VERSION "PropulsionCAN"

NS_ :

BS_ :

BU_ :  BECM CDD EGSM ETC IHU TMCU XCU ZCUD

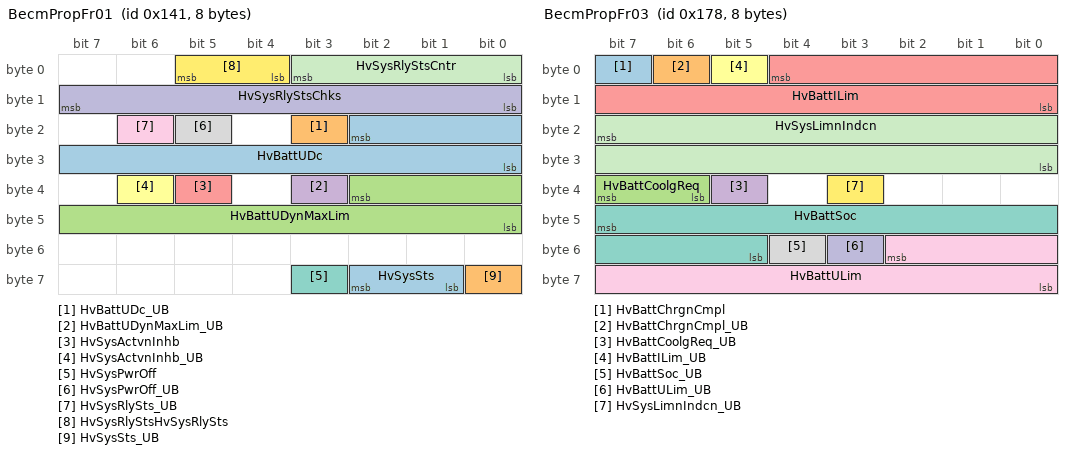
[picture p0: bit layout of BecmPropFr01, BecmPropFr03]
BO_ 321 BecmPropFr01 : 8 XCU
 SG_ HvBattUDc : 18|11@0+ (0.25,0.0) [0.0|511.0] "Volt" CDD,IHU
 SG_ HvBattUDc_UB : 19|1@0+ (1,0) [0|1] "" CDD,IHU
 SG_ HvBattUDynMaxLim : 34|11@0+ (0.25,0.0) [0.0|511.0] "Volt" IHU
 SG_ HvBattUDynMaxLim_UB : 35|1@0+ (1,0) [0|1] "" IHU
 SG_ HvSysActvnInhb : 37|1@0+ (1,0) [0|1] "" IHU
 SG_ HvSysActvnInhb_UB : 38|1@0+ (1,0) [0|1] "" IHU
 SG_ HvSysPwrOff : 59|1@0+ (1,0) [0|1] "" IHU
 SG_ HvSysPwrOff_UB : 21|1@0+ (1,0) [0|1] "" IHU
 SG_ HvSysRlySts_UB : 22|1@0+ (1,0) [0|1] "" BECM,CDD,IHU,ZCUD
 SG_ HvSysRlyStsChks : 15|8@0+ (1.0,0.0) [0.0|255.0] "Unitless" BECM,CDD,IHU,ZCUD
 SG_ HvSysRlyStsCntr : 3|4@0+ (1.0,0.0) [0.0|15.0] "Unitless" BECM,CDD,IHU,ZCUD
 SG_ HvSysRlyStsHvSysRlySts : 5|2@0+ (1,0) [0|3] "" BECM,CDD,IHU,ZCUD
 SG_ HvSysSts : 58|2@0+ (1,0) [0|3] "" IHU
 SG_ HvSysSts_UB : 56|1@0+ (1,0) [0|1] "" IHU

BO_ 373 BecmPropFr02 : 8 XCU
 SG_ HvBattUDynMinLim : 26|11@0+ (0.25,0.0) [0.0|511.0] "Volt" IHU
 SG_ HvBattUDynMinLim_UB : 27|1@0+ (1,0) [0|1] "" IHU
 SG_ MaintainBattTFb : 59|2@0+ (1,0) [0|3] "" IHU
 SG_ MaintainBattTFb_UB : 57|1@0+ (1,0) [0|1] "" IHU

BO_ 376 BecmPropFr03 : 8 XCU
 SG_ HvBattChrgnCmpl : 7|1@0+ (1,0) [0|1] "" CDD,IHU
 SG_ HvBattChrgnCmpl_UB : 6|1@0+ (1,0) [0|1] "" CDD,IHU
 SG_ HvBattCoolgReq : 39|2@0+ (1,0) [0|3] "" IHU
 SG_ HvBattCoolgReq_UB : 37|1@0+ (1,0) [0|1] "" IHU
 SG_ HvBattILim : 4|13@0+ (0.1,0.0) [0.0|819.1] "A" IHU
 SG_ HvBattILim_UB : 5|1@0+ (1,0) [0|1] "" IHU
 SG_ HvBattSoc : 47|11@0+ (0.05,0.0) [0.0|100.0] "%" IHU,ZCUD
 SG_ HvBattSoc_UB : 52|1@0+ (1,0) [0|1] "" IHU,ZCUD
 SG_ HvBattULim : 50|11@0+ (0.25,0.0) [0.0|511.0] "Volt" CDD,IHU
 SG_ HvBattULim_UB : 51|1@0+ (1,0) [0|1] "" CDD,IHU
 SG_ HvSysLimnIndcn : 23|16@0+ (1.0,0.0) [0.0|65535.0] "Unitless" IHU
 SG_ HvSysLimnIndcn_UB : 35|1@0+ (1,0) [0|1] "" IHU

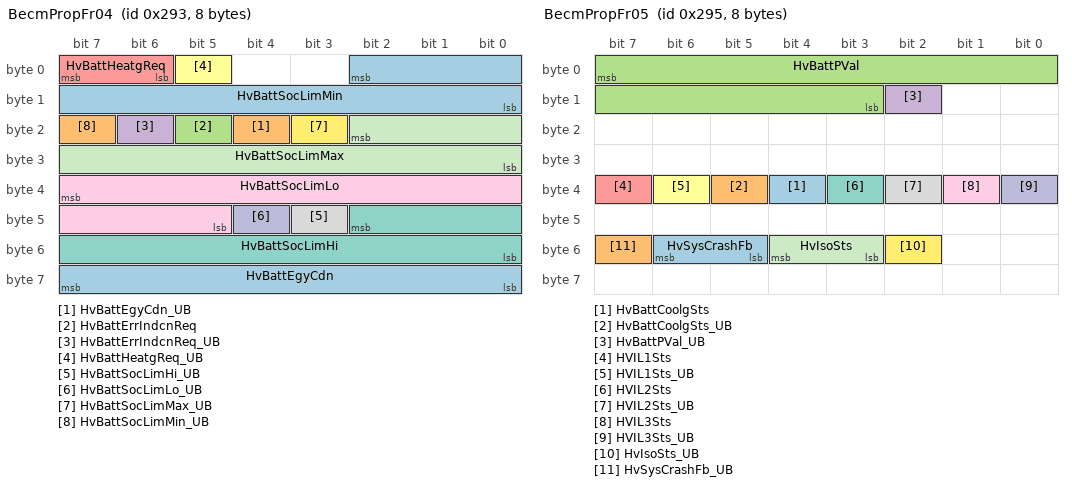
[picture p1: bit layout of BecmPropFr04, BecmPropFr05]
BO_ 659 BecmPropFr04 : 8 XCU
 SG_ HvBattEgyCdn : 63|8@0+ (0.5,0.0) [0.0|100.0] "%" IHU
 SG_ HvBattEgyCdn_UB : 20|1@0+ (1,0) [0|1] "" IHU
 SG_ HvBattErrIndcnReq : 21|1@0+ (1,0) [0|1] "" IHU
 SG_ HvBattErrIndcnReq_UB : 22|1@0+ (1,0) [0|1] "" IHU
 SG_ HvBattHeatgReq : 7|2@0+ (1,0) [0|3] "" IHU,ZCUD
 SG_ HvBattHeatgReq_UB : 5|1@0+ (1,0) [0|1] "" IHU,ZCUD
 SG_ HvBattSocLimHi : 42|11@0+ (0.05,0.0) [0.0|100.0] "%" IHU
 SG_ HvBattSocLimHi_UB : 43|1@0+ (1,0) [0|1] "" IHU
 SG_ HvBattSocLimLo : 39|11@0+ (0.05,0.0) [0.0|100.0] "%" IHU,ZCUD
 SG_ HvBattSocLimLo_UB : 44|1@0+ (1,0) [0|1] "" IHU,ZCUD
 SG_ HvBattSocLimMax : 18|11@0+ (0.05,0.0) [0.0|100.0] "%" IHU
 SG_ HvBattSocLimMax_UB : 19|1@0+ (1,0) [0|1] "" IHU
 SG_ HvBattSocLimMin : 2|11@0+ (0.05,0.0) [0.0|100.0] "%" IHU
 SG_ HvBattSocLimMin_UB : 23|1@0+ (1,0) [0|1] "" IHU

BO_ 661 BecmPropFr05 : 8 XCU
 SG_ HvBattCoolgSts : 36|1@0+ (1,0) [0|1] "" IHU
 SG_ HvBattCoolgSts_UB : 37|1@0+ (1,0) [0|1] "" IHU
 SG_ HvBattPVal : 7|13@0+ (0.05,0.0) [0.0|409.55] "KiloPa" Vector__XXX
 SG_ HvBattPVal_UB : 10|1@0+ (1,0) [0|1] "" Vector__XXX
 SG_ HVIL1Sts : 39|1@0+ (1,0) [0|1] "" Vector__XXX
 SG_ HVIL1Sts_UB : 38|1@0+ (1,0) [0|1] "" Vector__XXX
 SG_ HVIL2Sts : 35|1@0+ (1,0) [0|1] "" IHU
 SG_ HVIL2Sts_UB : 34|1@0+ (1,0) [0|1] "" IHU
 SG_ HVIL3Sts : 33|1@0+ (1,0) [0|1] "" IHU
 SG_ HVIL3Sts_UB : 32|1@0+ (1,0) [0|1] "" IHU
 SG_ HvIsoSts : 52|2@0+ (1,0) [0|3] "" IHU
 SG_ HvIsoSts_UB : 50|1@0+ (1,0) [0|1] "" IHU
 SG_ HvSysCrashFb : 54|2@0+ (1,0) [0|3] "" IHU,ZCUD
 SG_ HvSysCrashFb_UB : 55|1@0+ (1,0) [0|1] "" IHU,ZCUD

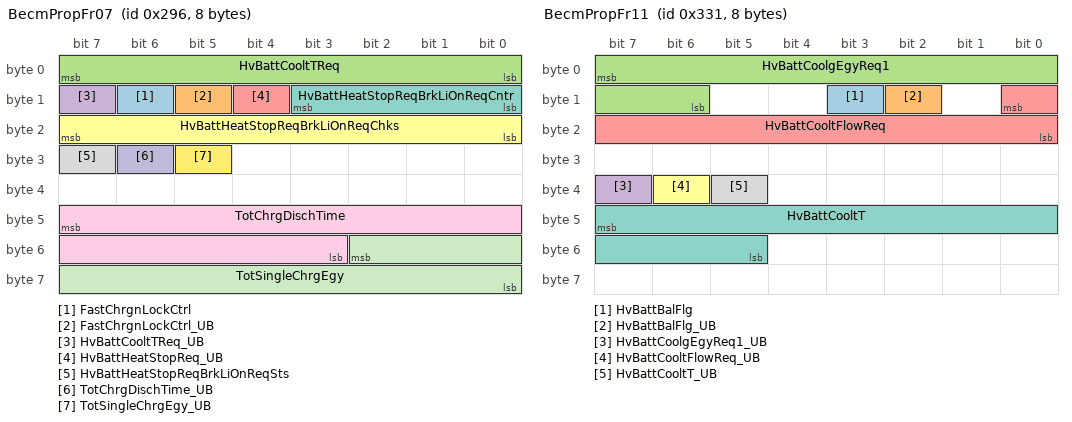
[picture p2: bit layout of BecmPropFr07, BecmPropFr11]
BO_ 662 BecmPropFr07 : 8 XCU
 SG_ FastChrgnLockCtrl : 14|1@0+ (1,0) [0|1] "" CDD,IHU
 SG_ FastChrgnLockCtrl_UB : 13|1@0+ (1,0) [0|1] "" CDD,IHU
 SG_ HvBattCooltTReq : 7|8@0+ (1.0,-50.0) [-50.0|200.0] "degC" IHU
 SG_ HvBattCooltTReq_UB : 15|1@0+ (1,0) [0|1] "" IHU
 SG_ HvBattHeatStopReq_UB : 12|1@0+ (1,0) [0|1] "" IHU
 SG_ HvBattHeatStopReqBrkLiOnReqChks : 23|8@0+ (1.0,0.0) [0.0|255.0] "Unitless" IHU
 SG_ HvBattHeatStopReqBrkLiOnReqCntr : 11|4@0+ (1.0,0.0) [0.0|15.0] "Unitless" IHU
 SG_ HvBattHeatStopReqBrkLiOnReqSts : 31|1@0+ (1,0) [0|1] "" IHU
 SG_ TotChrgDischTime : 47|13@0+ (1.0,0.0) [0.0|8191.0] "Unitless" IHU
 SG_ TotChrgDischTime_UB : 30|1@0+ (1,0) [0|1] "" IHU
 SG_ TotSingleChrgEgy : 50|11@0+ (0.1,0.0) [0.0|204.70000000000002] "KwH_1" IHU
 SG_ TotSingleChrgEgy_UB : 29|1@0+ (1,0) [0|1] "" IHU

BO_ 834 BecmPropFr08 : 8 XCU
 SG_ HvBattCodLen : 23|8@0+ (1.0,0.0) [0.0|250.0] "Unitless" IHU
 SG_ HvBattCodLen_UB : 39|1@0+ (1,0) [0|1] "" IHU
 SG_ HvBattMismatchFlt : 7|1@0+ (1,0) [0|1] "" IHU
 SG_ HvBattMismatchFlt_UB : 38|1@0+ (1,0) [0|1] "" IHU
 SG_ HvBattNr : 31|8@0+ (1.0,0.0) [0.0|250.0] "Unitless" IHU
 SG_ HvBattNr_UB : 37|1@0+ (1,0) [0|1] "" IHU
 SG_ HvCellTDifFlt : 6|2@0+ (1,0) [0|3] "" IHU
 SG_ HvCellTDifFlt_UB : 4|1@0+ (1,0) [0|1] "" IHU
 SG_ HvCellTOverFlt : 55|2@0+ (1,0) [0|3] "" IHU
 SG_ HvCellTOverFlt_UB : 35|1@0+ (1,0) [0|1] "" IHU
 SG_ HvCellUDifFlt : 3|2@0+ (1,0) [0|3] "" IHU
 SG_ HvCellUDifFlt_UB : 1|1@0+ (1,0) [0|1] "" IHU
 SG_ HvCellUOverFlt : 53|2@0+ (1,0) [0|3] "" IHU
 SG_ HvCellUOverFlt_UB : 34|1@0+ (1,0) [0|1] "" IHU
 SG_ HvCellUUnderFlt : 15|2@0+ (1,0) [0|3] "" IHU
 SG_ HvCellUUnderFlt_UB : 33|1@0+ (1,0) [0|1] "" IHU
 SG_ HvilFlt : 0|1@0+ (1,0) [0|1] "" IHU
 SG_ HvilFlt_UB : 42|1@0+ (1,0) [0|1] "" IHU
 SG_ HvIsoFlt : 13|2@0+ (1,0) [0|3] "" IHU
 SG_ HvIsoFlt_UB : 41|1@0+ (1,0) [0|1] "" IHU
 SG_ HvPackOverChrgFlt : 11|2@0+ (1,0) [0|3] "" IHU
 SG_ HvPackOverChrgFlt_UB : 40|1@0+ (1,0) [0|1] "" IHU
 SG_ HvPackUOverFlt : 9|2@0+ (1,0) [0|3] "" IHU
 SG_ HvPackUOverFlt_UB : 36|1@0+ (1,0) [0|1] "" IHU
 SG_ HvPackUUnderFlt : 47|2@0+ (1,0) [0|3] "" IHU
 SG_ HvPackUUnderFlt_UB : 32|1@0+ (1,0) [0|1] "" IHU
 SG_ HvSocHiFlt : 63|2@0+ (1,0) [0|3] "" IHU
 SG_ HvSocHiFlt_UB : 48|1@0+ (1,0) [0|1] "" IHU
 SG_ HvSocHopFlt : 45|2@0+ (1,0) [0|3] "" IHU
 SG_ HvSocHopFlt_UB : 43|1@0+ (1,0) [0|1] "" IHU
 SG_ HvSocLoFlt : 51|2@0+ (1,0) [0|3] "" IHU
 SG_ HvSocLoFlt_UB : 49|1@0+ (1,0) [0|1] "" IHU

BO_ 789 BecmPropFr09 : 8 XCU
 SG_ HvBattChrgnSts : 56|1@0+ (1,0) [0|1] "" IHU
 SG_ HvBattChrgnSts_UB : 57|1@0+ (1,0) [0|1] "" IHU
 SG_ HvBattT_UB : 7|1@0+ (1,0) [0|1] "" IHU
 SG_ HvBattTAvg : 6|13@0- (0.1,0.0) [-256.0|255.9] "degC" IHU
 SG_ HvBattTMax : 9|13@0- (0.1,0.0) [-256.0|255.9] "degC" IHU
 SG_ HvBattTMin : 28|13@0- (0.1,0.0) [-256.0|255.9] "degC" IHU

BO_ 817 BecmPropFr11 : 8 XCU
 SG_ HvBattBalFlg : 11|1@0+ (1,0) [0|1] "" Vector__XXX
 SG_ HvBattBalFlg_UB : 10|1@0+ (1,0) [0|1] "" Vector__XXX
 SG_ HvBattCoolgEgyReq1 : 7|10@0+ (20.0,0.0) [0.0|20460.0] "Wh" IHU
 SG_ HvBattCoolgEgyReq1_UB : 39|1@0+ (1,0) [0|1] "" IHU
 SG_ HvBattCooltFlowReq : 8|9@0+ (0.1,0.0) [0.0|51.1] "L / min" IHU
 SG_ HvBattCooltFlowReq_UB : 38|1@0+ (1,0) [0|1] "" IHU
 SG_ HvBattCooltT : 47|11@0+ (0.1,-60.0) [-60.0|125.0] "degC" IHU
 SG_ HvBattCooltT_UB : 37|1@0+ (1,0) [0|1] "" IHU

BO_ 769 BecmPropFr12 : 8 XCU
 SG_ DCChaPwrAct : 50|11@0+ (0.25,0.0) [0.0|511.75] "kW" IHU
 SG_ DCChaPwrAct_UB : 51|1@0+ (1,0) [0|1] "" IHU
 SG_ HvBattPwrCdn : 7|8@0+ (0.5,0.0) [0.0|100.0] "%" IHU
 SG_ HvBattPwrCdn_UB : 15|1@0+ (1,0) [0|1] "" IHU

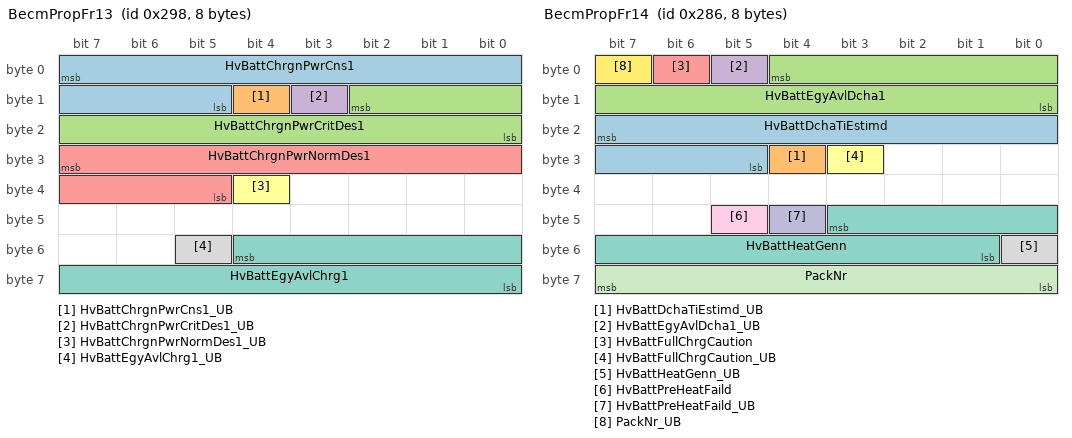
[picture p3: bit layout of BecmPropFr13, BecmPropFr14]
BO_ 664 BecmPropFr13 : 8 XCU
 SG_ HvBattChrgnPwrCns1 : 7|11@0+ (100.0,0.0) [0.0|204700.0] "W" IHU
 SG_ HvBattChrgnPwrCns1_UB : 12|1@0+ (1,0) [0|1] "" IHU
 SG_ HvBattChrgnPwrCritDes1 : 10|11@0+ (100.0,0.0) [0.0|204700.0] "W" IHU
 SG_ HvBattChrgnPwrCritDes1_UB : 11|1@0+ (1,0) [0|1] "" IHU
 SG_ HvBattChrgnPwrNormDes1 : 31|11@0+ (100.0,0.0) [0.0|204700.0] "W" IHU
 SG_ HvBattChrgnPwrNormDes1_UB : 36|1@0+ (1,0) [0|1] "" IHU
 SG_ HvBattEgyAvlChrg1 : 52|13@0+ (20.0,0.0) [0.0|163820.0] "Wh" IHU
 SG_ HvBattEgyAvlChrg1_UB : 53|1@0+ (1,0) [0|1] "" IHU

BO_ 646 BecmPropFr14 : 8 XCU
 SG_ HvBattDchaTiEstimd : 23|11@0+ (1.0,0.0) [0.0|2047.0] "Mins" IHU
 SG_ HvBattDchaTiEstimd_UB : 28|1@0+ (1,0) [0|1] "" IHU
 SG_ HvBattEgyAvlDcha1 : 4|13@0+ (20.0,0.0) [0.0|163820.0] "Wh" IHU
 SG_ HvBattEgyAvlDcha1_UB : 5|1@0+ (1,0) [0|1] "" IHU
 SG_ HvBattFullChrgCaution : 6|1@0+ (1,0) [0|1] "" IHU
 SG_ HvBattFullChrgCaution_UB : 27|1@0+ (1,0) [0|1] "" IHU
 SG_ HvBattHeatGenn : 43|11@0+ (100.0,0.0) [0.0|204700.0] "W" IHU
 SG_ HvBattHeatGenn_UB : 48|1@0+ (1,0) [0|1] "" IHU
 SG_ HvBattPreHeatFaild : 45|1@0+ (1,0) [0|1] "" IHU
 SG_ HvBattPreHeatFaild_UB : 44|1@0+ (1,0) [0|1] "" IHU
 SG_ PackNr : 63|8@0+ (1.0,0.0) [0.0|250.0] "Unitless" IHU
 SG_ PackNr_UB : 7|1@0+ (1,0) [0|1] "" IHU

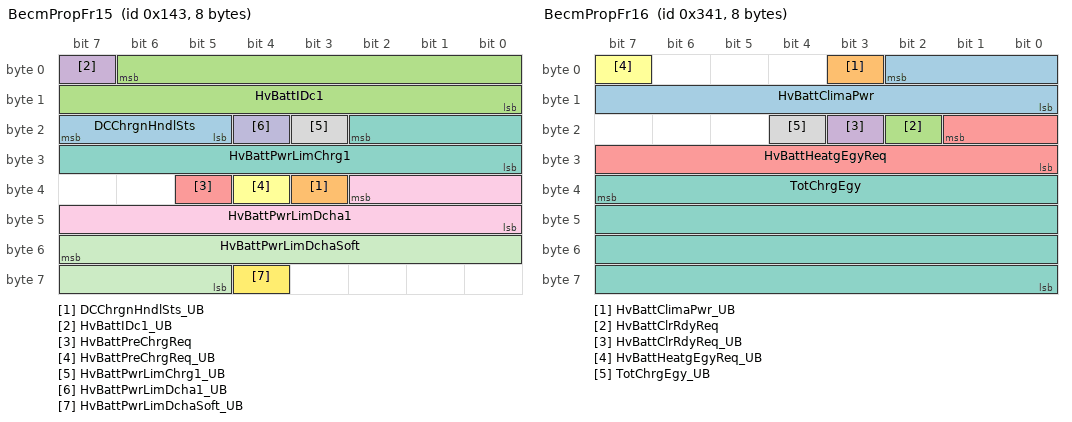
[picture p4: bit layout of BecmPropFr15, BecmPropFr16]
BO_ 323 BecmPropFr15 : 8 XCU
 SG_ DCChrgnHndlSts : 23|3@0+ (1,0) [0|7] "" IHU,ZCUD
 SG_ DCChrgnHndlSts_UB : 35|1@0+ (1,0) [0|1] "" IHU,ZCUD
 SG_ HvBattIDc1 : 6|15@0+ (0.1,-1638.0) [-1638.0|1638.7000000000003] "A" IHU
 SG_ HvBattIDc1_UB : 7|1@0+ (1,0) [0|1] "" IHU
 SG_ HvBattPreChrgReq : 37|1@0+ (1,0) [0|1] "" CDD
 SG_ HvBattPreChrgReq_UB : 36|1@0+ (1,0) [0|1] "" CDD
 SG_ HvBattPwrLimChrg1 : 18|11@0+ (0.25,0.0) [0.0|511.75] "kW" IHU
 SG_ HvBattPwrLimChrg1_UB : 19|1@0+ (1,0) [0|1] "" IHU
 SG_ HvBattPwrLimDcha1 : 34|11@0+ (0.25,0.0) [0.0|511.75] "kW" IHU
 SG_ HvBattPwrLimDcha1_UB : 20|1@0+ (1,0) [0|1] "" IHU
 SG_ HvBattPwrLimDchaSoft : 55|11@0+ (0.25,0.0) [0.0|511.75] "kW" IHU
 SG_ HvBattPwrLimDchaSoft_UB : 60|1@0+ (1,0) [0|1] "" IHU

BO_ 833 BecmPropFr16 : 8 XCU
 SG_ HvBattClimaPwr : 2|11@0+ (100.0,0.0) [0.0|204700.0] "W" IHU
 SG_ HvBattClimaPwr_UB : 3|1@0+ (1,0) [0|1] "" IHU
 SG_ HvBattClrRdyReq : 18|1@0+ (1,0) [0|1] "" IHU
 SG_ HvBattClrRdyReq_UB : 19|1@0+ (1,0) [0|1] "" IHU
 SG_ HvBattHeatgEgyReq : 17|10@0+ (20.0,0.0) [0.0|20460.0] "Wh" IHU
 SG_ HvBattHeatgEgyReq_UB : 7|1@0+ (1,0) [0|1] "" IHU
 SG_ TotChrgEgy : 39|32@0+ (1.0,0.0) [0.0|4294967295.0] "Unitless" Vector__XXX
 SG_ TotChrgEgy_UB : 20|1@0+ (1,0) [0|1] "" Vector__XXX

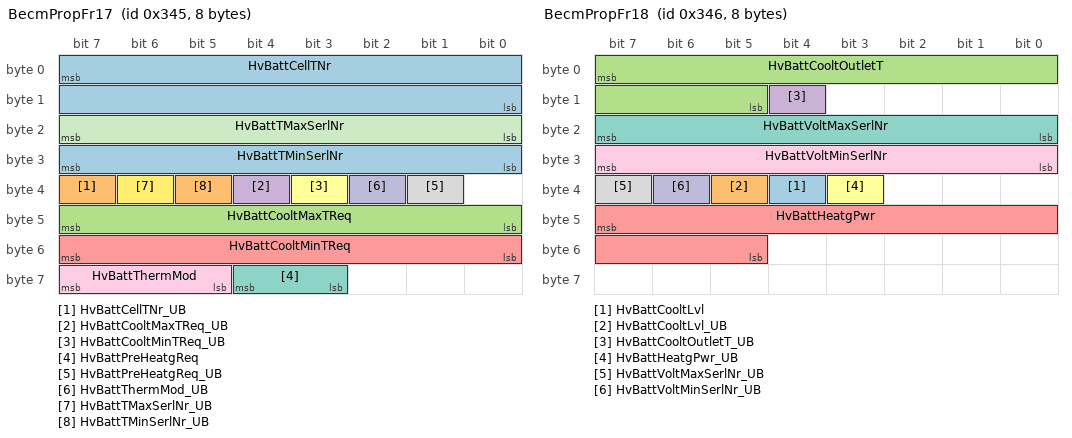
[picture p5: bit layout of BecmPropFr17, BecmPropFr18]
BO_ 837 BecmPropFr17 : 8 XCU
 SG_ HvBattCellTNr : 7|16@0+ (1.0,0.0) [0.0|65531.0] "Unitless" IHU
 SG_ HvBattCellTNr_UB : 39|1@0+ (1,0) [0|1] "" IHU
 SG_ HvBattCooltMaxTReq : 47|8@0+ (1.0,-50.0) [-50.0|200.0] "degC" IHU
 SG_ HvBattCooltMaxTReq_UB : 36|1@0+ (1,0) [0|1] "" IHU
 SG_ HvBattCooltMinTReq : 55|8@0+ (1.0,-50.0) [-50.0|200.0] "degC" IHU
 SG_ HvBattCooltMinTReq_UB : 35|1@0+ (1,0) [0|1] "" IHU
 SG_ HvBattPreHeatgReq : 60|2@0+ (1,0) [0|3] "" CDD,IHU
 SG_ HvBattPreHeatgReq_UB : 33|1@0+ (1,0) [0|1] "" CDD,IHU
 SG_ HvBattThermMod : 63|3@0+ (1,0) [0|7] "" IHU
 SG_ HvBattThermMod_UB : 34|1@0+ (1,0) [0|1] "" IHU
 SG_ HvBattTMaxSerlNr : 23|8@0+ (1.0,0.0) [0.0|250.0] "Unitless" IHU
 SG_ HvBattTMaxSerlNr_UB : 38|1@0+ (1,0) [0|1] "" IHU
 SG_ HvBattTMinSerlNr : 31|8@0+ (1.0,0.0) [0.0|250.0] "Unitless" Vector__XXX
 SG_ HvBattTMinSerlNr_UB : 37|1@0+ (1,0) [0|1] "" Vector__XXX

BO_ 838 BecmPropFr18 : 8 XCU
 SG_ HvBattCooltLvl : 36|1@0+ (1,0) [0|1] "" IHU
 SG_ HvBattCooltLvl_UB : 37|1@0+ (1,0) [0|1] "" IHU
 SG_ HvBattCooltOutletT : 7|11@0+ (0.1,-60.0) [-60.0|125.0] "degC" IHU
 SG_ HvBattCooltOutletT_UB : 12|1@0+ (1,0) [0|1] "" IHU
 SG_ HvBattHeatgPwr : 47|11@0+ (100.0,0.0) [0.0|204700.0] "W" IHU
 SG_ HvBattHeatgPwr_UB : 35|1@0+ (1,0) [0|1] "" IHU
 SG_ HvBattVoltMaxSerlNr : 23|8@0+ (1.0,0.0) [0.0|250.0] "Unitless" IHU
 SG_ HvBattVoltMaxSerlNr_UB : 39|1@0+ (1,0) [0|1] "" IHU
 SG_ HvBattVoltMinSerlNr : 31|8@0+ (1.0,0.0) [0.0|250.0] "Unitless" Vector__XXX
 SG_ HvBattVoltMinSerlNr_UB : 38|1@0+ (1,0) [0|1] "" Vector__XXX

BO_ 839 BecmPropFr19 : 8 XCU
 SG_ HvBattCod_UB : 63|1@0+ (1,0) [0|1] "" IHU
 SG_ HvBattCodPackCodeX1 : 7|8@0+ (1.0,0.0) [0.0|255.0] "Unitless" IHU
 SG_ HvBattCodPackCodeX2 : 15|8@0+ (1.0,0.0) [0.0|255.0] "Unitless" IHU
 SG_ HvBattCodPackCodeX3 : 23|8@0+ (1.0,0.0) [0.0|255.0] "Unitless" IHU
 SG_ HvBattCodPackCodeX4 : 31|8@0+ (1.0,0.0) [0.0|255.0] "Unitless" IHU
 SG_ HvBattCodPackCodeX5 : 39|8@0+ (1.0,0.0) [0.0|255.0] "Unitless" IHU
 SG_ HvBattCodPackCodeX6 : 47|8@0+ (1.0,0.0) [0.0|255.0] "Unitless" IHU
 SG_ HvBattCodPackIndex : 55|8@0+ (1.0,0.0) [0.0|255.0] "Unitless" IHU

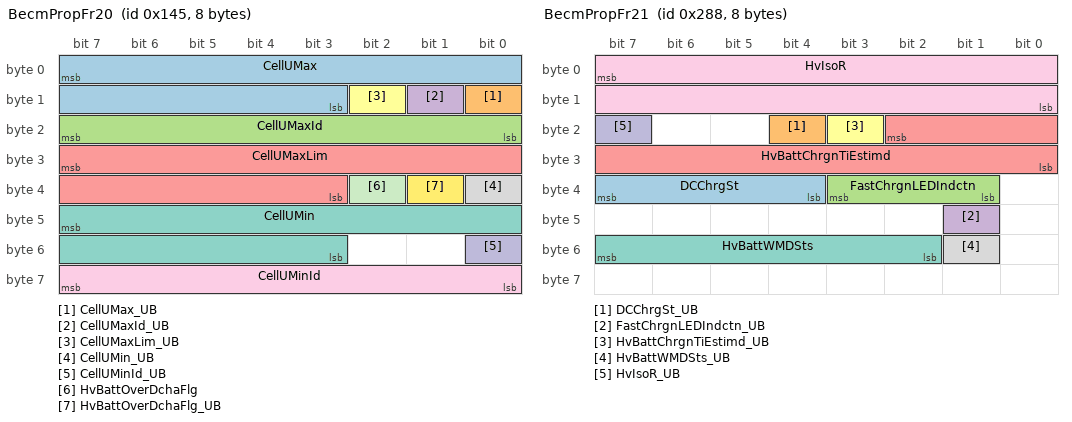
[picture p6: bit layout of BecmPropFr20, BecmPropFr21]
BO_ 325 BecmPropFr20 : 8 XCU
 SG_ CellUMax : 7|13@0+ (0.001,0.0) [0.0|5.0] "Volt" IHU
 SG_ CellUMax_UB : 8|1@0+ (1,0) [0|1] "" IHU
 SG_ CellUMaxId : 23|8@0+ (1.0,0.0) [0.0|250.0] "Unitless" IHU
 SG_ CellUMaxId_UB : 9|1@0+ (1,0) [0|1] "" IHU
 SG_ CellUMaxLim : 31|13@0+ (0.001,0.0) [0.0|5.0] "Volt" IHU
 SG_ CellUMaxLim_UB : 10|1@0+ (1,0) [0|1] "" IHU
 SG_ CellUMin : 47|13@0+ (0.001,0.0) [0.0|5.0] "Volt" IHU
 SG_ CellUMin_UB : 32|1@0+ (1,0) [0|1] "" IHU
 SG_ CellUMinId : 63|8@0+ (1.0,0.0) [0.0|250.0] "Unitless" IHU
 SG_ CellUMinId_UB : 48|1@0+ (1,0) [0|1] "" IHU
 SG_ HvBattOverDchaFlg : 34|1@0+ (1,0) [0|1] "" IHU
 SG_ HvBattOverDchaFlg_UB : 33|1@0+ (1,0) [0|1] "" IHU

BO_ 648 BecmPropFr21 : 8 XCU
 SG_ DCChrgSt : 39|4@0+ (1,0) [0|15] "" IHU,ZCUD
 SG_ DCChrgSt_UB : 20|1@0+ (1,0) [0|1] "" IHU,ZCUD
 SG_ FastChrgnLEDIndctn : 35|3@0+ (1,0) [0|7] "" CDD,IHU
 SG_ FastChrgnLEDIndctn_UB : 41|1@0+ (1,0) [0|1] "" CDD,IHU
 SG_ HvBattChrgnTiEstimd : 18|11@0+ (1.0,0.0) [0.0|2047.0] "Mins" IHU
 SG_ HvBattChrgnTiEstimd_UB : 19|1@0+ (1,0) [0|1] "" IHU
 SG_ HvBattWMDSts : 55|6@0+ (1.0,0.0) [0.0|63.0] "Unitless" IHU,ZCUD
 SG_ HvBattWMDSts_UB : 49|1@0+ (1,0) [0|1] "" IHU,ZCUD
 SG_ HvIsoR : 7|16@0+ (1.0,0.0) [0.0|60000.0] "kOhm" IHU
 SG_ HvIsoR_UB : 23|1@0+ (1,0) [0|1] "" IHU

BO_ 83 BecmPropFr22 : 8 XCU
 SG_ CPSRU : 39|8@0+ (0.1,0.0) [0.0|25.0] "Volt" IHU
 SG_ CPSRU_UB : 24|1@0+ (1,0) [0|1] "" IHU

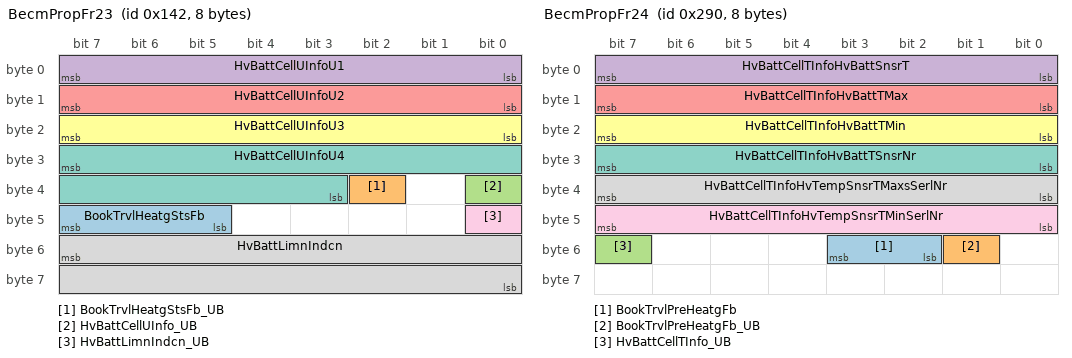
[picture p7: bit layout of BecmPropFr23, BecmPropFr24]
BO_ 322 BecmPropFr23 : 8 XCU
 SG_ BookTrvlHeatgStsFb : 47|3@0+ (1,0) [0|7] "" IHU
 SG_ BookTrvlHeatgStsFb_UB : 34|1@0+ (1,0) [0|1] "" IHU
 SG_ HvBattCellUInfo_UB : 32|1@0+ (1,0) [0|1] "" IHU
 SG_ HvBattCellUInfoU1 : 7|8@0+ (1.0,0.0) [0.0|255.0] "Unitless" IHU
 SG_ HvBattCellUInfoU2 : 15|8@0+ (1.0,0.0) [0.0|255.0] "Unitless" IHU
 SG_ HvBattCellUInfoU3 : 23|8@0+ (1.0,0.0) [0.0|255.0] "Unitless" IHU
 SG_ HvBattCellUInfoU4 : 31|13@0+ (1.0,0.0) [0.0|8191.0] "Unitless" IHU
 SG_ HvBattLimnIndcn : 55|16@0+ (1.0,0.0) [0.0|65535.0] "Unitless" IHU,ZCUD
 SG_ HvBattLimnIndcn_UB : 40|1@0+ (1,0) [0|1] "" IHU,ZCUD

BO_ 656 BecmPropFr24 : 8 XCU
 SG_ BookTrvlPreHeatgFb : 51|2@0+ (1,0) [0|3] "" IHU
 SG_ BookTrvlPreHeatgFb_UB : 49|1@0+ (1,0) [0|1] "" IHU
 SG_ HvBattCellTInfo_UB : 55|1@0+ (1,0) [0|1] "" IHU
 SG_ HvBattCellTInfoHvBattSnsrT : 7|8@0+ (1.0,-40.0) [-40.0|215.0] "degC" IHU
 SG_ HvBattCellTInfoHvBattTMax : 15|8@0+ (1.0,-40.0) [-40.0|215.0] "degC" IHU
 SG_ HvBattCellTInfoHvBattTMin : 23|8@0+ (1.0,-40.0) [-40.0|215.0] "degC" IHU
 SG_ HvBattCellTInfoHvBattTSnsrNr : 31|8@0+ (1.0,0.0) [0.0|255.0] "Unitless" IHU
 SG_ HvBattCellTInfoHvTempSnsrTMaxsSerlNr : 39|8@0+ (1.0,0.0) [0.0|255.0] "Unitless" IHU
 SG_ HvBattCellTInfoHvTempSnsrTMinSerlNr : 47|8@0+ (1.0,0.0) [0.0|255.0] "Unitless" IHU

BO_ 1177 BecmPropFr27 : 8 XCU
 SG_ HvBattCap : 7|16@0+ (0.1,0.0) [0.0|6553.5] "Ah" IHU
 SG_ HvBattCap_UB : 23|1@0+ (1,0) [0|1] "" IHU
 SG_ TotChrgCap : 39|32@0+ (0.01,0.0) [0.0|42949672.95] "Ah" Vector__XXX
 SG_ TotChrgCap_UB : 22|1@0+ (1,0) [0|1] "" Vector__XXX

BO_ 1180 BecmPropFr28 : 8 XCU
 SG_ TotDchaCap : 7|32@0+ (0.01,0.0) [0.0|42949672.95] "Ah" Vector__XXX
 SG_ TotDchaCap_UB : 39|1@0+ (1,0) [0|1] "" Vector__XXX

BO_ 1144 BecmPropFr30 : 8 XCU
 SG_ TotDchaEgy : 7|32@0+ (1.0,0.0) [0.0|4294967295.0] "Unitless" Vector__XXX
 SG_ TotDchaEgy_UB : 39|1@0+ (1,0) [0|1] "" Vector__XXX

BO_ 1155 BecmPropFr41 : 8 XCU
 SG_ Therunawy4GHS : 7|32@0+ (1.0,0.0) [0.0|4294967295.0] "Unitless" IHU
 SG_ Therunawy4GHS_UB : 39|1@0+ (1,0) [0|1] "" IHU

BO_ 407 BecmPropFr47 : 8 XCU
 SG_ BECMAFEComError : 7|1@0+ (1,0) [0|1] "" IHU
 SG_ BECMAFEComError_UB : 6|1@0+ (1,0) [0|1] "" IHU
 SG_ BECMBookTrvlHeatgReq : 5|2@0+ (1,0) [0|3] "" IHU
 SG_ BECMBookTrvlHeatgReq_UB : 3|1@0+ (1,0) [0|1] "" IHU
 SG_ BECMCurSampSts : 2|2@0+ (1.0,0.0) [0.0|3.0] "Unitless" IHU
 SG_ BECMCurSampSts_UB : 0|1@0+ (1,0) [0|1] "" IHU
 SG_ BECMCVSComFlt : 15|1@0+ (1,0) [0|1] "" IHU
 SG_ BECMCVSComFlt_UB : 14|1@0+ (1,0) [0|1] "" IHU
 SG_ BECMDCPreHeatgReq : 13|2@0+ (1,0) [0|3] "" IHU
 SG_ BECMDCPreHeatgReq_UB : 11|1@0+ (1,0) [0|1] "" IHU
 SG_ BECMHiVolSampSts : 10|3@0+ (1.0,0.0) [0.0|7.0] "Unitless" IHU
 SG_ BECMHiVolSampSts_UB : 23|1@0+ (1,0) [0|1] "" IHU
 SG_ BECMIsoCheckCmd : 22|1@0+ (1,0) [0|1] "" IHU
 SG_ BECMIsoCheckCmd_UB : 21|1@0+ (1,0) [0|1] "" IHU
 SG_ BECMMainNegCntSts : 20|2@0+ (1.0,0.0) [0.0|3.0] "Unitless" IHU
 SG_ BECMMainNegCntSts_UB : 18|1@0+ (1,0) [0|1] "" IHU
 SG_ BECMMainPosCntSts : 17|2@0+ (1.0,0.0) [0.0|3.0] "Unitless" IHU
 SG_ BECMMainPosCntSts_UB : 31|1@0+ (1,0) [0|1] "" IHU
 SG_ BECMPreChrgCntSts : 30|2@0+ (1.0,0.0) [0.0|3.0] "Unitless" IHU
 SG_ BECMPreChrgCntSts_UB : 28|1@0+ (1,0) [0|1] "" IHU
 SG_ BECMPwrLimtLvl : 39|16@0+ (1.0,0.0) [0.0|65535.0] "Unitless" IHU
 SG_ BECMPwrLimtLvl_UB : 27|1@0+ (1,0) [0|1] "" IHU
 SG_ BECMSupplyVoltKL30 : 55|8@0+ (1.0,0.0) [0.0|255.0] "Unitless" IHU
 SG_ BECMSupplyVoltKL30_UB : 26|1@0+ (1,0) [0|1] "" IHU
 SG_ BECMSysMod : 63|6@0+ (1.0,0.0) [0.0|63.0] "Unitless" IHU
 SG_ BECMSysMod_UB : 25|1@0+ (1,0) [0|1] "" IHU

BO_ 390 BecmPropFr48 : 8 XCU
 SG_ FIDChargerFault : 39|1@0+ (1,0) [0|1] "" IHU
 SG_ FIDChargerFault_UB : 16|1@0+ (1,0) [0|1] "" IHU
 SG_ FIDCRASHEVENT : 38|1@0+ (1,0) [0|1] "" IHU
 SG_ FIDCRASHEVENT_UB : 37|1@0+ (1,0) [0|1] "" IHU
 SG_ FIDCVTNUNSTABLE : 36|1@0+ (1,0) [0|1] "" IHU
 SG_ FIDCVTNUNSTABLE_UB : 35|1@0+ (1,0) [0|1] "" IHU
 SG_ FIDDONOTCONNECT : 34|1@0+ (1,0) [0|1] "" IHU
 SG_ FIDDONOTCONNECT_UB : 33|1@0+ (1,0) [0|1] "" IHU
 SG_ FIDECMSINGALMISS : 32|1@0+ (1,0) [0|1] "" IHU
 SG_ FIDECMSINGALMISS_UB : 47|1@0+ (1,0) [0|1] "" IHU
 SG_ FIDHvBattFaultIndcr : 46|1@0+ (1,0) [0|1] "" IHU
 SG_ FIDHvBattFaultIndcr_UB : 45|1@0+ (1,0) [0|1] "" IHU
 SG_ FIDHvPwrOff : 44|1@0+ (1,0) [0|1] "" IHU
 SG_ FIDHvPwrOff_UB : 43|1@0+ (1,0) [0|1] "" IHU
 SG_ FIDHVSOONUNAVAIL : 42|1@0+ (1,0) [0|1] "" IHU
 SG_ FIDHVSOONUNAVAIL_UB : 41|1@0+ (1,0) [0|1] "" IHU
 SG_ FIDInhibitNonbasicThrmReq : 40|1@0+ (1,0) [0|1] "" IHU
 SG_ FIDInhibitNonbasicThrmReq_UB : 55|1@0+ (1,0) [0|1] "" IHU
 SG_ FIDINHIBITSELFTEST : 54|1@0+ (1,0) [0|1] "" IHU
 SG_ FIDINHIBITSELFTEST_UB : 53|1@0+ (1,0) [0|1] "" IHU
 SG_ FIDInhibitThermalRequest : 52|1@0+ (1,0) [0|1] "" IHU
 SG_ FIDInhibitThermalRequest_UB : 51|1@0+ (1,0) [0|1] "" IHU
 SG_ FIDINSTANTDISCONNECTION : 50|1@0+ (1,0) [0|1] "" IHU
 SG_ FIDINSTANTDISCONNECTION_UB : 49|1@0+ (1,0) [0|1] "" IHU
 SG_ FIDLVFault : 48|1@0+ (1,0) [0|1] "" IHU
 SG_ FIDLVFault_UB : 63|1@0+ (1,0) [0|1] "" IHU
 SG_ FIDMPMCURDATA : 62|1@0+ (1,0) [0|1] "" IHU
 SG_ FIDMPMCURDATA_UB : 61|1@0+ (1,0) [0|1] "" IHU
 SG_ FIDMPMCVTNDATA : 60|1@0+ (1,0) [0|1] "" IHU
 SG_ FIDMPMCVTNDATA_UB : 59|1@0+ (1,0) [0|1] "" IHU
 SG_ FIDNOBalance : 58|1@0+ (1,0) [0|1] "" IHU
 SG_ FIDNOBalance_UB : 57|1@0+ (1,0) [0|1] "" IHU
 SG_ FIDNOCHARGING : 24|1@0+ (1,0) [0|1] "" IHU
 SG_ FIDNOCHARGING_UB : 56|1@0+ (1,0) [0|1] "" IHU
 SG_ FIDNOCONNECTION : 25|1@0+ (1,0) [0|1] "" IHU
 SG_ FIDNOCONNECTION_UB : 26|1@0+ (1,0) [0|1] "" IHU
 SG_ FIDNoDCCharging : 27|1@0+ (1,0) [0|1] "" IHU
 SG_ FIDNoDCCharging_UB : 28|1@0+ (1,0) [0|1] "" IHU
 SG_ FIDNoDischarging : 29|1@0+ (1,0) [0|1] "" IHU
 SG_ FIDNoDischarging_UB : 30|1@0+ (1,0) [0|1] "" IHU
 SG_ FIDNORESTARTMESSAGE : 31|1@0+ (1,0) [0|1] "" IHU
 SG_ FIDNORESTARTMESSAGE_UB : 17|1@0+ (1,0) [0|1] "" IHU
 SG_ FIDSevereDCChargerFault : 18|1@0+ (1,0) [0|1] "" IHU
 SG_ FIDSevereDCChargerFault_UB : 19|1@0+ (1,0) [0|1] "" IHU
 SG_ FIDSTOPSAFELY : 20|1@0+ (1,0) [0|1] "" IHU
 SG_ FIDSTOPSAFELY_UB : 21|1@0+ (1,0) [0|1] "" IHU
 SG_ FIDSYSTEMISOLATIONTEST : 22|1@0+ (1,0) [0|1] "" IHU
 SG_ FIDSYSTEMISOLATIONTEST_UB : 23|1@0+ (1,0) [0|1] "" IHU
 SG_ FIDUDCMODE : 8|1@0+ (1,0) [0|1] "" IHU
 SG_ FIDUDCMODE_UB : 9|1@0+ (1,0) [0|1] "" IHU

BO_ 404 BecmPropFr49 : 8 XCU
 SG_ BECMSwVersion : 7|21@0+ (1.0,0.0) [0.0|2097151.0] "Unitless" IHU
 SG_ BECMSwVersion_UB : 18|1@0+ (1,0) [0|1] "" IHU
 SG_ BECMUCPSRKL15 : 63|8@0+ (1.0,0.0) [0.0|255.0] "Unitless" IHU
 SG_ BECMUCPSRKL15_UB : 17|1@0+ (1,0) [0|1] "" IHU

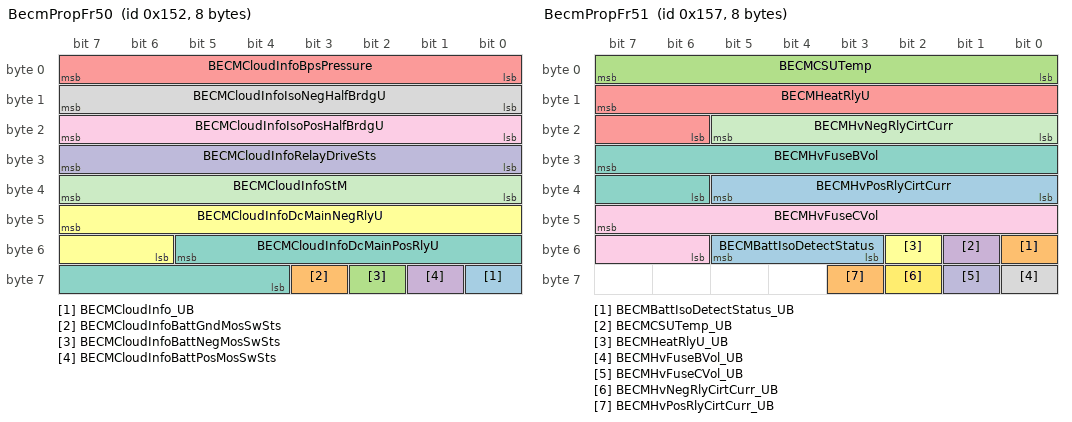
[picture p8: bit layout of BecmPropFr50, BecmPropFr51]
BO_ 338 BecmPropFr50 : 8 XCU
 SG_ BECMCloudInfo_UB : 56|1@0+ (1,0) [0|1] "" IHU
 SG_ BECMCloudInfoBattGndMosSwSts : 59|1@0+ (1,0) [0|1] "" IHU
 SG_ BECMCloudInfoBattNegMosSwSts : 58|1@0+ (1,0) [0|1] "" IHU
 SG_ BECMCloudInfoBattPosMosSwSts : 57|1@0+ (1,0) [0|1] "" IHU
 SG_ BECMCloudInfoBpsPressure : 7|8@0+ (1.0,0.0) [0.0|255.0] "Unitless" IHU
 SG_ BECMCloudInfoDcMainNegRlyU : 47|10@0+ (1.0,0.0) [0.0|1023.0] "Unitless" IHU
 SG_ BECMCloudInfoDcMainPosRlyU : 53|10@0+ (1.0,0.0) [0.0|1023.0] "Unitless" IHU
 SG_ BECMCloudInfoIsoNegHalfBrdgU : 15|8@0+ (1.0,0.0) [0.0|255.0] "Unitless" IHU
 SG_ BECMCloudInfoIsoPosHalfBrdgU : 23|8@0+ (1.0,0.0) [0.0|255.0] "Unitless" IHU
 SG_ BECMCloudInfoRelayDriveSts : 31|8@0+ (1.0,0.0) [0.0|255.0] "Unitless" IHU
 SG_ BECMCloudInfoStM : 39|8@0+ (1.0,0.0) [0.0|255.0] "Unitless" IHU

BO_ 343 BecmPropFr51 : 8 XCU
 SG_ BECMBattIsoDetectStatus : 53|3@0+ (1.0,0.0) [0.0|7.0] "Unitless" IHU
 SG_ BECMBattIsoDetectStatus_UB : 48|1@0+ (1,0) [0|1] "" IHU
 SG_ BECMCSUTemp : 7|8@0+ (1.0,0.0) [0.0|255.0] "Unitless" IHU
 SG_ BECMCSUTemp_UB : 49|1@0+ (1,0) [0|1] "" IHU
 SG_ BECMHeatRlyU : 15|10@0+ (1.0,0.0) [0.0|1023.0] "Unitless" IHU
 SG_ BECMHeatRlyU_UB : 50|1@0+ (1,0) [0|1] "" IHU
 SG_ BECMHvFuseBVol : 31|10@0+ (1.0,0.0) [0.0|1023.0] "Unitless" IHU
 SG_ BECMHvFuseBVol_UB : 56|1@0+ (1,0) [0|1] "" IHU
 SG_ BECMHvFuseCVol : 47|10@0+ (1.0,0.0) [0.0|1023.0] "Unitless" IHU
 SG_ BECMHvFuseCVol_UB : 57|1@0+ (1,0) [0|1] "" IHU
 SG_ BECMHvNegRlyCirtCurr : 21|6@0+ (1.0,0.0) [0.0|63.0] "Unitless" IHU
 SG_ BECMHvNegRlyCirtCurr_UB : 58|1@0+ (1,0) [0|1] "" IHU
 SG_ BECMHvPosRlyCirtCurr : 37|6@0+ (1.0,0.0) [0.0|63.0] "Unitless" IHU
 SG_ BECMHvPosRlyCirtCurr_UB : 59|1@0+ (1,0) [0|1] "" IHU

BO_ 348 BecmPropFr52 : 8 XCU
 SG_ BECMHvRelaySupplyU : 7|4@0+ (1.0,0.0) [0.0|15.0] "Unitless" IHU
 SG_ BECMHvRelaySupplyU_UB : 9|1@0+ (1,0) [0|1] "" IHU
 SG_ BECMLvHVIL1InputU : 15|6@0+ (1.0,0.0) [0.0|63.0] "Unitless" IHU
 SG_ BECMLvHVIL1InputU_UB : 8|1@0+ (1,0) [0|1] "" IHU
 SG_ BECMLvHVIL1OutputU : 31|6@0+ (1.0,0.0) [0.0|63.0] "Unitless" IHU
 SG_ BECMLvHVIL1OutputU_UB : 49|1@0+ (1,0) [0|1] "" IHU
 SG_ BECMLvHVIL2InputU : 25|6@0+ (1.0,0.0) [0.0|63.0] "Unitless" IHU
 SG_ BECMLvHVIL2InputU_UB : 48|1@0+ (1,0) [0|1] "" IHU
 SG_ BECMLvHVIL2OutputU : 35|6@0+ (1.0,0.0) [0.0|63.0] "Unitless" IHU
 SG_ BECMLvHVIL2OutputU_UB : 56|1@0+ (1,0) [0|1] "" IHU
 SG_ BECMLvHVIL3InputU : 45|6@0+ (1.0,0.0) [0.0|63.0] "Unitless" IHU
 SG_ BECMLvHVIL3InputU_UB : 57|1@0+ (1,0) [0|1] "" IHU
 SG_ BECMLvHVIL3OutputU : 55|6@0+ (1.0,0.0) [0.0|63.0] "Unitless" IHU
 SG_ BECMLvHVIL3OutputU_UB : 58|1@0+ (1,0) [0|1] "" IHU
 SG_ BECMMoflgErrHVConn : 3|1@0+ (1,0) [0|1] "" IHU
 SG_ BECMMoflgErrHVConn_UB : 59|1@0+ (1,0) [0|1] "" IHU
 SG_ BECMMoflgFrzHVConn : 2|1@0+ (1,0) [0|1] "" IHU
 SG_ BECMMoflgFrzHVConn_UB : 60|1@0+ (1,0) [0|1] "" IHU
 SG_ BECMMoflgFShOffOT : 1|1@0+ (1,0) [0|1] "" IHU
 SG_ BECMMoflgFShOffOT_UB : 61|1@0+ (1,0) [0|1] "" IHU
 SG_ BECMMoflgSShOffOT : 0|1@0+ (1,0) [0|1] "" IHU
 SG_ BECMMoflgSShOffOT_UB : 62|1@0+ (1,0) [0|1] "" IHU
 SG_ HvBattSOCE : 23|8@0+ (0.5,0.0) [0.0|100.0] "%" IHU
 SG_ HvBattSOCE_UB : 63|1@0+ (1,0) [0|1] "" IHU

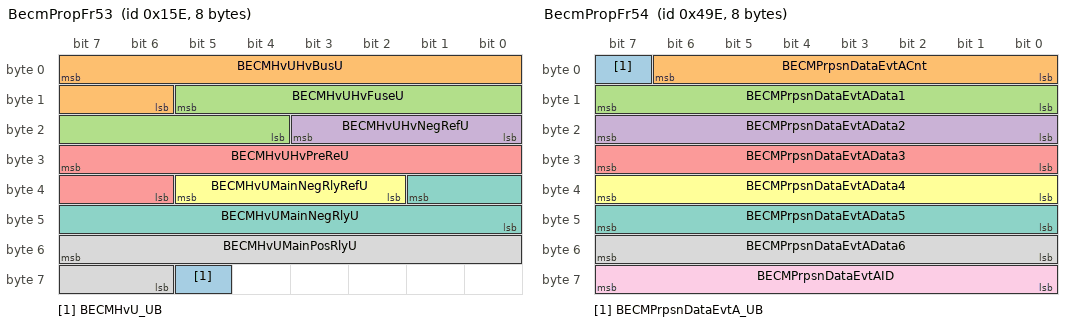
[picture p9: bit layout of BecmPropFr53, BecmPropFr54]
BO_ 350 BecmPropFr53 : 8 XCU
 SG_ BECMHvU_UB : 61|1@0+ (1,0) [0|1] "" IHU
 SG_ BECMHvUHvBusU : 7|10@0+ (1.0,0.0) [0.0|1023.0] "Unitless" IHU
 SG_ BECMHvUHvFuseU : 13|10@0+ (1.0,0.0) [0.0|1023.0] "Unitless" IHU
 SG_ BECMHvUHvNegRefU : 19|4@0+ (1.0,0.0) [0.0|15.0] "Unitless" IHU
 SG_ BECMHvUHvPreReU : 31|10@0+ (1.0,0.0) [0.0|1023.0] "Unitless" IHU
 SG_ BECMHvUMainNegRlyRefU : 37|4@0+ (1.0,0.0) [0.0|15.0] "Unitless" IHU
 SG_ BECMHvUMainNegRlyU : 33|10@0+ (1.0,0.0) [0.0|1023.0] "Unitless" IHU
 SG_ BECMHvUMainPosRlyU : 55|10@0+ (1.0,0.0) [0.0|1023.0] "Unitless" IHU

BO_ 1182 BecmPropFr54 : 8 XCU
 SG_ BECMPrpsnDataEvtA_UB : 7|1@0+ (1,0) [0|1] "" IHU
 SG_ BECMPrpsnDataEvtACnt : 6|7@0+ (1.0,0.0) [0.0|127.0] "Unitless" IHU
 SG_ BECMPrpsnDataEvtAData1 : 15|8@0+ (1.0,0.0) [0.0|255.0] "Unitless" IHU
 SG_ BECMPrpsnDataEvtAData2 : 23|8@0+ (1.0,0.0) [0.0|255.0] "Unitless" IHU
 SG_ BECMPrpsnDataEvtAData3 : 31|8@0+ (1.0,0.0) [0.0|255.0] "Unitless" IHU
 SG_ BECMPrpsnDataEvtAData4 : 39|8@0+ (1.0,0.0) [0.0|255.0] "Unitless" IHU
 SG_ BECMPrpsnDataEvtAData5 : 47|8@0+ (1.0,0.0) [0.0|255.0] "Unitless" IHU
 SG_ BECMPrpsnDataEvtAData6 : 55|8@0+ (1.0,0.0) [0.0|255.0] "Unitless" IHU
 SG_ BECMPrpsnDataEvtAID : 63|8@0+ (1.0,0.0) [0.0|255.0] "Unitless" IHU

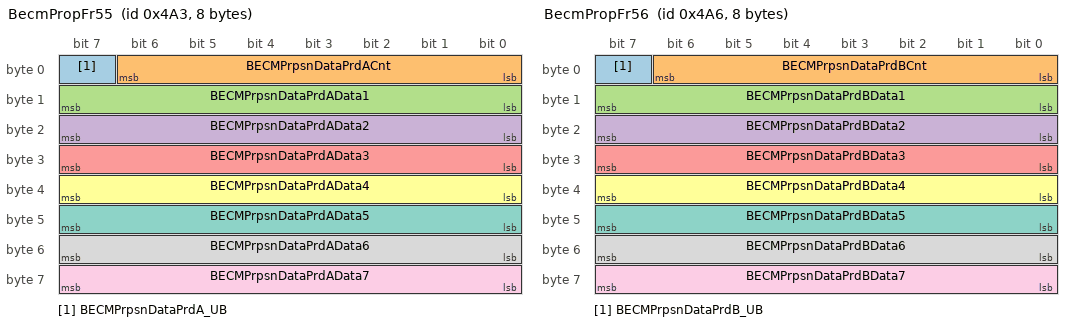
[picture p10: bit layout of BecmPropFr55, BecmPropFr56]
BO_ 1187 BecmPropFr55 : 8 XCU
 SG_ BECMPrpsnDataPrdA_UB : 7|1@0+ (1,0) [0|1] "" IHU
 SG_ BECMPrpsnDataPrdACnt : 6|7@0+ (1.0,0.0) [0.0|127.0] "Unitless" IHU
 SG_ BECMPrpsnDataPrdAData1 : 15|8@0+ (1.0,0.0) [0.0|255.0] "Unitless" IHU
 SG_ BECMPrpsnDataPrdAData2 : 23|8@0+ (1.0,0.0) [0.0|255.0] "Unitless" IHU
 SG_ BECMPrpsnDataPrdAData3 : 31|8@0+ (1.0,0.0) [0.0|255.0] "Unitless" IHU
 SG_ BECMPrpsnDataPrdAData4 : 39|8@0+ (1.0,0.0) [0.0|255.0] "Unitless" IHU
 SG_ BECMPrpsnDataPrdAData5 : 47|8@0+ (1.0,0.0) [0.0|255.0] "Unitless" IHU
 SG_ BECMPrpsnDataPrdAData6 : 55|8@0+ (1.0,0.0) [0.0|255.0] "Unitless" IHU
 SG_ BECMPrpsnDataPrdAData7 : 63|8@0+ (1.0,0.0) [0.0|255.0] "Unitless" IHU

BO_ 1190 BecmPropFr56 : 8 XCU
 SG_ BECMPrpsnDataPrdB_UB : 7|1@0+ (1,0) [0|1] "" IHU
 SG_ BECMPrpsnDataPrdBCnt : 6|7@0+ (1.0,0.0) [0.0|127.0] "Unitless" IHU
 SG_ BECMPrpsnDataPrdBData1 : 15|8@0+ (1.0,0.0) [0.0|255.0] "Unitless" IHU
 SG_ BECMPrpsnDataPrdBData2 : 23|8@0+ (1.0,0.0) [0.0|255.0] "Unitless" IHU
 SG_ BECMPrpsnDataPrdBData3 : 31|8@0+ (1.0,0.0) [0.0|255.0] "Unitless" IHU
 SG_ BECMPrpsnDataPrdBData4 : 39|8@0+ (1.0,0.0) [0.0|255.0] "Unitless" IHU
 SG_ BECMPrpsnDataPrdBData5 : 47|8@0+ (1.0,0.0) [0.0|255.0] "Unitless" IHU
 SG_ BECMPrpsnDataPrdBData6 : 55|8@0+ (1.0,0.0) [0.0|255.0] "Unitless" IHU
 SG_ BECMPrpsnDataPrdBData7 : 63|8@0+ (1.0,0.0) [0.0|255.0] "Unitless" IHU

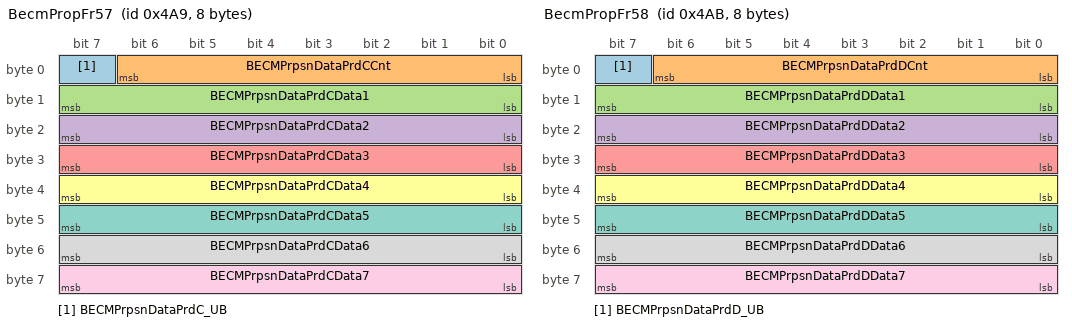
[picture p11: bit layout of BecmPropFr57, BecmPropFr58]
BO_ 1193 BecmPropFr57 : 8 XCU
 SG_ BECMPrpsnDataPrdC_UB : 7|1@0+ (1,0) [0|1] "" IHU
 SG_ BECMPrpsnDataPrdCCnt : 6|7@0+ (1.0,0.0) [0.0|127.0] "Unitless" IHU
 SG_ BECMPrpsnDataPrdCData1 : 15|8@0+ (1.0,0.0) [0.0|255.0] "Unitless" IHU
 SG_ BECMPrpsnDataPrdCData2 : 23|8@0+ (1.0,0.0) [0.0|255.0] "Unitless" IHU
 SG_ BECMPrpsnDataPrdCData3 : 31|8@0+ (1.0,0.0) [0.0|255.0] "Unitless" IHU
 SG_ BECMPrpsnDataPrdCData4 : 39|8@0+ (1.0,0.0) [0.0|255.0] "Unitless" IHU
 SG_ BECMPrpsnDataPrdCData5 : 47|8@0+ (1.0,0.0) [0.0|255.0] "Unitless" IHU
 SG_ BECMPrpsnDataPrdCData6 : 55|8@0+ (1.0,0.0) [0.0|255.0] "Unitless" IHU
 SG_ BECMPrpsnDataPrdCData7 : 63|8@0+ (1.0,0.0) [0.0|255.0] "Unitless" IHU

BO_ 1195 BecmPropFr58 : 8 XCU
 SG_ BECMPrpsnDataPrdD_UB : 7|1@0+ (1,0) [0|1] "" IHU
 SG_ BECMPrpsnDataPrdDCnt : 6|7@0+ (1.0,0.0) [0.0|127.0] "Unitless" IHU
 SG_ BECMPrpsnDataPrdDData1 : 15|8@0+ (1.0,0.0) [0.0|255.0] "Unitless" IHU
 SG_ BECMPrpsnDataPrdDData2 : 23|8@0+ (1.0,0.0) [0.0|255.0] "Unitless" IHU
 SG_ BECMPrpsnDataPrdDData3 : 31|8@0+ (1.0,0.0) [0.0|255.0] "Unitless" IHU
 SG_ BECMPrpsnDataPrdDData4 : 39|8@0+ (1.0,0.0) [0.0|255.0] "Unitless" IHU
 SG_ BECMPrpsnDataPrdDData5 : 47|8@0+ (1.0,0.0) [0.0|255.0] "Unitless" IHU
 SG_ BECMPrpsnDataPrdDData6 : 55|8@0+ (1.0,0.0) [0.0|255.0] "Unitless" IHU
 SG_ BECMPrpsnDataPrdDData7 : 63|8@0+ (1.0,0.0) [0.0|255.0] "Unitless" IHU

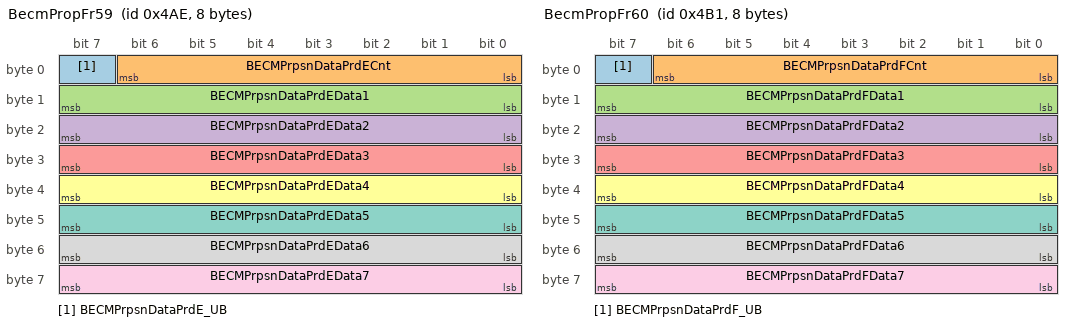
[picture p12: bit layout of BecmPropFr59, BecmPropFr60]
BO_ 1198 BecmPropFr59 : 8 XCU
 SG_ BECMPrpsnDataPrdE_UB : 7|1@0+ (1,0) [0|1] "" IHU
 SG_ BECMPrpsnDataPrdECnt : 6|7@0+ (1.0,0.0) [0.0|127.0] "Unitless" IHU
 SG_ BECMPrpsnDataPrdEData1 : 15|8@0+ (1.0,0.0) [0.0|255.0] "Unitless" IHU
 SG_ BECMPrpsnDataPrdEData2 : 23|8@0+ (1.0,0.0) [0.0|255.0] "Unitless" IHU
 SG_ BECMPrpsnDataPrdEData3 : 31|8@0+ (1.0,0.0) [0.0|255.0] "Unitless" IHU
 SG_ BECMPrpsnDataPrdEData4 : 39|8@0+ (1.0,0.0) [0.0|255.0] "Unitless" IHU
 SG_ BECMPrpsnDataPrdEData5 : 47|8@0+ (1.0,0.0) [0.0|255.0] "Unitless" IHU
 SG_ BECMPrpsnDataPrdEData6 : 55|8@0+ (1.0,0.0) [0.0|255.0] "Unitless" IHU
 SG_ BECMPrpsnDataPrdEData7 : 63|8@0+ (1.0,0.0) [0.0|255.0] "Unitless" IHU

BO_ 1201 BecmPropFr60 : 8 XCU
 SG_ BECMPrpsnDataPrdF_UB : 7|1@0+ (1,0) [0|1] "" IHU
 SG_ BECMPrpsnDataPrdFCnt : 6|7@0+ (1.0,0.0) [0.0|127.0] "Unitless" IHU
 SG_ BECMPrpsnDataPrdFData1 : 15|8@0+ (1.0,0.0) [0.0|255.0] "Unitless" IHU
 SG_ BECMPrpsnDataPrdFData2 : 23|8@0+ (1.0,0.0) [0.0|255.0] "Unitless" IHU
 SG_ BECMPrpsnDataPrdFData3 : 31|8@0+ (1.0,0.0) [0.0|255.0] "Unitless" IHU
 SG_ BECMPrpsnDataPrdFData4 : 39|8@0+ (1.0,0.0) [0.0|255.0] "Unitless" IHU
 SG_ BECMPrpsnDataPrdFData5 : 47|8@0+ (1.0,0.0) [0.0|255.0] "Unitless" IHU
 SG_ BECMPrpsnDataPrdFData6 : 55|8@0+ (1.0,0.0) [0.0|255.0] "Unitless" IHU
 SG_ BECMPrpsnDataPrdFData7 : 63|8@0+ (1.0,0.0) [0.0|255.0] "Unitless" IHU

BO_ 1203 BecmPropFr61 : 8 XCU
 SG_ BECMPrpsnDataPrdG_UB : 7|1@0+ (1,0) [0|1] "" IHU
 SG_ BECMPrpsnDataPrdGCnt : 6|7@0+ (1.0,0.0) [0.0|127.0] "Unitless" IHU
 SG_ BECMPrpsnDataPrdGData1 : 15|8@0+ (1.0,0.0) [0.0|255.0] "Unitless" IHU
 SG_ BECMPrpsnDataPrdGData2 : 23|8@0+ (1.0,0.0) [0.0|255.0] "Unitless" IHU
 SG_ BECMPrpsnDataPrdGData3 : 31|8@0+ (1.0,0.0) [0.0|255.0] "Unitless" IHU
 SG_ BECMPrpsnDataPrdGData4 : 39|8@0+ (1.0,0.0) [0.0|255.0] "Unitless" IHU
 SG_ BECMPrpsnDataPrdGData5 : 47|8@0+ (1.0,0.0) [0.0|255.0] "Unitless" IHU
 SG_ BECMPrpsnDataPrdGData6 : 55|8@0+ (1.0,0.0) [0.0|255.0] "Unitless" IHU
 SG_ BECMPrpsnDataPrdGData7 : 63|8@0+ (1.0,0.0) [0.0|255.0] "Unitless" IHU

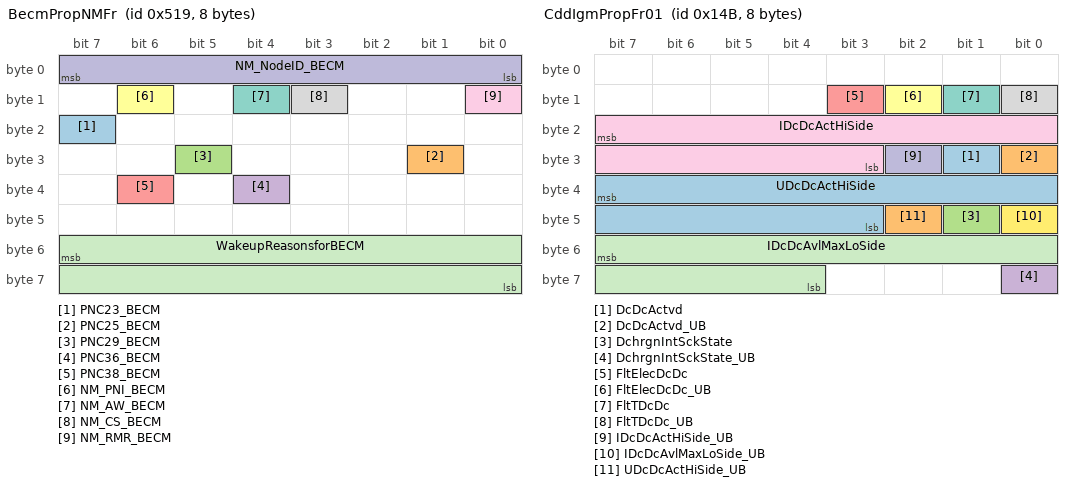
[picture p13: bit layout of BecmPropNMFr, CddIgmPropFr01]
BO_ 1305 BecmPropNMFr : 8 BECM
 SG_ PNC23_BECM : 23|1@0+ (1,0) [0|0] "" Vector__XXX
 SG_ PNC25_BECM : 25|1@0+ (1,0) [0|0] "" Vector__XXX
 SG_ PNC29_BECM : 29|1@0+ (1,0) [0|0] "" Vector__XXX
 SG_ PNC36_BECM : 36|1@0+ (1,0) [0|0] "" Vector__XXX
 SG_ PNC38_BECM : 38|1@0+ (1,0) [0|0] "" Vector__XXX
 SG_ NM_PNI_BECM : 14|1@0+ (1,0) [0|0] "" Vector__XXX
 SG_ NM_AW_BECM : 12|1@0+ (1,0) [0|0] "" Vector__XXX
 SG_ NM_CS_BECM : 11|1@0+ (1,0) [0|0] "" Vector__XXX
 SG_ NM_RMR_BECM : 8|1@0+ (1,0) [0|0] "" Vector__XXX
 SG_ NM_NodeID_BECM : 7|8@0+ (1,0) [0|0] "" Vector__XXX

 SG_ WakeupReasonsforBECM : 55|16@0+ (1,0) [0|65535] "" Vector__XXX

BO_ 1369 BecmPropVFCVectorFr : 8 BECM
 SG_ VFCVectorBECMBlockID : 1|2@0+ (1.0,0.0) [0.0|3.0] "Unitless" IHU
 SG_ VFCVectorBECMVFCid0 : 2|1@0+ (1,0) [0|1] "" IHU
 SG_ VFCVectorBECMVFCid1 : 3|1@0+ (1,0) [0|1] "" IHU
 SG_ VFCVectorBECMVFCid10 : 12|1@0+ (1,0) [0|1] "" IHU
 SG_ VFCVectorBECMVFCid11 : 13|1@0+ (1,0) [0|1] "" IHU
 SG_ VFCVectorBECMVFCid12 : 14|1@0+ (1,0) [0|1] "" IHU
 SG_ VFCVectorBECMVFCid13 : 15|1@0+ (1,0) [0|1] "" IHU
 SG_ VFCVectorBECMVFCid14 : 16|1@0+ (1,0) [0|1] "" IHU
 SG_ VFCVectorBECMVFCid15 : 17|1@0+ (1,0) [0|1] "" IHU
 SG_ VFCVectorBECMVFCid16 : 18|1@0+ (1,0) [0|1] "" IHU
 SG_ VFCVectorBECMVFCid17 : 19|1@0+ (1,0) [0|1] "" IHU
 SG_ VFCVectorBECMVFCid18 : 20|1@0+ (1,0) [0|1] "" IHU
 SG_ VFCVectorBECMVFCid19 : 21|1@0+ (1,0) [0|1] "" IHU
 SG_ VFCVectorBECMVFCid2 : 4|1@0+ (1,0) [0|1] "" IHU
 SG_ VFCVectorBECMVFCid20 : 22|1@0+ (1,0) [0|1] "" IHU
 SG_ VFCVectorBECMVFCid21 : 23|1@0+ (1,0) [0|1] "" IHU
 SG_ VFCVectorBECMVFCid22 : 24|1@0+ (1,0) [0|1] "" IHU
 SG_ VFCVectorBECMVFCid23 : 25|1@0+ (1,0) [0|1] "" IHU
 SG_ VFCVectorBECMVFCid24 : 26|1@0+ (1,0) [0|1] "" IHU
 SG_ VFCVectorBECMVFCid25 : 27|1@0+ (1,0) [0|1] "" IHU
 SG_ VFCVectorBECMVFCid26 : 28|1@0+ (1,0) [0|1] "" IHU
 SG_ VFCVectorBECMVFCid27 : 29|1@0+ (1,0) [0|1] "" IHU
 SG_ VFCVectorBECMVFCid28 : 30|1@0+ (1,0) [0|1] "" IHU
 SG_ VFCVectorBECMVFCid29 : 31|1@0+ (1,0) [0|1] "" IHU
 SG_ VFCVectorBECMVFCid3 : 5|1@0+ (1,0) [0|1] "" IHU
 SG_ VFCVectorBECMVFCid30 : 32|1@0+ (1,0) [0|1] "" IHU
 SG_ VFCVectorBECMVFCid31 : 33|1@0+ (1,0) [0|1] "" IHU
 SG_ VFCVectorBECMVFCid32 : 34|1@0+ (1,0) [0|1] "" IHU
 SG_ VFCVectorBECMVFCid33 : 35|1@0+ (1,0) [0|1] "" IHU
 SG_ VFCVectorBECMVFCid34 : 36|1@0+ (1,0) [0|1] "" IHU
 SG_ VFCVectorBECMVFCid35 : 37|1@0+ (1,0) [0|1] "" IHU
 SG_ VFCVectorBECMVFCid36 : 38|1@0+ (1,0) [0|1] "" IHU
 SG_ VFCVectorBECMVFCid37 : 39|1@0+ (1,0) [0|1] "" IHU
 SG_ VFCVectorBECMVFCid38 : 40|1@0+ (1,0) [0|1] "" IHU
 SG_ VFCVectorBECMVFCid39 : 41|1@0+ (1,0) [0|1] "" IHU
 SG_ VFCVectorBECMVFCid4 : 6|1@0+ (1,0) [0|1] "" IHU
 SG_ VFCVectorBECMVFCid40 : 42|1@0+ (1,0) [0|1] "" IHU
 SG_ VFCVectorBECMVFCid41 : 43|1@0+ (1,0) [0|1] "" IHU
 SG_ VFCVectorBECMVFCid42 : 44|1@0+ (1,0) [0|1] "" IHU
 SG_ VFCVectorBECMVFCid43 : 45|1@0+ (1,0) [0|1] "" IHU
 SG_ VFCVectorBECMVFCid44 : 46|1@0+ (1,0) [0|1] "" IHU
 SG_ VFCVectorBECMVFCid45 : 47|1@0+ (1,0) [0|1] "" IHU
 SG_ VFCVectorBECMVFCid46 : 48|1@0+ (1,0) [0|1] "" IHU
 SG_ VFCVectorBECMVFCid47 : 49|1@0+ (1,0) [0|1] "" IHU
 SG_ VFCVectorBECMVFCid48 : 50|1@0+ (1,0) [0|1] "" IHU
 SG_ VFCVectorBECMVFCid49 : 51|1@0+ (1,0) [0|1] "" IHU
 SG_ VFCVectorBECMVFCid5 : 7|1@0+ (1,0) [0|1] "" IHU
 SG_ VFCVectorBECMVFCid50 : 52|1@0+ (1,0) [0|1] "" IHU
 SG_ VFCVectorBECMVFCid51 : 53|1@0+ (1,0) [0|1] "" IHU
 SG_ VFCVectorBECMVFCid52 : 54|1@0+ (1,0) [0|1] "" IHU
 SG_ VFCVectorBECMVFCid53 : 55|1@0+ (1,0) [0|1] "" IHU
 SG_ VFCVectorBECMVFCid54 : 56|1@0+ (1,0) [0|1] "" IHU
 SG_ VFCVectorBECMVFCid55 : 57|1@0+ (1,0) [0|1] "" IHU
 SG_ VFCVectorBECMVFCid56 : 58|1@0+ (1,0) [0|1] "" IHU
 SG_ VFCVectorBECMVFCid57 : 59|1@0+ (1,0) [0|1] "" IHU
 SG_ VFCVectorBECMVFCid58 : 60|1@0+ (1,0) [0|1] "" IHU
 SG_ VFCVectorBECMVFCid59 : 61|1@0+ (1,0) [0|1] "" IHU
 SG_ VFCVectorBECMVFCid6 : 8|1@0+ (1,0) [0|1] "" IHU
 SG_ VFCVectorBECMVFCid60 : 62|1@0+ (1,0) [0|1] "" IHU
 SG_ VFCVectorBECMVFCid61 : 63|1@0+ (1,0) [0|1] "" IHU
 SG_ VFCVectorBECMVFCid7 : 9|1@0+ (1,0) [0|1] "" IHU
 SG_ VFCVectorBECMVFCid8 : 10|1@0+ (1,0) [0|1] "" IHU
 SG_ VFCVectorBECMVFCid9 : 11|1@0+ (1,0) [0|1] "" IHU

BO_ 2026 BecmToDhuJ1979OBDPropDiagResFrame11 : 8 BECM

BO_ 1589 BecmToVddmPropDiagResFrame : 8 BECM

BO_ 331 CddIgmPropFr01 : 8 CDD
 SG_ DcDcActvd : 25|1@0+ (1,0) [0|1] "" IHU,XCU,ZCUD
 SG_ DcDcActvd_UB : 24|1@0+ (1,0) [0|1] "" IHU,XCU,ZCUD
 SG_ DchrgnIntSckState : 41|1@0+ (1,0) [0|1] "" IHU
 SG_ DchrgnIntSckState_UB : 56|1@0+ (1,0) [0|1] "" IHU
 SG_ FltElecDcDc : 11|1@0+ (1,0) [0|1] "" IHU,ZCUD
 SG_ FltElecDcDc_UB : 10|1@0+ (1,0) [0|1] "" IHU,ZCUD
 SG_ FltTDcDc : 9|1@0+ (1,0) [0|1] "" IHU,ZCUD
 SG_ FltTDcDc_UB : 8|1@0+ (1,0) [0|1] "" IHU,ZCUD
 SG_ IDcDcActHiSide : 23|13@0+ (0.1,-410.0) [-410.0|409.1] "A" IHU,XCU
 SG_ IDcDcActHiSide_UB : 26|1@0+ (1,0) [0|1] "" IHU,XCU
 SG_ IDcDcAvlMaxLoSide : 55|12@0+ (0.1,0.0) [0.0|409.5] "A" IHU,ZCUD
 SG_ IDcDcAvlMaxLoSide_UB : 40|1@0+ (1,0) [0|1] "" IHU,ZCUD
 SG_ UDcDcActHiSide : 39|13@0+ (0.125,0.0) [0.0|1023.0] "Volt" IHU,XCU
 SG_ UDcDcActHiSide_UB : 42|1@0+ (1,0) [0|1] "" IHU,XCU

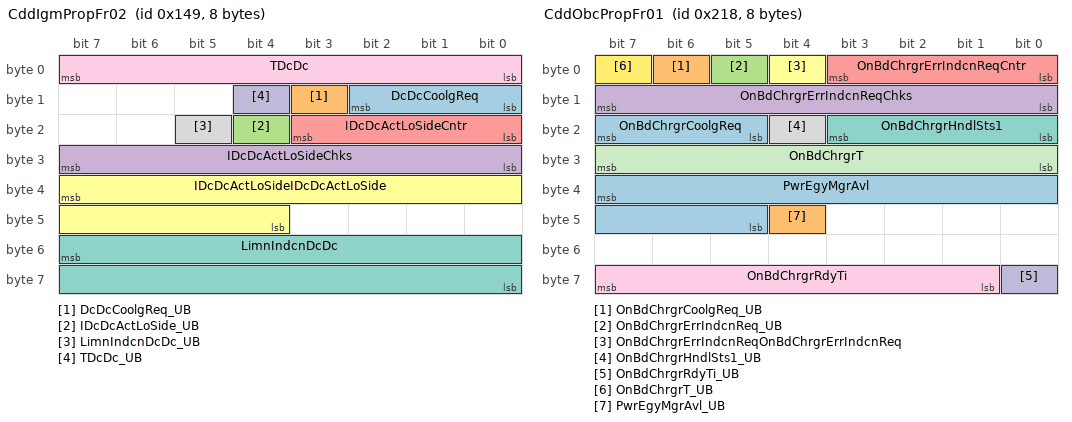
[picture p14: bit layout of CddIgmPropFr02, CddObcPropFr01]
BO_ 329 CddIgmPropFr02 : 8 CDD
 SG_ DcDcCoolgReq : 10|3@0+ (1,0) [0|7] "" IHU,XCU
 SG_ DcDcCoolgReq_UB : 11|1@0+ (1,0) [0|1] "" IHU,XCU
 SG_ IDcDcActLoSide_UB : 20|1@0+ (1,0) [0|1] "" IHU,ZCUD
 SG_ IDcDcActLoSideChks : 31|8@0+ (1.0,0.0) [0.0|255.0] "Unitless" IHU,ZCUD
 SG_ IDcDcActLoSideCntr : 19|4@0+ (1.0,0.0) [0.0|15.0] "Unitless" IHU,ZCUD
 SG_ IDcDcActLoSideIDcDcActLoSide : 39|12@0+ (0.1,0.0) [0.0|409.5] "A" IHU,ZCUD
 SG_ LimnIndcnDcDc : 55|16@0+ (1.0,0.0) [0.0|65535.0] "Unitless" IHU,XCU
 SG_ LimnIndcnDcDc_UB : 21|1@0+ (1,0) [0|1] "" IHU,XCU
 SG_ TDcDc : 7|8@0+ (1.0,-40.0) [-40.0|215.0] "degC" IHU,XCU
 SG_ TDcDc_UB : 12|1@0+ (1,0) [0|1] "" IHU,XCU

BO_ 1109 CddIgmPropFr05 : 8 CDD
 SG_ DcDcMinCooltFlow : 7|7@0+ (0.1,0.0) [0.0|12.700000000000001] "L / min" XCU
 SG_ DcDcMinCooltFlow_UB : 0|1@0+ (1,0) [0|1] "" XCU
 SG_ TDcDcCoolt : 31|8@0+ (1.0,-40.0) [-40.0|215.0] "degC" IHU,XCU,ZCUD
 SG_ TDcDcCoolt_UB : 16|1@0+ (1,0) [0|1] "" IHU,XCU,ZCUD

BO_ 536 CddObcPropFr01 : 8 CDD
 SG_ OnBdChrgrCoolgReq : 23|3@0+ (1,0) [0|7] "" XCU
 SG_ OnBdChrgrCoolgReq_UB : 6|1@0+ (1,0) [0|1] "" XCU
 SG_ OnBdChrgrErrIndcnReq_UB : 5|1@0+ (1,0) [0|1] "" IHU,XCU
 SG_ OnBdChrgrErrIndcnReqChks : 15|8@0+ (1.0,0.0) [0.0|255.0] "Unitless" IHU,XCU
 SG_ OnBdChrgrErrIndcnReqCntr : 3|4@0+ (1.0,0.0) [0.0|15.0] "Unitless" IHU,XCU
 SG_ OnBdChrgrErrIndcnReqOnBdChrgrErrIndcnReq : 4|1@0+ (1,0) [0|1] "" IHU,XCU
 SG_ OnBdChrgrHndlSts1 : 19|4@0+ (1,0) [0|15] "" IHU,XCU,ZCUD
 SG_ OnBdChrgrHndlSts1_UB : 20|1@0+ (1,0) [0|1] "" IHU,XCU,ZCUD
 SG_ OnBdChrgrRdyTi : 63|7@0+ (100.0,0.0) [0.0|12700.0] "Milliseconds" IHU
 SG_ OnBdChrgrRdyTi_UB : 56|1@0+ (1,0) [0|1] "" IHU
 SG_ OnBdChrgrT : 31|8@0+ (1.0,-40.0) [-40.0|215.0] "degC" IHU,XCU
 SG_ OnBdChrgrT_UB : 7|1@0+ (1,0) [0|1] "" IHU,XCU
 SG_ PwrEgyMgrAvl : 39|11@0+ (20.0,0.0) [0.0|40940.0] "W" IHU,XCU
 SG_ PwrEgyMgrAvl_UB : 44|1@0+ (1,0) [0|1] "" IHU,XCU

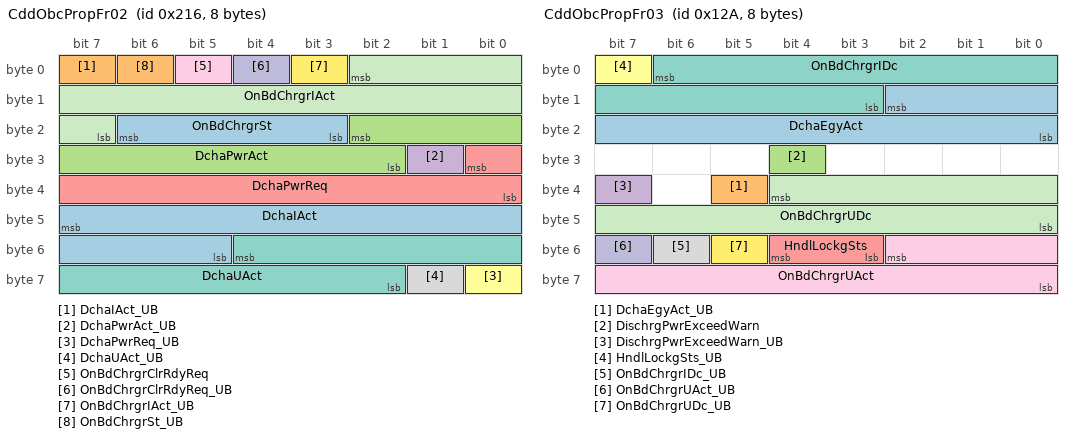
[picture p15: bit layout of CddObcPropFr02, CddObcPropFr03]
BO_ 534 CddObcPropFr02 : 8 CDD
 SG_ DchaIAct : 47|11@0+ (0.1,0.0) [0.0|204.70000000000002] "A" IHU
 SG_ DchaIAct_UB : 7|1@0+ (1,0) [0|1] "" IHU
 SG_ DchaPwrAct : 18|9@0+ (100.0,0.0) [0.0|51100.0] "W" IHU,XCU
 SG_ DchaPwrAct_UB : 25|1@0+ (1,0) [0|1] "" IHU,XCU
 SG_ DchaPwrReq : 24|9@0+ (100.0,0.0) [0.0|51100.0] "W" XCU
 SG_ DchaPwrReq_UB : 56|1@0+ (1,0) [0|1] "" XCU
 SG_ DchaUAct : 52|11@0+ (0.25,0.0) [0.0|511.0] "Volt" IHU
 SG_ DchaUAct_UB : 57|1@0+ (1,0) [0|1] "" IHU
 SG_ OnBdChrgrClrRdyReq : 5|1@0+ (1,0) [0|1] "" XCU
 SG_ OnBdChrgrClrRdyReq_UB : 4|1@0+ (1,0) [0|1] "" XCU
 SG_ OnBdChrgrIAct : 2|12@0+ (0.1,-200.0) [-200.0|200.0] "A" IHU
 SG_ OnBdChrgrIAct_UB : 3|1@0+ (1,0) [0|1] "" IHU
 SG_ OnBdChrgrSt : 22|4@0+ (1,0) [0|15] "" IHU,XCU,ZCUD
 SG_ OnBdChrgrSt_UB : 6|1@0+ (1,0) [0|1] "" IHU,XCU,ZCUD

BO_ 298 CddObcPropFr03 : 8 CDD
 SG_ DchaEgyAct : 10|11@0+ (0.1,0.0) [0.0|204.70000000000002] "KwH_1" IHU
 SG_ DchaEgyAct_UB : 37|1@0+ (1,0) [0|1] "" IHU
 SG_ DischrgPwrExceedWarn : 28|1@0+ (1,0) [0|1] "" IHU
 SG_ DischrgPwrExceedWarn_UB : 39|1@0+ (1,0) [0|1] "" IHU
 SG_ HndlLockgSts : 52|2@0+ (1,0) [0|3] "" IHU,XCU
 SG_ HndlLockgSts_UB : 7|1@0+ (1,0) [0|1] "" IHU,XCU
 SG_ OnBdChrgrIDc : 6|12@0+ (0.1,-200.0) [-200.0|200.0] "A" IHU,XCU
 SG_ OnBdChrgrIDc_UB : 54|1@0+ (1,0) [0|1] "" IHU,XCU
 SG_ OnBdChrgrUAct : 50|11@0+ (0.25,0.0) [0.0|511.0] "Volt" IHU
 SG_ OnBdChrgrUAct_UB : 55|1@0+ (1,0) [0|1] "" IHU
 SG_ OnBdChrgrUDc : 36|13@0+ (0.2,0.0) [0.0|1200.0] "Volt" IHU,XCU
 SG_ OnBdChrgrUDc_UB : 53|1@0+ (1,0) [0|1] "" IHU,XCU

BO_ 1041 CddObcPropFr04 : 8 CDD
 SG_ ACChaPwrAct : 24|9@0+ (100.0,0.0) [0.0|51100.0] "W" IHU
 SG_ ACChaPwrAct_UB : 25|1@0+ (1,0) [0|1] "" IHU
 SG_ OnBdChrgrCooltT : 7|8@0+ (1.0,-40.0) [-40.0|215.0] "degC" IHU,XCU,ZCUD
 SG_ OnBdChrgrCooltT_UB : 27|1@0+ (1,0) [0|1] "" IHU,XCU,ZCUD
 SG_ OnBdChrgrMinCooltFlow : 15|7@0+ (0.1,0.0) [0.0|12.700000000000001] "L / min" XCU
 SG_ OnBdChrgrMinCooltFlow_UB : 8|1@0+ (1,0) [0|1] "" XCU

BO_ 785 CddObcPropFr05 : 8 CDD
 SG_ DchaEgyStrg_UB : 44|1@0+ (1,0) [0|1] "" IHU
 SG_ DchaEgyStrgDchaCarTiGlb : 7|32@0+ (0.1,0.0) [0.0|429496729.5] "s" IHU
 SG_ DchaEgyStrgDchaEgy : 39|11@0+ (0.1,0.0) [0.0|204.70000000000002] "KwH_1" IHU
 SG_ MaxACInpISetFdb : 54|7@0+ (1.0,0.0) [0.0|127.0] "Unitless" IHU
 SG_ MaxACInpISetFdb_UB : 55|1@0+ (1,0) [0|1] "" IHU
 SG_ V2XDchaSwtFdb : 43|3@0+ (1.0,0.0) [0.0|7.0] "Unitless" IHU,XCU
 SG_ V2XDchaSwtFdb_UB : 40|1@0+ (1,0) [0|1] "" IHU,XCU

BO_ 410 CddObcPropFr06 : 8 CDD
 SG_ OnBdChrgrFcnResvSigGrp : 7|31@0+ (1.0,0.0) [0.0|9223372036854776000.0] "Unitless" XCU
 SG_ OnBdChrgrFcnResvSigGrp_UB : 56|1@0+ (1,0) [0|1] "" XCU
 SG_ OnBdChrgrFcnResvSigGrp1 : 39|31@0+ (1.0,0.0) [0.0|9223372036854776000.0] "Unitless" XCU
 SG_ OnBdChrgrFcnResvSigGrp1_UB : 24|1@0+ (1,0) [0|1] "" XCU

BO_ 1184 CddObcPropFr07 : 8 CDD
 SG_ LimnIndcnOBC : 7|16@0+ (1.0,0.0) [0.0|65535.0] "Unitless" IHU,XCU
 SG_ LimnIndcnOBC_UB : 23|1@0+ (1,0) [0|1] "" IHU,XCU

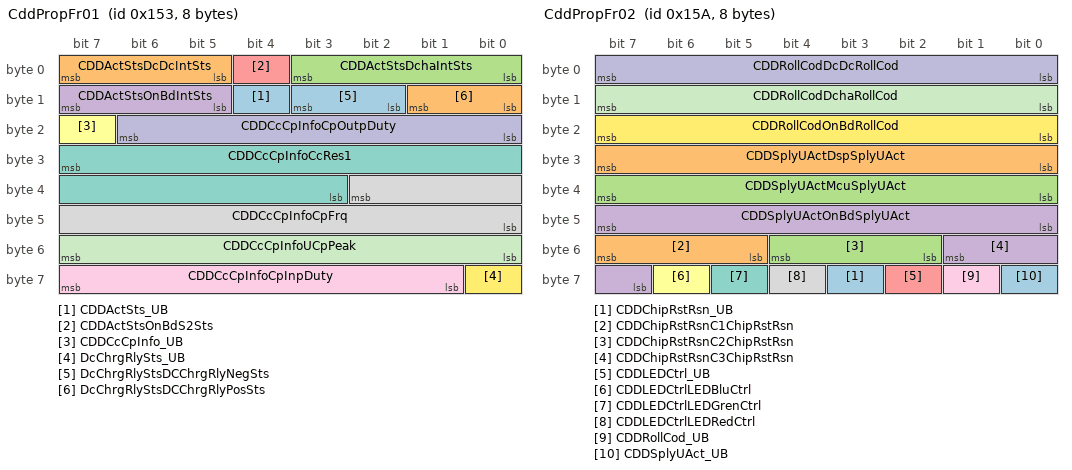
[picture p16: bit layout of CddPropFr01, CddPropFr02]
BO_ 339 CddPropFr01 : 8 CDD
 SG_ CDDActSts_UB : 12|1@0+ (1,0) [0|1] "" IHU
 SG_ CDDActStsDcDcIntSts : 7|3@0+ (1,0) [0|7] "" IHU
 SG_ CDDActStsDchaIntSts : 3|4@0+ (1,0) [0|15] "" IHU
 SG_ CDDActStsOnBdIntSts : 15|3@0+ (1,0) [0|7] "" IHU
 SG_ CDDActStsOnBdS2Sts : 4|1@0+ (1,0) [0|1] "" IHU
 SG_ CDDCcCpInfo_UB : 23|1@0+ (1,0) [0|1] "" IHU
 SG_ CDDCcCpInfoCcRes1 : 31|13@0+ (1.0,0.0) [0.0|8191.0] "Ohm" IHU
 SG_ CDDCcCpInfoCpFrq : 34|11@0+ (1.0,0.0) [0.0|2047.0] "Hz" IHU
 SG_ CDDCcCpInfoCpInpDuty : 63|7@0+ (1.0,0.0) [0.0|100.0] "%" IHU
 SG_ CDDCcCpInfoCpOutpDuty : 22|7@0+ (1.0,0.0) [0.0|100.0] "%" IHU
 SG_ CDDCcCpInfoUCpPeak : 55|8@0+ (0.1,0.0) [0.0|25.5] "Volt" IHU
 SG_ DcChrgRlySts_UB : 56|1@0+ (1,0) [0|1] "" IHU
 SG_ DcChrgRlyStsDCChrgRlyNegSts : 11|2@0+ (1,0) [0|3] "" IHU
 SG_ DcChrgRlyStsDCChrgRlyPosSts : 9|2@0+ (1,0) [0|3] "" IHU

BO_ 346 CddPropFr02 : 8 CDD
 SG_ CDDChipRstRsn_UB : 59|1@0+ (1,0) [0|1] "" IHU
 SG_ CDDChipRstRsnC1ChipRstRsn : 55|3@0+ (1,0) [0|7] "" IHU
 SG_ CDDChipRstRsnC2ChipRstRsn : 52|3@0+ (1,0) [0|7] "" IHU
 SG_ CDDChipRstRsnC3ChipRstRsn : 49|3@0+ (1,0) [0|7] "" IHU
 SG_ CDDLEDCtrl_UB : 58|1@0+ (1,0) [0|1] "" IHU
 SG_ CDDLEDCtrlLEDBluCtrl : 62|1@0+ (1,0) [0|1] "" IHU
 SG_ CDDLEDCtrlLEDGrenCtrl : 61|1@0+ (1,0) [0|1] "" IHU
 SG_ CDDLEDCtrlLEDRedCtrl : 60|1@0+ (1,0) [0|1] "" IHU
 SG_ CDDRollCod_UB : 57|1@0+ (1,0) [0|1] "" IHU
 SG_ CDDRollCodDcDcRollCod : 7|8@0+ (1.0,0.0) [0.0|255.0] "Unitless" IHU
 SG_ CDDRollCodDchaRollCod : 15|8@0+ (1.0,0.0) [0.0|255.0] "Unitless" IHU
 SG_ CDDRollCodOnBdRollCod : 23|8@0+ (1.0,0.0) [0.0|255.0] "Unitless" IHU
 SG_ CDDSplyUAct_UB : 56|1@0+ (1,0) [0|1] "" IHU
 SG_ CDDSplyUActDspSplyUAct : 31|8@0+ (0.1,0.0) [0.0|25.5] "Volt" IHU
 SG_ CDDSplyUActMcuSplyUAct : 39|8@0+ (0.1,0.0) [0.0|25.5] "Volt" IHU
 SG_ CDDSplyUActOnBdSplyUAct : 47|8@0+ (0.1,0.0) [0.0|25.5] "Volt" IHU

BO_ 360 CddPropFr03 : 8 CDD
 SG_ CDDLockdUnlckdTyp_UB : 1|1@0+ (1,0) [0|1] "" IHU
 SG_ CDDLockdUnlckdTypElockLockdTyp : 7|3@0+ (1,0) [0|7] "" IHU
 SG_ CDDLockdUnlckdTypElockUnlckdTyp : 4|3@0+ (1,0) [0|7] "" IHU
 SG_ CDDSnsrSts_UB : 8|1@0+ (1,0) [0|1] "" IHU
 SG_ CDDSnsrStsAcISnsrSts : 15|1@0+ (1,0) [0|1] "" IHU
 SG_ CDDSnsrStsAcUSnsrSts : 14|1@0+ (1,0) [0|1] "" IHU
 SG_ CDDSnsrStsHvISnsrSts : 13|1@0+ (1,0) [0|1] "" IHU
 SG_ CDDSnsrStsHvUSnsrSts : 12|1@0+ (1,0) [0|1] "" IHU
 SG_ CDDSnsrStsLvISnsrSts : 11|1@0+ (1,0) [0|1] "" IHU
 SG_ CDDSnsrStsPfcISnsrSts : 10|1@0+ (1,0) [0|1] "" IHU
 SG_ CDDSnsrStsPfcUSnsrSts : 9|1@0+ (1,0) [0|1] "" IHU
 SG_ ElecVehCAN : 39|3@0+ (1,0) [0|7] "" IHU
 SG_ ElecVehCAN_UB : 36|1@0+ (1,0) [0|1] "" IHU
 SG_ ElockAdFb : 23|16@0+ (1.0,0.0) [0.0|65535.0] "Unitless" IHU
 SG_ ElockAdFb_UB : 0|1@0+ (1,0) [0|1] "" IHU
 SG_ UDcDcActLoSide : 47|8@0+ (0.1,0.0) [0.0|25.0] "Volt" IHU
 SG_ UDcDcActLoSide_UB : 35|1@0+ (1,0) [0|1] "" IHU

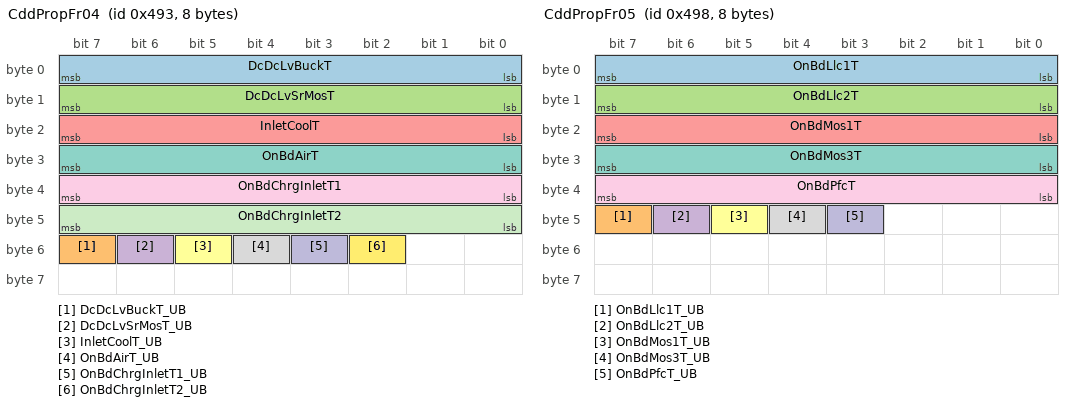
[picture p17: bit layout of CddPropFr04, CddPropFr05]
BO_ 1171 CddPropFr04 : 8 CDD
 SG_ DcDcLvBuckT : 7|8@0+ (1.0,-40.0) [-40.0|215.0] "degC" IHU
 SG_ DcDcLvBuckT_UB : 55|1@0+ (1,0) [0|1] "" IHU
 SG_ DcDcLvSrMosT : 15|8@0+ (1.0,-40.0) [-40.0|215.0] "degC" IHU
 SG_ DcDcLvSrMosT_UB : 54|1@0+ (1,0) [0|1] "" IHU
 SG_ InletCoolT : 23|8@0+ (1.0,-40.0) [-40.0|215.0] "degC" IHU
 SG_ InletCoolT_UB : 53|1@0+ (1,0) [0|1] "" IHU
 SG_ OnBdAirT : 31|8@0+ (1.0,-40.0) [-40.0|215.0] "degC" IHU
 SG_ OnBdAirT_UB : 52|1@0+ (1,0) [0|1] "" IHU
 SG_ OnBdChrgInletT1 : 39|8@0+ (1.0,-40.0) [-40.0|215.0] "degC" IHU
 SG_ OnBdChrgInletT1_UB : 51|1@0+ (1,0) [0|1] "" IHU
 SG_ OnBdChrgInletT2 : 47|8@0+ (1.0,-40.0) [-40.0|215.0] "degC" IHU
 SG_ OnBdChrgInletT2_UB : 50|1@0+ (1,0) [0|1] "" IHU

BO_ 1176 CddPropFr05 : 8 CDD
 SG_ OnBdLlc1T : 7|8@0+ (1.0,-40.0) [-40.0|215.0] "degC" IHU
 SG_ OnBdLlc1T_UB : 47|1@0+ (1,0) [0|1] "" IHU
 SG_ OnBdLlc2T : 15|8@0+ (1.0,-40.0) [-40.0|215.0] "degC" IHU
 SG_ OnBdLlc2T_UB : 46|1@0+ (1,0) [0|1] "" IHU
 SG_ OnBdMos1T : 23|8@0+ (1.0,-40.0) [-40.0|215.0] "degC" IHU
 SG_ OnBdMos1T_UB : 45|1@0+ (1,0) [0|1] "" IHU
 SG_ OnBdMos3T : 31|8@0+ (1.0,-40.0) [-40.0|215.0] "degC" IHU
 SG_ OnBdMos3T_UB : 44|1@0+ (1,0) [0|1] "" IHU
 SG_ OnBdPfcT : 39|8@0+ (1.0,-40.0) [-40.0|215.0] "degC" IHU
 SG_ OnBdPfcT_UB : 43|1@0+ (1,0) [0|1] "" IHU

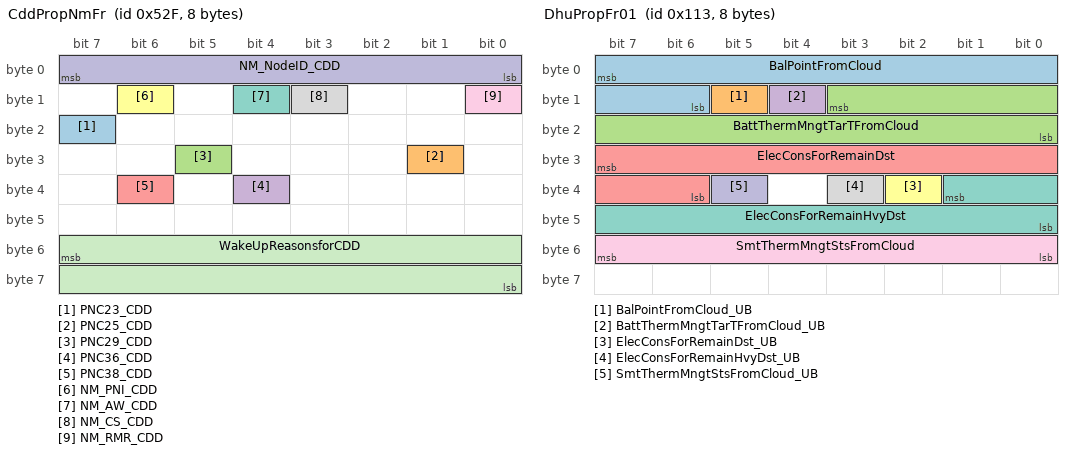
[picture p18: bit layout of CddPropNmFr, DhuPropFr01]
BO_ 1327 CddPropNmFr : 8 CDD
 SG_ PNC23_CDD : 23|1@0+ (1,0) [0|0] "" Vector__XXX
 SG_ PNC25_CDD : 25|1@0+ (1,0) [0|0] "" Vector__XXX
 SG_ PNC29_CDD : 29|1@0+ (1,0) [0|0] "" Vector__XXX
 SG_ PNC36_CDD : 36|1@0+ (1,0) [0|0] "" Vector__XXX
 SG_ PNC38_CDD : 38|1@0+ (1,0) [0|0] "" Vector__XXX
 SG_ NM_PNI_CDD : 14|1@0+ (1,0) [0|0] "" Vector__XXX
 SG_ NM_AW_CDD : 12|1@0+ (1,0) [0|0] "" Vector__XXX
 SG_ NM_CS_CDD : 11|1@0+ (1,0) [0|0] "" Vector__XXX
 SG_ NM_RMR_CDD : 8|1@0+ (1,0) [0|0] "" Vector__XXX
 SG_ NM_NodeID_CDD : 7|8@0+ (1,0) [0|0] "" Vector__XXX

 SG_ WakeUpReasonsforCDD : 55|16@0+ (1,0) [0|65535] "" Vector__XXX

BO_ 1391 CddPropVFCVectorFr : 8 CDD
 SG_ VFCVectorCDDBlockID : 1|2@0+ (1.0,0.0) [0.0|3.0] "Unitless" IHU
 SG_ VFCVectorCDDVFCid0 : 2|1@0+ (1,0) [0|1] "" IHU
 SG_ VFCVectorCDDVFCid1 : 3|1@0+ (1,0) [0|1] "" IHU
 SG_ VFCVectorCDDVFCid10 : 12|1@0+ (1,0) [0|1] "" IHU
 SG_ VFCVectorCDDVFCid11 : 13|1@0+ (1,0) [0|1] "" IHU
 SG_ VFCVectorCDDVFCid12 : 14|1@0+ (1,0) [0|1] "" IHU
 SG_ VFCVectorCDDVFCid13 : 15|1@0+ (1,0) [0|1] "" IHU
 SG_ VFCVectorCDDVFCid14 : 16|1@0+ (1,0) [0|1] "" IHU
 SG_ VFCVectorCDDVFCid15 : 17|1@0+ (1,0) [0|1] "" IHU
 SG_ VFCVectorCDDVFCid16 : 18|1@0+ (1,0) [0|1] "" IHU
 SG_ VFCVectorCDDVFCid17 : 19|1@0+ (1,0) [0|1] "" IHU
 SG_ VFCVectorCDDVFCid18 : 20|1@0+ (1,0) [0|1] "" IHU
 SG_ VFCVectorCDDVFCid19 : 21|1@0+ (1,0) [0|1] "" IHU
 SG_ VFCVectorCDDVFCid2 : 4|1@0+ (1,0) [0|1] "" IHU
 SG_ VFCVectorCDDVFCid20 : 22|1@0+ (1,0) [0|1] "" IHU
 SG_ VFCVectorCDDVFCid21 : 23|1@0+ (1,0) [0|1] "" IHU
 SG_ VFCVectorCDDVFCid22 : 24|1@0+ (1,0) [0|1] "" IHU
 SG_ VFCVectorCDDVFCid23 : 25|1@0+ (1,0) [0|1] "" IHU
 SG_ VFCVectorCDDVFCid24 : 26|1@0+ (1,0) [0|1] "" IHU
 SG_ VFCVectorCDDVFCid25 : 27|1@0+ (1,0) [0|1] "" IHU
 SG_ VFCVectorCDDVFCid26 : 28|1@0+ (1,0) [0|1] "" IHU
 SG_ VFCVectorCDDVFCid27 : 29|1@0+ (1,0) [0|1] "" IHU
 SG_ VFCVectorCDDVFCid28 : 30|1@0+ (1,0) [0|1] "" IHU
 SG_ VFCVectorCDDVFCid29 : 31|1@0+ (1,0) [0|1] "" IHU
 SG_ VFCVectorCDDVFCid3 : 5|1@0+ (1,0) [0|1] "" IHU
 SG_ VFCVectorCDDVFCid30 : 32|1@0+ (1,0) [0|1] "" IHU
 SG_ VFCVectorCDDVFCid31 : 33|1@0+ (1,0) [0|1] "" IHU
 SG_ VFCVectorCDDVFCid32 : 34|1@0+ (1,0) [0|1] "" IHU
 SG_ VFCVectorCDDVFCid33 : 35|1@0+ (1,0) [0|1] "" IHU
 SG_ VFCVectorCDDVFCid34 : 36|1@0+ (1,0) [0|1] "" IHU
 SG_ VFCVectorCDDVFCid35 : 37|1@0+ (1,0) [0|1] "" IHU
 SG_ VFCVectorCDDVFCid36 : 38|1@0+ (1,0) [0|1] "" IHU
 SG_ VFCVectorCDDVFCid37 : 39|1@0+ (1,0) [0|1] "" IHU
 SG_ VFCVectorCDDVFCid38 : 40|1@0+ (1,0) [0|1] "" IHU
 SG_ VFCVectorCDDVFCid39 : 41|1@0+ (1,0) [0|1] "" IHU
 SG_ VFCVectorCDDVFCid4 : 6|1@0+ (1,0) [0|1] "" IHU
 SG_ VFCVectorCDDVFCid40 : 42|1@0+ (1,0) [0|1] "" IHU
 SG_ VFCVectorCDDVFCid41 : 43|1@0+ (1,0) [0|1] "" IHU
 SG_ VFCVectorCDDVFCid42 : 44|1@0+ (1,0) [0|1] "" IHU
 SG_ VFCVectorCDDVFCid43 : 45|1@0+ (1,0) [0|1] "" IHU
 SG_ VFCVectorCDDVFCid44 : 46|1@0+ (1,0) [0|1] "" IHU
 SG_ VFCVectorCDDVFCid45 : 47|1@0+ (1,0) [0|1] "" IHU
 SG_ VFCVectorCDDVFCid46 : 48|1@0+ (1,0) [0|1] "" IHU
 SG_ VFCVectorCDDVFCid47 : 49|1@0+ (1,0) [0|1] "" IHU
 SG_ VFCVectorCDDVFCid48 : 50|1@0+ (1,0) [0|1] "" IHU
 SG_ VFCVectorCDDVFCid49 : 51|1@0+ (1,0) [0|1] "" IHU
 SG_ VFCVectorCDDVFCid5 : 7|1@0+ (1,0) [0|1] "" IHU
 SG_ VFCVectorCDDVFCid50 : 52|1@0+ (1,0) [0|1] "" IHU
 SG_ VFCVectorCDDVFCid51 : 53|1@0+ (1,0) [0|1] "" IHU
 SG_ VFCVectorCDDVFCid52 : 54|1@0+ (1,0) [0|1] "" IHU
 SG_ VFCVectorCDDVFCid53 : 55|1@0+ (1,0) [0|1] "" IHU
 SG_ VFCVectorCDDVFCid54 : 56|1@0+ (1,0) [0|1] "" IHU
 SG_ VFCVectorCDDVFCid55 : 57|1@0+ (1,0) [0|1] "" IHU
 SG_ VFCVectorCDDVFCid56 : 58|1@0+ (1,0) [0|1] "" IHU
 SG_ VFCVectorCDDVFCid57 : 59|1@0+ (1,0) [0|1] "" IHU
 SG_ VFCVectorCDDVFCid58 : 60|1@0+ (1,0) [0|1] "" IHU
 SG_ VFCVectorCDDVFCid59 : 61|1@0+ (1,0) [0|1] "" IHU
 SG_ VFCVectorCDDVFCid6 : 8|1@0+ (1,0) [0|1] "" IHU
 SG_ VFCVectorCDDVFCid60 : 62|1@0+ (1,0) [0|1] "" IHU
 SG_ VFCVectorCDDVFCid61 : 63|1@0+ (1,0) [0|1] "" IHU
 SG_ VFCVectorCDDVFCid7 : 9|1@0+ (1,0) [0|1] "" IHU
 SG_ VFCVectorCDDVFCid8 : 10|1@0+ (1,0) [0|1] "" IHU
 SG_ VFCVectorCDDVFCid9 : 11|1@0+ (1,0) [0|1] "" IHU

BO_ 2029 CddToDhuJ1979OBDPropCanResFrame11 : 8 CDD

BO_ 1475 CddtoEtcXCPFr01 : 8 CDD

BO_ 1476 CddtoEtcXCPFr02 : 8 CDD

BO_ 1477 CddtoEtcXCPFr03 : 8 CDD

BO_ 1616 CddToVddmPropDiagResFrame1 : 8 CDD

BO_ 275 DhuPropFr01 : 8 IHU
 SG_ BalPointFromCloud : 7|10@0+ (0.1,0.0) [0.0|100.0] "%" Vector__XXX
 SG_ BalPointFromCloud_UB : 13|1@0+ (1,0) [0|1] "" Vector__XXX
 SG_ BattThermMngtTarTFromCloud : 11|12@0+ (0.1,-205.0) [-205.0|204.5] "degC" XCU
 SG_ BattThermMngtTarTFromCloud_UB : 12|1@0+ (1,0) [0|1] "" XCU
 SG_ ElecConsForRemainDst : 31|10@0+ (0.1,0.0) [0.0|100.0] "%" XCU
 SG_ ElecConsForRemainDst_UB : 34|1@0+ (1,0) [0|1] "" XCU
 SG_ ElecConsForRemainHvyDst : 33|10@0+ (0.1,0.0) [0.0|100.0] "%" XCU
 SG_ ElecConsForRemainHvyDst_UB : 35|1@0+ (1,0) [0|1] "" XCU
 SG_ SmtThermMngtStsFromCloud : 55|8@0+ (1,0) [0|255] "" XCU
 SG_ SmtThermMngtStsFromCloud_UB : 37|1@0+ (1,0) [0|1] "" XCU

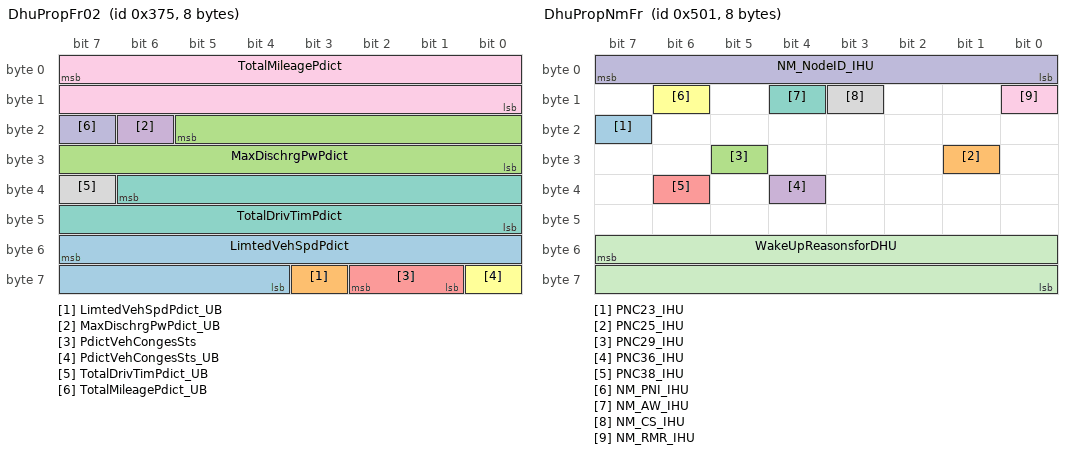
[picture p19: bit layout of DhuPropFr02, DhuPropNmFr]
BO_ 885 DhuPropFr02 : 8 IHU
 SG_ LimtedVehSpdPdict : 55|12@0+ (0.1,0.0) [0.0|409.5] "Km/h" XCU
 SG_ LimtedVehSpdPdict_UB : 59|1@0+ (1,0) [0|1] "" XCU
 SG_ MaxDischrgPwPdict : 21|14@0+ (0.1,0.0) [0.0|1638.3000000000002] "kW" XCU
 SG_ MaxDischrgPwPdict_UB : 22|1@0+ (1,0) [0|1] "" XCU
 SG_ PdictVehCongesSts : 58|2@0+ (1.0,0.0) [0.0|3.0] "Unitless" XCU
 SG_ PdictVehCongesSts_UB : 56|1@0+ (1,0) [0|1] "" XCU
 SG_ TotalDrivTimPdict : 38|15@0+ (0.1,0.0) [0.0|3076.7000000000003] "Mins" XCU
 SG_ TotalDrivTimPdict_UB : 39|1@0+ (1,0) [0|1] "" XCU
 SG_ TotalMileagePdict : 7|16@0+ (0.1,0.0) [0.0|6553.5] "Km/h" XCU
 SG_ TotalMileagePdict_UB : 23|1@0+ (1,0) [0|1] "" XCU

BO_ 896 DhuPropFr03 : 8 IHU
 SG_ DriveStyleFactor : 7|4@0+ (1.0,0.0) [0.0|15.0] "Unitless" XCU
 SG_ DriveStyleFactor_UB : 3|1@0+ (1,0) [0|1] "" XCU
 SG_ PredictinformSts : 2|2@0+ (1.0,0.0) [0.0|3.0] "Unitless" XCU
 SG_ PredictinformSts_UB : 0|1@0+ (1,0) [0|1] "" XCU

BO_ 1281 DhuPropNmFr : 8 IHU
 SG_ PNC23_IHU : 23|1@0+ (1,0) [0|0] "" Vector__XXX
 SG_ PNC25_IHU : 25|1@0+ (1,0) [0|0] "" Vector__XXX
 SG_ PNC29_IHU : 29|1@0+ (1,0) [0|0] "" Vector__XXX
 SG_ PNC36_IHU : 36|1@0+ (1,0) [0|0] "" Vector__XXX
 SG_ PNC38_IHU : 38|1@0+ (1,0) [0|0] "" Vector__XXX
 SG_ NM_PNI_IHU : 14|1@0+ (1,0) [0|0] "" Vector__XXX
 SG_ NM_AW_IHU : 12|1@0+ (1,0) [0|0] "" Vector__XXX
 SG_ NM_CS_IHU : 11|1@0+ (1,0) [0|0] "" Vector__XXX
 SG_ NM_RMR_IHU : 8|1@0+ (1,0) [0|0] "" Vector__XXX
 SG_ NM_NodeID_IHU : 7|8@0+ (1,0) [0|0] "" Vector__XXX

 SG_ WakeUpReasonsforDHU : 55|16@0+ (1,0) [0|65535] "" Vector__XXX

BO_ 2047 DhuToAllFuncPropDiagReqFrame : 8 IHU

BO_ 2015 DhuToAllJ1979OBDPropCanReqFrame11 : 8 IHU

BO_ 2018 DhuToBecmJ1979OBDPropCanReqFrame11 : 8 IHU

BO_ 1845 DhuToBecmPropDiagReqFrame : 8 IHU

BO_ 2021 DhuToCddJ1979OBDPropCanReqFrame11 : 8 IHU

BO_ 1872 DhuToCddPropDiagReqFrame1 : 8 IHU

BO_ 2016 DhuToEcmJ1979OBDPropCanReqFrame11 : 8 IHU

BO_ 1843 DhuToEgsmPropDiagReqFrame : 8 IHU

BO_ 1878 DhuToEvccPropDiagReqFrame : 8 IHU

BO_ 2019 DhuToIemJ1979OBDPropCanReqFrame11 : 8 IHU

BO_ 1847 DhuToIemPropDiagReqFrame : 8 IHU

BO_ 1846 DhuToIgmPropDiagReqFrame : 8 IHU

BO_ 2017 DhuToTcmJ1979OBDPropCanReqFrame11 : 8 IHU

BO_ 1842 DhuToTcmPropDiagReqFrame : 8 IHU

BO_ 1851 DhuToTmcuPropDiagReqFr : 8 IHU

BO_ 2022 DhuToXcuJ1979OBDPropCanReqFrame11 : 8 IHU

BO_ 341 EcmPropComFr10 : 8 XCU
 SG_ TrsmParkLockd_UB : 22|1@0+ (1,0) [0|1] "" EGSM,IHU,ZCUD
 SG_ TrsmParkLockdChks : 31|8@0+ (1.0,0.0) [0.0|255.0] "Unitless" EGSM,IHU,ZCUD
 SG_ TrsmParkLockdCntr : 19|4@0+ (1.0,0.0) [0.0|15.0] "Unitless" EGSM,IHU,ZCUD
 SG_ TrsmParkLockdTrsmParkLockd : 21|2@0+ (1,0) [0|3] "" EGSM,IHU,ZCUD

BO_ 259 EcmPropComFr12 : 8 XCU
 SG_ BookChrgTarValLnr : 31|11@0+ (0.05,0.0) [0.0|100.0] "%" IHU
 SG_ BookChrgTarValLnr_UB : 5|1@0+ (1,0) [0|1] "" IHU

BO_ 74 EcmPropFr00 : 8 XCU
 SG_ AccrPedlRat_UB : 7|1@0+ (1,0) [0|1] "" IHU,ZCUD
 SG_ AccrPedlRatAccrPedlRat : 6|15@0+ (0.00390625,0.0) [0.0|100.0] "%" IHU,ZCUD
 SG_ AccrPedlRatChks : 23|8@0+ (1.0,0.0) [0.0|255.0] "Unitless" IHU,ZCUD
 SG_ AccrPedlRatCntr : 31|4@0+ (1.0,0.0) [0.0|15.0] "Unitless" IHU,ZCUD

BO_ 305 EcmPropFr04 : 8 XCU
 SG_ DcDcActvdReq : 44|1@0+ (1,0) [0|1] "" CDD,IHU,ZCUD
 SG_ DcDcActvdReq_UB : 42|1@0+ (1,0) [0|1] "" CDD,IHU,ZCUD
 SG_ DispHvBattLvlOfChrg : 39|10@0+ (0.1,0.0) [0.0|102.30000000000001] "%" CDD,IHU,ZCUD
 SG_ DispHvBattLvlOfChrg_UB : 43|1@0+ (1,0) [0|1] "" CDD,IHU,ZCUD

BO_ 132 EcmPropFr05 : 8 XCU
 SG_ DchrgnIntState : 36|3@0+ (1,0) [0|7] "" CDD,IHU
 SG_ DchrgnIntState_UB : 53|1@0+ (1,0) [0|1] "" CDD,IHU
 SG_ OnBdChrgrPwrEnaAllwd : 51|1@0+ (1,0) [0|1] "" CDD,IHU
 SG_ OnBdChrgrPwrEnaAllwd_UB : 54|1@0+ (1,0) [0|1] "" CDD,IHU

BO_ 369 EcmPropFr08 : 8 XCU
 SG_ HvBattCoolgCmd : 63|2@0+ (1,0) [0|3] "" IHU
 SG_ HvBattCoolgCmd_UB : 61|1@0+ (1,0) [0|1] "" IHU
 SG_ HvOnMaiReq : 60|2@0+ (1,0) [0|3] "" IHU,ZCUD
 SG_ HvOnMaiReq_UB : 58|1@0+ (1,0) [0|1] "" IHU,ZCUD
 SG_ PrpsnFbLimnIndcn : 22|4@0+ (1.0,0.0) [0.0|15.0] "Unitless" CDD,IHU
 SG_ PrpsnFbLimnIndcn_UB : 23|1@0+ (1,0) [0|1] "" CDD,IHU

BO_ 406 EcmPropFr09 : 8 XCU
 SG_ HvBattChrgnCmd : 52|2@0+ (1,0) [0|3] "" IHU
 SG_ HvBattChrgnCmd_UB : 53|1@0+ (1,0) [0|1] "" IHU

BO_ 647 EcmPropFr11 : 8 XCU
 SG_ BookChargeSetResponse : 62|2@0+ (1,0) [0|3] "" CDD,IHU
 SG_ BookChargeSetResponse_UB : 56|1@0+ (1,0) [0|1] "" CDD,IHU
 SG_ ChrgnSts : 44|3@0+ (1,0) [0|7] "" IHU
 SG_ ChrgnSts_UB : 63|1@0+ (1,0) [0|1] "" IHU
 SG_ CmptmtCoolgSts : 3|4@0+ (1,0) [0|15] "" IHU,ZCUD
 SG_ CmptmtCoolgSts_UB : 4|1@0+ (1,0) [0|1] "" IHU,ZCUD
 SG_ CooltFlowForDtElec : 41|9@0+ (0.1,0.0) [0.0|51.1] "L / min" IHU
 SG_ CooltFlowForDtElec_UB : 6|1@0+ (1,0) [0|1] "" IHU
 SG_ CooltTSigForDtElec : 39|11@0+ (0.1,-40.0) [-40.0|140.0] "degC" IHU
 SG_ CooltTSigForDtElec_UB : 5|1@0+ (1,0) [0|1] "" IHU
 SG_ DchaStopReasonIndcn : 60|3@0+ (1,0) [0|7] "" IHU
 SG_ DchaStopReasonIndcn_UB : 57|1@0+ (1,0) [0|1] "" IHU
 SG_ HvConvPwrAllwd : 15|10@0+ (20.0,0.0) [0.0|20460.0] "W" CDD,IHU
 SG_ HvConvPwrAllwd_UB : 7|1@0+ (1,0) [0|1] "" CDD,IHU
 SG_ MonrCycCmpl : 18|1@0+ (1,0) [0|1] "" IHU
 SG_ MonrCycCmpl_UB : 19|1@0+ (1,0) [0|1] "" IHU
 SG_ PrpsnSysActv : 20|1@0+ (1,0) [0|1] "" Vector__XXX
 SG_ PrpsnSysActv_UB : 21|1@0+ (1,0) [0|1] "" Vector__XXX

BO_ 392 EcmPropFr22 : 8 XCU
 SG_ DchaPwrAllwd : 9|10@0+ (20.0,0.0) [0.0|20460.0] "W" CDD,IHU
 SG_ DchaPwrAllwd_UB : 35|1@0+ (1,0) [0|1] "" CDD,IHU
 SG_ HvBattFlwEstmd : 40|9@0+ (0.1,0.0) [0.0|51.1] "L / min" IHU
 SG_ HvBattFlwEstmd_UB : 43|1@0+ (1,0) [0|1] "" IHU
 SG_ HvBattThermReqFb : 47|4@0+ (1,0) [0|15] "" IHU
 SG_ HvBattThermReqFb_UB : 37|1@0+ (1,0) [0|1] "" IHU

CM_ BU_ EGSM "Electronic Gear Selector Module";
CM_ BU_ ETC "External Tester Connector";

CM_ SG_ 321 HvBattUDc "Actual Hv Battery pack voltage (measuered before contactors, i.e. always giving pack voltage).";
CM_ SG_ 321 HvBattUDynMaxLim "The pack voltage high limit of the Hv Battery, dynamically based on cell voltage distribution. At pack voltages above this limit, there is risk for contactor openeing due to too high cell voltage. ";
CM_ SG_ 321 HvSysActvnInhb "Closing of the contactors is inhibited due to Hv System fault or safety issue.Ok: No fault/issue present,contactors are allowed to be closed.NotOk: Fault/issue present, contactors are inhibited to close.";
CM_ SG_ 321 HvSysPwrOff "Informs vehicle that Hv contactors will open in 2s due to Hv System fault or safety issue (BPO).
Ok: No fault present, contactor will not open.
NotOk: Fault present, contactors will open.";
CM_ SG_ 321 HvSysRlyStsChks "Checksum for E2E";
CM_ SG_ 321 HvSysRlyStsCntr "Counter for E2E";
CM_ SG_ 321 HvSysRlyStsHvSysRlySts "Actual state of the main contactors.";
CM_ SG_ 321 HvSysSts "Hv System Status during integrity test. Informs vehicle that longer Hv System start up time is necessary to perform Extended Integrity Test due to Hv System fault or safety issue.";
CM_ SG_ 373 HvBattUDynMinLim "The pack voltage low limit of the Hv Battery, dynamically based on cell voltage distribution. At pack voltages below this limit, there is risk for contactor openeing due to too low cell voltage";
CM_ SG_ 373 MaintainBattTFb "Battery temperature maintain function control feedback.";
CM_ SG_ 376 HvBattChrgnCmpl "Plug-in charging of the Hv Battery is completed/not completed.";
CM_ SG_ 376 HvBattCoolgReq "Hv Battery request level for cooling .";
CM_ SG_ 376 HvBattILim "Maximum current limit for Hv Battery plug-in charging. Is also used for controlling the charging sequence.";
CM_ SG_ 376 HvBattSoc "Actual state of charge of the Hv Battery.";
CM_ SG_ 376 HvBattULim "Maximum voltage limit for Hv Battery plug-in charging. Is also used for controlling the charging sequence.";
CM_ SG_ 376 HvSysLimnIndcn "Propulsion related LOS (Limited Operation Strategy) information from Hv System.";
CM_ SG_ 659 HvBattEgyCdn "Hv Battery State-of-Health Energy, i.e. ratio of current maximum energy capacity versus that at beginning of life.SOH";
CM_ SG_ 659 HvBattErrIndcnReq "MIL ilumination req from BECU ";
CM_ SG_ 659 HvBattHeatgReq "Hv Battery request level for heating.";
CM_ SG_ 659 HvBattSocLimHi "Upper Hv Battery SOC soft limit: Up to this point nominal power available, linear charge power limit decrease between this limit and HvBattSocLimMax.";
CM_ SG_ 659 HvBattSocLimLo "Lower Hv Battery SOC soft limit: Down to this point nominal power available, linear discharge power limit decrease between this limit and HvBattSocLimMin.";
CM_ SG_ 659 HvBattSocLimMax "Maximum allowable state of charge of the Hv Battery. Used for protection of Hv Battery System.";
CM_ SG_ 659 HvBattSocLimMin "Minimum allowable state of charge of the high voltage battery.   Used for protection of Traction Battery System.";
CM_ SG_ 661 HvBattCoolgSts "Hv Battery cooling request as part of the HVEPM energy prioritization.";
CM_ SG_ 661 HvBattPVal "Pressure in battery pack";
CM_ SG_ 661 HVIL1Sts "HVIL status of Hv Battery connectors";
CM_ SG_ 661 HVIL2Sts "HVIL status of other HV component connectors except Hv Battery ";
CM_ SG_ 661 HVIL3Sts "HVIL status of other HV component connectors except Hv Battery ";
CM_ SG_ 661 HvIsoSts "Isolation status of Hv Battery or Hv System.";
CM_ SG_ 661 HvSysCrashFb "Isolation resistance status after crash: Idle, Ok, Evaluating, Nok.";
CM_ SG_ 662 FastChrgnLockCtrl "Fast charging port locking control request. Off is unlock,on is lock.";
CM_ SG_ 662 HvBattCooltTReq "HvBatt requested coolant temperature.";
CM_ SG_ 662 HvBattHeatStopReqBrkLiOnReqChks "Checksum for E2E";
CM_ SG_ 662 HvBattHeatStopReqBrkLiOnReqCntr "Counter for E2E";
CM_ SG_ 662 HvBattHeatStopReqBrkLiOnReqSts "Hv battery heating stop request ";
CM_ SG_ 662 TotChrgDischTime "Total charge/discharge time";
CM_ SG_ 662 TotSingleChrgEgy "Total Charging Energy";
CM_ SG_ 834 HvBattCodLen "The coding length of pack";
CM_ SG_ 834 HvBattMismatchFlt "the fault of BMSH Battery Mismatching";
CM_ SG_ 834 HvBattNr "the number of the battery subsystem";
CM_ SG_ 834 HvCellTDifFlt "the fault of BMSH CellTemp Uniformity";
CM_ SG_ 834 HvCellTOverFlt "the fault of BMSH Over Temperature";
CM_ SG_ 834 HvCellUDifFlt "the fault of BMSH CellVolt Uniformity";
CM_ SG_ 834 HvCellUOverFlt "the fault of BMSH Cell OverVoltage";
CM_ SG_ 834 HvCellUUnderFlt "the fault of BMSH Cell underVoltage";
CM_ SG_ 834 HvilFlt "the fault of VCU TBOX HVILState";
CM_ SG_ 834 HvIsoFlt "the fault of BMSH InsulationRes Fault";
CM_ SG_ 834 HvPackOverChrgFlt "the fault of BMSH Pack Overcharge";
CM_ SG_ 834 HvPackUOverFlt "the fault of BMSH Pack OverVoltage";
CM_ SG_ 834 HvPackUUnderFlt "the fault of BMSH Pack UnderVoltage";
CM_ SG_ 834 HvSocHiFlt "the fualt of BMSH Over SOC";
CM_ SG_ 834 HvSocHopFlt "the fault of BMSH SOC Hop";
CM_ SG_ 834 HvSocLoFlt "the fualt of BMSH Low SOC";
CM_ SG_ 789 HvBattChrgnSts "Hv Battery charging request as part of the HVEPM energy prioritization ";
CM_ SG_ 789 HvBattTAvg " High Voltage Battery Average Cell Temperature";
CM_ SG_ 789 HvBattTMax "High Voltage Battery Max Cell Temperature";
CM_ SG_ 789 HvBattTMin "High Voltage Battery Min Cell Temperature";
CM_ SG_ 817 HvBattBalFlg "Hv Battery balance flag";
CM_ SG_ 817 HvBattCoolgEgyReq1 "Estimated energy required to cool Hv Battery to target temperature. Part of the HVEPM interface.";
CM_ SG_ 817 HvBattCooltFlowReq "Estimated coolant flow in the Hv Battery Coolant circuit. The estimate is based on pump speed and coolant temperature input";
CM_ SG_ 817 HvBattCooltT "Hv Battery coolant temperature as measured at battery inlet.";
CM_ SG_ 769 DCChaPwrAct "DC Charging Power Actual";
CM_ SG_ 769 HvBattPwrCdn "Hv Battery State-of-Health Power, i.e. ratio of current maximum power capacity versus that at beginning of life. SOH power";
CM_ SG_ 664 HvBattChrgnPwrCns1 "Reports the Hv Battery actual power consumption as part of the HVEPM interface.";
CM_ SG_ 664 HvBattChrgnPwrCritDes1 "Hv Battery critically desired charging power as part of the HVEPM interface.Battery critically";
CM_ SG_ 664 HvBattChrgnPwrNormDes1 "Hv Battery desired charging power as part of the HVEPM interface.";
CM_ SG_ 664 HvBattEgyAvlChrg1 "Usable charge energy up to SOC max limit.";
CM_ SG_ 646 HvBattDchaTiEstimd "The estimated discharging time left and the signal maximum value indicates an invalid value.";
CM_ SG_ 646 HvBattEgyAvlDcha1 "Usable discharge energy down to SOC low limit ";
CM_ SG_ 646 HvBattFullChrgCaution "Remind customer to full charge";
CM_ SG_ 646 HvBattHeatGenn "An estimated heat generation in the component. This is used to predict the cooling need.";
CM_ SG_ 646 HvBattPreHeatFaild "Hv Battery charging preheating failed due to small charging power of OBC.";
CM_ SG_ 646 PackNr "the serial number of the pack subsystem";
CM_ SG_ 323 DCChrgnHndlSts "Fast charging gun connect state";
CM_ SG_ 323 HvBattIDc1 "Hv Battery current. Positive current is discharging the battery.";
CM_ SG_ 323 HvBattPreChrgReq "Hv battery precharge request";
CM_ SG_ 323 HvBattPwrLimChrg1 "Amount of power that the Hv Battery can receive (i.e. max charge power limit).";
CM_ SG_ 323 HvBattPwrLimDcha1 "Amount of power that the Hv Battery can provide (i.e. max discharge power limit).";
CM_ SG_ 323 HvBattPwrLimDchaSoft "Long time horizon discharge power limit for drivability ";
CM_ SG_ 833 HvBattClimaPwr "A continuos estimated battery climatization performance shall be estimated and published by HvBattClimaPwr.";
CM_ SG_ 833 HvBattClrRdyReq "HvBattClrRdyReq is used to clear all DTCs after a reprogramming event.";
CM_ SG_ 833 HvBattHeatgEgyReq "Estimated energy required to cool Hv Battery to target temperature. Part of the HVEPM interface.";
CM_ SG_ 833 TotChrgEgy "Total accumulated charge energy (Ah) ,only for plug-in charging.";
CM_ SG_ 837 HvBattCellTNr "the total number of all cell temperature sensors";
CM_ SG_ 837 HvBattCooltMaxTReq "The maximal coolant temperature be requested";
CM_ SG_ 837 HvBattCooltMinTReq "The minimal coolant temperature be requested.";
CM_ SG_ 837 HvBattPreHeatgReq "Battery preheating request before charging.";
CM_ SG_ 837 HvBattThermMod "Hv battery thermal management mode";
CM_ SG_ 837 HvBattTMaxSerlNr "the serial number of the max celltemperature subsystem";
CM_ SG_ 837 HvBattTMinSerlNr "the serial number of the min celltemperature subsystem";
CM_ SG_ 838 HvBattCooltLvl "HV battery coolant level";
CM_ SG_ 838 HvBattCooltOutletT "Hv Battery coolant temperature as measured at battery Outlet.";
CM_ SG_ 838 HvBattHeatgPwr "A continuos estimated battery heating performance shall be estimated and published by HvBattHeatgPwr, ";
CM_ SG_ 838 HvBattVoltMaxSerlNr "the serial number of the max cellvoltage subsystem";
CM_ SG_ 838 HvBattVoltMinSerlNr "the serial number of the min cellvoltage subsystem";
CM_ SG_ 839 HvBattCodPackCodeX1 "Pack code X1/X7/X13/X19";
CM_ SG_ 839 HvBattCodPackCodeX2 "Pack code X2/X8/X14/X20";
CM_ SG_ 839 HvBattCodPackCodeX3 "Pack code X3/X9/X15/X21";
CM_ SG_ 839 HvBattCodPackCodeX4 "Pack code X4/X10/X16/22";
CM_ SG_ 839 HvBattCodPackCodeX5 "Pack code X5/X11/X17/X23";
CM_ SG_ 839 HvBattCodPackCodeX6 "Pack code X6/X12/18/24";
CM_ SG_ 839 HvBattCodPackIndex "message pack index";
CM_ SG_ 325 CellUMax "Highest voltage currently measured in any cell of the HV battery";
CM_ SG_ 325 CellUMaxId "Number of the HV-battery cell which currently has the highest measured voltage. ";
CM_ SG_ 325 CellUMaxLim "The limiting of highest cell voltage for charging.";
CM_ SG_ 325 CellUMin "Lowest voltage currently measured in any cell of the HV battery";
CM_ SG_ 325 CellUMinId "Number of the HV-battery cell which currently has the lowest measured voltage.";
CM_ SG_ 325 HvBattOverDchaFlg "Hv battery over discharge flag.";
CM_ SG_ 648 DCChrgSt "DC charging state";
CM_ SG_ 648 FastChrgnLEDIndctn "The fast charging indicator state .";
CM_ SG_ 648 HvBattChrgnTiEstimd "The estimated charging time left.";
CM_ SG_ 648 HvBattWMDSts "The working state of BECM.";
CM_ SG_ 648 HvIsoR "BMSH Pack InsulationRes";
CM_ SG_ 83 CPSRU "CPSR voltage";
CM_ SG_ 322 BookTrvlHeatgStsFb "book travel heating states feedback";
CM_ SG_ 322 HvBattCellUInfoU1 "message pack index";
CM_ SG_ 322 HvBattCellUInfoU2 "total pack data number";
CM_ SG_ 322 HvBattCellUInfoU3 "U3 is Cell Total Num(for the first message) U3 is The number of cell that has the maximal voltage in pack(for the second message) U3 is The number of cell that has the minimal voltage in  pack(for the third message) U3 is The cell voltage number(for the fourth,fifth...message) ";
CM_ SG_ 322 HvBattCellUInfoU4 "U4 is The battery voltage (for the first message)U4 is The maximal cell voltage value in pack  (for the second message)U4 is The minimal cell voltage value in pack  (for the third message)U4 is The cell voltage(for the fourth,fifth...message) ";
CM_ SG_ 322 HvBattLimnIndcn "Propulsion related LOS (Limited Operation Strategy) information from Hv Battery. LOS";
CM_ SG_ 656 BookTrvlPreHeatgFb "Feedback for book travel preheating function";
CM_ SG_ 656 HvBattCellTInfoHvBattSnsrT "The cell temperature of Hv battery";
CM_ SG_ 656 HvBattCellTInfoHvBattTMax "High Voltage Battery Max Cell Temperature";
CM_ SG_ 656 HvBattCellTInfoHvBattTMin "High Voltage Battery Min Cell Temperature";
CM_ SG_ 656 HvBattCellTInfoHvBattTSnsrNr "Hv battery temperature sensor number";
CM_ SG_ 656 HvBattCellTInfoHvTempSnsrTMaxsSerlNr "The serial number of max temperature sensor in Hv battery";
CM_ SG_ 656 HvBattCellTInfoHvTempSnsrTMinSerlNr "The serial number of min temperature sensor in Hv battery";
CM_ SG_ 1177 HvBattCap "Rated capacity of the battery.";
CM_ SG_ 1177 TotChrgCap "Total accumulated charge capacity,only for plug-in charging.";
CM_ SG_ 1180 TotDchaCap "Total accumulated discharge capacity,except charging.";
CM_ SG_ 1144 TotDchaEgy "Total accumulated discharge energy (Ah),except charging.";
CM_ SG_ 1155 Therunawy4GHS "thermal runaway signal";
CM_ SG_ 407 BECMAFEComError "AFE com Error flag";
CM_ SG_ 407 BECMBookTrvlHeatgReq "Bool Travel heating request";
CM_ SG_ 407 BECMCurSampSts "current sample status";
CM_ SG_ 407 BECMCVSComFlt "CVS comm fault";
CM_ SG_ 407 BECMDCPreHeatgReq "DC preheating request";
CM_ SG_ 407 BECMHiVolSampSts "HV sample status";
CM_ SG_ 407 BECMIsoCheckCmd "Isolation check command";
CM_ SG_ 407 BECMMainNegCntSts "Main Neg Contactor Status";
CM_ SG_ 407 BECMMainPosCntSts "Main Pos Contactor Status";
CM_ SG_ 407 BECMPreChrgCntSts "Pre Charge Contactor Status";
CM_ SG_ 407 BECMPwrLimtLvl "Power limit level";
CM_ SG_ 407 BECMSupplyVoltKL30 "KL30 volt";
CM_ SG_ 407 BECMSysMod "System mode";
CM_ SG_ 390 FIDChargerFault "FID flag";
CM_ SG_ 390 FIDCRASHEVENT "FID flag";
CM_ SG_ 390 FIDCVTNUNSTABLE "FID flag";
CM_ SG_ 390 FIDDONOTCONNECT "FID flag";
CM_ SG_ 390 FIDECMSINGALMISS "FID flag";
CM_ SG_ 390 FIDHvBattFaultIndcr "FID flag";
CM_ SG_ 390 FIDHvPwrOff "FID flag";
CM_ SG_ 390 FIDHVSOONUNAVAIL "FID flag";
CM_ SG_ 390 FIDInhibitNonbasicThrmReq "FID flag";
CM_ SG_ 390 FIDINHIBITSELFTEST "FID flag";
CM_ SG_ 390 FIDInhibitThermalRequest "FID flag";
CM_ SG_ 390 FIDINSTANTDISCONNECTION "FID flag";
CM_ SG_ 390 FIDLVFault "FID flag";
CM_ SG_ 390 FIDMPMCURDATA "FID flag";
CM_ SG_ 390 FIDMPMCVTNDATA "FID flag";
CM_ SG_ 390 FIDNOBalance "FID flag";
CM_ SG_ 390 FIDNOCHARGING "FID flag";
CM_ SG_ 390 FIDNOCONNECTION "FID flag";
CM_ SG_ 390 FIDNoDCCharging "FID flag";
CM_ SG_ 390 FIDNoDischarging "FID flag";
CM_ SG_ 390 FIDNORESTARTMESSAGE "FID flag";
CM_ SG_ 390 FIDSevereDCChargerFault "FID flag";
CM_ SG_ 390 FIDSTOPSAFELY "FID flag";
CM_ SG_ 390 FIDSYSTEMISOLATIONTEST "FID flag";
CM_ SG_ 390 FIDUDCMODE "FID flag";
CM_ SG_ 404 BECMSwVersion "BMS SW version";
CM_ SG_ 404 BECMUCPSRKL15 "CPSR/KL15 volt";
CM_ SG_ 338 BECMCloudInfoBattGndMosSwSts "GND mos switch status";
CM_ SG_ 338 BECMCloudInfoBattNegMosSwSts "Neg mos switch status";
CM_ SG_ 338 BECMCloudInfoBattPosMosSwSts "Pos mos switch status";
CM_ SG_ 338 BECMCloudInfoBpsPressure "BPS pressure";
CM_ SG_ 338 BECMCloudInfoDcMainNegRlyU "DC mainneg U";
CM_ SG_ 338 BECMCloudInfoDcMainPosRlyU "DC mainpos U";
CM_ SG_ 338 BECMCloudInfoIsoNegHalfBrdgU "Isolation Neg half bridge voltage";
CM_ SG_ 338 BECMCloudInfoIsoPosHalfBrdgU "Isolation Pos half bridge voltage";
CM_ SG_ 338 BECMCloudInfoRelayDriveSts "relays drive status";
CM_ SG_ 338 BECMCloudInfoStM "Bms state machine";
CM_ SG_ 343 BECMBattIsoDetectStatus "Isolation detection status";
CM_ SG_ 343 BECMCSUTemp "CSU temperature";
CM_ SG_ 343 BECMHeatRlyU "heat relay outside voltage";
CM_ SG_ 343 BECMHvFuseBVol "Fuse outside volt";
CM_ SG_ 343 BECMHvFuseCVol "fuse outside voltage";
CM_ SG_ 343 BECMHvNegRlyCirtCurr "negtive catactor circuit current";
CM_ SG_ 343 BECMHvPosRlyCirtCurr "Positive contactor circuit current";
CM_ SG_ 348 BECMHvRelaySupplyU "Relay Supply voltage";
CM_ SG_ 348 BECMLvHVIL1InputU "HVIL1 input voltage";
CM_ SG_ 348 BECMLvHVIL1OutputU "HVIL1Output voltage";
CM_ SG_ 348 BECMLvHVIL2InputU "HVIL2 input voltage";
CM_ SG_ 348 BECMLvHVIL2OutputU "HVIL2 output voltage";
CM_ SG_ 348 BECMLvHVIL3InputU "HVIL3 input voltage";
CM_ SG_ 348 BECMLvHVIL3OutputU "HVIL3 output voltage";
CM_ SG_ 348 BECMMoflgErrHVConn "safety monitor flg";
CM_ SG_ 348 BECMMoflgFrzHVConn "safety monitor flg";
CM_ SG_ 348 BECMMoflgFShOffOT "safety monitor flg";
CM_ SG_ 348 BECMMoflgSShOffOT "safety monitor flg";
CM_ SG_ 348 HvBattSOCE "Pack State of Certified Energy";
CM_ SG_ 350 BECMHvUHvBusU "Pack voltage";
CM_ SG_ 350 BECMHvUHvFuseU "Fuse voltage";
CM_ SG_ 350 BECMHvUHvNegRefU "Pack- Ref point voltage";
CM_ SG_ 350 BECMHvUHvPreReU "Pre-charge Resistance Voltage";
CM_ SG_ 350 BECMHvUMainNegRlyRefU "MainNeg relay outside Ref point voltage";
CM_ SG_ 350 BECMHvUMainNegRlyU "Main Neg Sample voltage";
CM_ SG_ 350 BECMHvUMainPosRlyU "Main Pos sample voltage";
CM_ SG_ 1182 BECMPrpsnDataEvtACnt "BECM cloud big data";
CM_ SG_ 1182 BECMPrpsnDataEvtAData1 "BECM cloud big data";
CM_ SG_ 1182 BECMPrpsnDataEvtAData2 "BECM cloud big data";
CM_ SG_ 1182 BECMPrpsnDataEvtAData3 "BECM cloud big data";
CM_ SG_ 1182 BECMPrpsnDataEvtAData4 "BECM cloud big data";
CM_ SG_ 1182 BECMPrpsnDataEvtAData5 "BECM cloud big data";
CM_ SG_ 1182 BECMPrpsnDataEvtAData6 "BECM cloud big data";
CM_ SG_ 1182 BECMPrpsnDataEvtAID "BECM cloud big data";
CM_ SG_ 1187 BECMPrpsnDataPrdACnt "BECM cloud big data";
CM_ SG_ 1187 BECMPrpsnDataPrdAData1 "BECM cloud big data";
CM_ SG_ 1187 BECMPrpsnDataPrdAData2 "BECM cloud big data";
CM_ SG_ 1187 BECMPrpsnDataPrdAData3 "BECM cloud big data";
CM_ SG_ 1187 BECMPrpsnDataPrdAData4 "BECM cloud big data";
CM_ SG_ 1187 BECMPrpsnDataPrdAData5 "BECM cloud big data";
CM_ SG_ 1187 BECMPrpsnDataPrdAData6 "BECM cloud big data";
CM_ SG_ 1187 BECMPrpsnDataPrdAData7 "BECM cloud big data";
CM_ SG_ 1190 BECMPrpsnDataPrdBCnt "BECM cloud big data";
CM_ SG_ 1190 BECMPrpsnDataPrdBData1 "BECM cloud big data";
CM_ SG_ 1190 BECMPrpsnDataPrdBData2 "BECM cloud big data";
CM_ SG_ 1190 BECMPrpsnDataPrdBData3 "BECM cloud big data";
CM_ SG_ 1190 BECMPrpsnDataPrdBData4 "BECM cloud big data";
CM_ SG_ 1190 BECMPrpsnDataPrdBData5 "BECM cloud big data";
CM_ SG_ 1190 BECMPrpsnDataPrdBData6 "BECM cloud big data";
CM_ SG_ 1190 BECMPrpsnDataPrdBData7 "BECM cloud big data";
CM_ SG_ 1193 BECMPrpsnDataPrdCCnt "BECM cloud big data";
CM_ SG_ 1193 BECMPrpsnDataPrdCData1 "BECM cloud big data";
CM_ SG_ 1193 BECMPrpsnDataPrdCData2 "BECM cloud big data";
CM_ SG_ 1193 BECMPrpsnDataPrdCData3 "BECM cloud big data";
CM_ SG_ 1193 BECMPrpsnDataPrdCData4 "BECM cloud big data";
CM_ SG_ 1193 BECMPrpsnDataPrdCData5 "BECM cloud big data";
CM_ SG_ 1193 BECMPrpsnDataPrdCData6 "BECM cloud big data";
CM_ SG_ 1193 BECMPrpsnDataPrdCData7 "BECM cloud big data";
CM_ SG_ 1195 BECMPrpsnDataPrdDCnt "BECM cloud big data";
CM_ SG_ 1195 BECMPrpsnDataPrdDData1 "BECM cloud big data";
CM_ SG_ 1195 BECMPrpsnDataPrdDData2 "BECM cloud big data";
CM_ SG_ 1195 BECMPrpsnDataPrdDData3 "BECM cloud big data";
CM_ SG_ 1195 BECMPrpsnDataPrdDData4 "BECM cloud big data";
CM_ SG_ 1195 BECMPrpsnDataPrdDData5 "BECM cloud big data";
CM_ SG_ 1195 BECMPrpsnDataPrdDData6 "BECM cloud big data";
CM_ SG_ 1195 BECMPrpsnDataPrdDData7 "BECM cloud big data";
CM_ SG_ 1198 BECMPrpsnDataPrdECnt "BECM cloud big data";
CM_ SG_ 1198 BECMPrpsnDataPrdEData1 "BECM cloud big data";
CM_ SG_ 1198 BECMPrpsnDataPrdEData2 "BECM cloud big data";
CM_ SG_ 1198 BECMPrpsnDataPrdEData3 "BECM cloud big data";
CM_ SG_ 1198 BECMPrpsnDataPrdEData4 "BECM cloud big data";
CM_ SG_ 1198 BECMPrpsnDataPrdEData5 "BECM cloud big data";
CM_ SG_ 1198 BECMPrpsnDataPrdEData6 "BECM cloud big data";
CM_ SG_ 1198 BECMPrpsnDataPrdEData7 "BECM cloud big data";
CM_ SG_ 1201 BECMPrpsnDataPrdFCnt "BECM cloud big data";
CM_ SG_ 1201 BECMPrpsnDataPrdFData1 "BECM cloud big data";
CM_ SG_ 1201 BECMPrpsnDataPrdFData2 "BECM cloud big data";
CM_ SG_ 1201 BECMPrpsnDataPrdFData3 "BECM cloud big data";
CM_ SG_ 1201 BECMPrpsnDataPrdFData4 "BECM cloud big data";
CM_ SG_ 1201 BECMPrpsnDataPrdFData5 "BECM cloud big data";
CM_ SG_ 1201 BECMPrpsnDataPrdFData6 "BECM cloud big data";
CM_ SG_ 1201 BECMPrpsnDataPrdFData7 "BECM cloud big data";
CM_ SG_ 1203 BECMPrpsnDataPrdGCnt "BECM cloud big data";
CM_ SG_ 1203 BECMPrpsnDataPrdGData1 "BECM cloud big data";
CM_ SG_ 1203 BECMPrpsnDataPrdGData2 "BECM cloud big data";
CM_ SG_ 1203 BECMPrpsnDataPrdGData3 "BECM cloud big data";
CM_ SG_ 1203 BECMPrpsnDataPrdGData4 "BECM cloud big data";
CM_ SG_ 1203 BECMPrpsnDataPrdGData5 "BECM cloud big data";
CM_ SG_ 1203 BECMPrpsnDataPrdGData6 "BECM cloud big data";
CM_ SG_ 1203 BECMPrpsnDataPrdGData7 "BECM cloud big data";
CM_ SG_ 1305 WakeupReasonsforBECM "ECUWakeupReasons";
CM_ SG_ 1369 VFCVectorBECMBlockID "BlockID";
CM_ SG_ 1369 VFCVectorBECMVFCid0 "SettingsComfort";
CM_ SG_ 1369 VFCVectorBECMVFCid1 "ParkingDrivingClimatization";
CM_ SG_ 1369 VFCVectorBECMVFCid10 "ExteriorLighting";
CM_ SG_ 1369 VFCVectorBECMVFCid11 "VFC11";
CM_ SG_ 1369 VFCVectorBECMVFCid12 "Alarm";
CM_ SG_ 1369 VFCVectorBECMVFCid13 "VFC13";
CM_ SG_ 1369 VFCVectorBECMVFCid14 "InteriorLighting";
CM_ SG_ 1369 VFCVectorBECMVFCid15 "VFC15";
CM_ SG_ 1369 VFCVectorBECMVFCid16 "Locking";
CM_ SG_ 1369 VFCVectorBECMVFCid17 "RemoteKeyFunctionality";
CM_ SG_ 1369 VFCVectorBECMVFCid18 "PropulsionStart";
CM_ SG_ 1369 VFCVectorBECMVFCid19 "VFC19";
CM_ SG_ 1369 VFCVectorBECMVFCid2 "PostClimatisation";
CM_ SG_ 1369 VFCVectorBECMVFCid20 "VFC20";
CM_ SG_ 1369 VFCVectorBECMVFCid21 "PowerClosures";
CM_ SG_ 1369 VFCVectorBECMVFCid22 "VehicleDriving";
CM_ SG_ 1369 VFCVectorBECMVFCid23 "VFC23";
CM_ SG_ 1369 VFCVectorBECMVFCid24 "SettingsProfile";
CM_ SG_ 1369 VFCVectorBECMVFCid25 "SeatComfortFunctions";
CM_ SG_ 1369 VFCVectorBECMVFCid26 "Brake";
CM_ SG_ 1369 VFCVectorBECMVFCid27 "InfotainmentPoll";
CM_ SG_ 1369 VFCVectorBECMVFCid28 "HVEnergyStorage";
CM_ SG_ 1369 VFCVectorBECMVFCid29 "VFC29";
CM_ SG_ 1369 VFCVectorBECMVFCid3 "PowertrainParkingClimatization";
CM_ SG_ 1369 VFCVectorBECMVFCid30 "TelematicsConnectivity";
CM_ SG_ 1369 VFCVectorBECMVFCid31 "VFC31";
CM_ SG_ 1369 VFCVectorBECMVFCid32 "VFC32";
CM_ SG_ 1369 VFCVectorBECMVFCid33 "Diagnostics";
CM_ SG_ 1369 VFCVectorBECMVFCid34 "VehicleModeManagement";
CM_ SG_ 1369 VFCVectorBECMVFCid35 "TrailerCaravanFunctions";
CM_ SG_ 1369 VFCVectorBECMVFCid36 "Immobilizer";
CM_ SG_ 1369 VFCVectorBECMVFCid37 "Windows";
CM_ SG_ 1369 VFCVectorBECMVFCid38 "Visibility";
CM_ SG_ 1369 VFCVectorBECMVFCid39 "VFC39";
CM_ SG_ 1369 VFCVectorBECMVFCid4 "VFC4";
CM_ SG_ 1369 VFCVectorBECMVFCid40 "VFC40";
CM_ SG_ 1369 VFCVectorBECMVFCid41 "InfotainmentPush";
CM_ SG_ 1369 VFCVectorBECMVFCid42 "ChargingHV";
CM_ SG_ 1369 VFCVectorBECMVFCid43 "BodyPreClimatisation";
CM_ SG_ 1369 VFCVectorBECMVFCid44 "Crash";
CM_ SG_ 1369 VFCVectorBECMVFCid45 "GlobalShortDuration";
CM_ SG_ 1369 VFCVectorBECMVFCid46 "ExteriorLightsHazard";
CM_ SG_ 1369 VFCVectorBECMVFCid47 "VFC47";
CM_ SG_ 1369 VFCVectorBECMVFCid48 "DoorOpenWarning";
CM_ SG_ 1369 VFCVectorBECMVFCid49 "ChargingLVInit";
CM_ SG_ 1369 VFCVectorBECMVFCid5 "VFC5";
CM_ SG_ 1369 VFCVectorBECMVFCid50 "VFC50";
CM_ SG_ 1369 VFCVectorBECMVFCid51 "VFC51";
CM_ SG_ 1369 VFCVectorBECMVFCid52 "HVBatteryThermalEventWarning";
CM_ SG_ 1369 VFCVectorBECMVFCid53 "VisualAssist";
CM_ SG_ 1369 VFCVectorBECMVFCid54 "PassiveSafety";
CM_ SG_ 1369 VFCVectorBECMVFCid55 "LifeDetection";
CM_ SG_ 1369 VFCVectorBECMVFCid56 "BackboneFlexray";
CM_ SG_ 1369 VFCVectorBECMVFCid57 "Functionmarket";
CM_ SG_ 1369 VFCVectorBECMVFCid58 "VFC58";
CM_ SG_ 1369 VFCVectorBECMVFCid59 "VFC59";
CM_ SG_ 1369 VFCVectorBECMVFCid6 "SettingsVehicle";
CM_ SG_ 1369 VFCVectorBECMVFCid60 "VFC60";
CM_ SG_ 1369 VFCVectorBECMVFCid61 "VFC61";
CM_ SG_ 1369 VFCVectorBECMVFCid7 "VFC7";
CM_ SG_ 1369 VFCVectorBECMVFCid8 "VFC8";
CM_ SG_ 1369 VFCVectorBECMVFCid9 "IPWakeup";
CM_ SG_ 331 DcDcActvd "DCDC actived state";
CM_ SG_ 331 DchrgnIntSckState "DC charging Relay connect status";
CM_ SG_ 331 FltElecDcDc "The electrical fault indication of DCDC";
CM_ SG_ 331 FltTDcDc "The temperature fault indication of DCDC";
CM_ SG_ 331 IDcDcActHiSide "Actual measured current on the HV side";
CM_ SG_ 331 IDcDcAvlMaxLoSide "The maximum available current for low voltage loads";
CM_ SG_ 331 UDcDcActHiSide "Measured voltage on the HV side";
CM_ SG_ 329 DcDcCoolgReq "Request for increased cooling flow to DCDC";
CM_ SG_ 329 IDcDcActLoSideChks "Actul current output checksum";
CM_ SG_ 329 IDcDcActLoSideCntr "Actul current output counter";
CM_ SG_ 329 IDcDcActLoSideIDcDcActLoSide "Actul current output";
CM_ SG_ 329 LimnIndcnDcDc "Indication signal from the DcDc that tells that a DTC is set";
CM_ SG_ 329 TDcDc "Temperature of DCDC";
CM_ SG_ 1109 DcDcMinCooltFlow "Minimun coolant flow for DCDC";
CM_ SG_ 1109 TDcDcCoolt "Inlet Coolant Temperature of the DCDC";
CM_ SG_ 536 OnBdChrgrCoolgReq "Request for cooling of the onboard charger. ";
CM_ SG_ 536 OnBdChrgrErrIndcnReqChks "Checksum";
CM_ SG_ 536 OnBdChrgrErrIndcnReqCntr "Counter";
CM_ SG_ 536 OnBdChrgrErrIndcnReqOnBdChrgrErrIndcnReq "Error indication requirement";
CM_ SG_ 536 OnBdChrgrHndlSts1 "Status of the Onboard Charger connection to the grid. ";
CM_ SG_ 536 OnBdChrgrRdyTi "The charging ready time";
CM_ SG_ 536 OnBdChrgrT "Temperature of the onboard charger.";
CM_ SG_ 536 PwrEgyMgrAvl "Available power from OBC to HVEPM (HV Energy Power Manager)";
CM_ SG_ 534 DchaIAct "The discharging current of AC";
CM_ SG_ 534 DchaPwrAct "Acutual discharing power ";
CM_ SG_ 534 DchaPwrReq "Discharging power request to EEM";
CM_ SG_ 534 DchaUAct "The discharging voltage of AC";
CM_ SG_ 534 OnBdChrgrClrRdyReq "Clear diagnostic trouble code request";
CM_ SG_ 534 OnBdChrgrIAct "The actual AC input current";
CM_ SG_ 534 OnBdChrgrSt "The charging state of OBC";
CM_ SG_ 298 DchaEgyAct "The OBC actual AC output discharging energy and which represents a discharge cycle.";
CM_ SG_ 298 DischrgPwrExceedWarn "Warning of excessive discharge power";
CM_ SG_ 298 HndlLockgSts "Status of charge inlet electric lock";
CM_ SG_ 298 OnBdChrgrIDc "The actual DC output current of OBC";
CM_ SG_ 298 OnBdChrgrUAct "The actual AC input voltage";
CM_ SG_ 298 OnBdChrgrUDc "The actual DC output voltage of OBC";
CM_ SG_ 1041 ACChaPwrAct "Actual  AC Charging power";
CM_ SG_ 1041 OnBdChrgrCooltT "Inlet Coolant Temperature of the OBC";
CM_ SG_ 1041 OnBdChrgrMinCooltFlow "Minimun coolant flow for OBC";
CM_ SG_ 785 DchaEgyStrgDchaCarTiGlb "Feedback the time of the OBC storage.";
CM_ SG_ 785 DchaEgyStrgDchaEgy "Feedback the discharge energy of the OBC storage.";
CM_ SG_ 785 MaxACInpISetFdb "Feedback received Maximum AC Input Current Setting.";
CM_ SG_ 785 V2XDchaSwtFdb "Feedback discharging switch status.";
CM_ SG_ 410 OnBdChrgrFcnResvSigGrp "Reserverd signal 1 for New Energy domain";
CM_ SG_ 410 OnBdChrgrFcnResvSigGrp1 "Reserverd signal 2 for New Energy domain";
CM_ SG_ 1184 LimnIndcnOBC "Indication signal from the OBC that tells that a DTC is set.";
CM_ SG_ 339 CDDActStsDcDcIntSts "Internal working status of the DCDC";
CM_ SG_ 339 CDDActStsDchaIntSts "Internal working state in discharge mode";
CM_ SG_ 339 CDDActStsOnBdIntSts "Internal working status of the OBC";
CM_ SG_ 339 CDDActStsOnBdS2Sts "S2 switch status";
CM_ SG_ 339 CDDCcCpInfoCcRes1 "CC resistance value";
CM_ SG_ 339 CDDCcCpInfoCpFrq "CP frequency";
CM_ SG_ 339 CDDCcCpInfoCpInpDuty "Input CP duty cycle";
CM_ SG_ 339 CDDCcCpInfoCpOutpDuty "Output CP duty cycle";
CM_ SG_ 339 CDDCcCpInfoUCpPeak "CP peak voltage";
CM_ SG_ 339 DcChrgRlyStsDCChrgRlyNegSts "DC charging relay negative state";
CM_ SG_ 339 DcChrgRlyStsDCChrgRlyPosSts "DC charging relay positive state";
CM_ SG_ 346 CDDChipRstRsnC1ChipRstRsn "C1 Chip restart event and restart cause";
CM_ SG_ 346 CDDChipRstRsnC2ChipRstRsn "C2 Chip restart event and restart cause";
CM_ SG_ 346 CDDChipRstRsnC3ChipRstRsn "C3 Chip restart event and restart cause";
CM_ SG_ 346 CDDLEDCtrlLEDBluCtrl "Blue LED status";
CM_ SG_ 346 CDDLEDCtrlLEDGrenCtrl "Green LED status";
CM_ SG_ 346 CDDLEDCtrlLEDRedCtrl "Red LED status";
CM_ SG_ 346 CDDRollCodDcDcRollCod "DCDC fault roll code";
CM_ SG_ 346 CDDRollCodDchaRollCod "OBC Discharge fault roll code";
CM_ SG_ 346 CDDRollCodOnBdRollCod "OBC  fault roll code";
CM_ SG_ 346 CDDSplyUActDspSplyUAct "DSP chip 3.3V supply voltage";
CM_ SG_ 346 CDDSplyUActMcuSplyUAct "MCU chip power supply voltage";
CM_ SG_ 346 CDDSplyUActOnBdSplyUAct "ECU Low voltage supply voltage";
CM_ SG_ 360 CDDLockdUnlckdTypElockLockdTyp "Electronic lock lock type";
CM_ SG_ 360 CDDLockdUnlckdTypElockUnlckdTyp "Electronic lock unlock type";
CM_ SG_ 360 CDDSnsrStsAcISnsrSts "Status of the AC current sensor";
CM_ SG_ 360 CDDSnsrStsAcUSnsrSts "Status of the AC voltage sensor";
CM_ SG_ 360 CDDSnsrStsHvISnsrSts "HV current sensor status";
CM_ SG_ 360 CDDSnsrStsHvUSnsrSts "HV voltage sensor status";
CM_ SG_ 360 CDDSnsrStsLvISnsrSts "LV current sensor status";
CM_ SG_ 360 CDDSnsrStsPfcISnsrSts "PFC current sensor status";
CM_ SG_ 360 CDDSnsrStsPfcUSnsrSts "PFC voltage sensor status";
CM_ SG_ 360 ElecVehCAN "Standard type of vehicle Inlet";
CM_ SG_ 360 ElockAdFb "Electronic lock position feedback";
CM_ SG_ 360 UDcDcActLoSide "The actual low-voltage output voltage of DCDC";
CM_ SG_ 1171 DcDcLvBuckT "Actual temperature of the buck";
CM_ SG_ 1171 DcDcLvSrMosT "Actual temperature of the SRMOS";
CM_ SG_ 1171 InletCoolT "Actual temperature of the inlet";
CM_ SG_ 1171 OnBdAirT "Actual temperature of the environment";
CM_ SG_ 1171 OnBdChrgInletT1 "Actual temperature of the charging inlet 1";
CM_ SG_ 1171 OnBdChrgInletT2 "Actual temperature of the charging inlet 2";
CM_ SG_ 1176 OnBdLlc1T "Actual temperature of the LLC1";
CM_ SG_ 1176 OnBdLlc2T "Actual temperature of the LLC2";
CM_ SG_ 1176 OnBdMos1T "Actual temperature of the DcDc MOS1";
CM_ SG_ 1176 OnBdMos3T "Actual temperature of the DCDC MOS1";
CM_ SG_ 1176 OnBdPfcT "Actual temperature of the PFC";
CM_ SG_ 1327 WakeUpReasonsforCDD "WakeUpReasons";
CM_ SG_ 1391 VFCVectorCDDBlockID "BlockID";
CM_ SG_ 1391 VFCVectorCDDVFCid0 "SettingsComfort";
CM_ SG_ 1391 VFCVectorCDDVFCid1 "ParkingDrivingClimatization";
CM_ SG_ 1391 VFCVectorCDDVFCid10 "ExteriorLighting";
CM_ SG_ 1391 VFCVectorCDDVFCid11 "VFC11";
CM_ SG_ 1391 VFCVectorCDDVFCid12 "Alarm";
CM_ SG_ 1391 VFCVectorCDDVFCid13 "VFC13";
CM_ SG_ 1391 VFCVectorCDDVFCid14 "InteriorLighting";
CM_ SG_ 1391 VFCVectorCDDVFCid15 "VFC15";
CM_ SG_ 1391 VFCVectorCDDVFCid16 "Locking";
CM_ SG_ 1391 VFCVectorCDDVFCid17 "RemoteKeyFunctionality";
CM_ SG_ 1391 VFCVectorCDDVFCid18 "PropulsionStart";
CM_ SG_ 1391 VFCVectorCDDVFCid19 "VFC19";
CM_ SG_ 1391 VFCVectorCDDVFCid2 "PostClimatisation";
CM_ SG_ 1391 VFCVectorCDDVFCid20 "VFC20";
CM_ SG_ 1391 VFCVectorCDDVFCid21 "PowerClosures";
CM_ SG_ 1391 VFCVectorCDDVFCid22 "VehicleDriving";
CM_ SG_ 1391 VFCVectorCDDVFCid23 "VFC23";
CM_ SG_ 1391 VFCVectorCDDVFCid24 "SettingsProfile";
CM_ SG_ 1391 VFCVectorCDDVFCid25 "SeatComfortFunctions";
CM_ SG_ 1391 VFCVectorCDDVFCid26 "Brake";
CM_ SG_ 1391 VFCVectorCDDVFCid27 "InfotainmentPoll";
CM_ SG_ 1391 VFCVectorCDDVFCid28 "HVEnergyStorage";
CM_ SG_ 1391 VFCVectorCDDVFCid29 "VFC29";
CM_ SG_ 1391 VFCVectorCDDVFCid3 "PowertrainParkingClimatization";
CM_ SG_ 1391 VFCVectorCDDVFCid30 "TelematicsConnectivity";
CM_ SG_ 1391 VFCVectorCDDVFCid31 "VFC31";
CM_ SG_ 1391 VFCVectorCDDVFCid32 "VFC32";
CM_ SG_ 1391 VFCVectorCDDVFCid33 "Diagnostics";
CM_ SG_ 1391 VFCVectorCDDVFCid34 "VehicleModeManagement";
CM_ SG_ 1391 VFCVectorCDDVFCid35 "TrailerCaravanFunctions";
CM_ SG_ 1391 VFCVectorCDDVFCid36 "Immobilizer";
CM_ SG_ 1391 VFCVectorCDDVFCid37 "Windows";
CM_ SG_ 1391 VFCVectorCDDVFCid38 "Visibility";
CM_ SG_ 1391 VFCVectorCDDVFCid39 "VFC39";
CM_ SG_ 1391 VFCVectorCDDVFCid4 "VFC4";
CM_ SG_ 1391 VFCVectorCDDVFCid40 "VFC40";
CM_ SG_ 1391 VFCVectorCDDVFCid41 "InfotainmentPush";
CM_ SG_ 1391 VFCVectorCDDVFCid42 "ChargingHV";
CM_ SG_ 1391 VFCVectorCDDVFCid43 "BodyPreClimatisation";
CM_ SG_ 1391 VFCVectorCDDVFCid44 "Crash";
CM_ SG_ 1391 VFCVectorCDDVFCid45 "GlobalShortDuration";
CM_ SG_ 1391 VFCVectorCDDVFCid46 "ExteriorLightsHazard";
CM_ SG_ 1391 VFCVectorCDDVFCid47 "VFC47";
CM_ SG_ 1391 VFCVectorCDDVFCid48 "DoorOpenWarning";
CM_ SG_ 1391 VFCVectorCDDVFCid49 "ChargingLVInit";
CM_ SG_ 1391 VFCVectorCDDVFCid5 "VFC5";
CM_ SG_ 1391 VFCVectorCDDVFCid50 "VFC50";
CM_ SG_ 1391 VFCVectorCDDVFCid51 "VFC51";
CM_ SG_ 1391 VFCVectorCDDVFCid52 "HVBatteryThermalEventWarning";
CM_ SG_ 1391 VFCVectorCDDVFCid53 "VisualAssist";
CM_ SG_ 1391 VFCVectorCDDVFCid54 "PassiveSafety";
CM_ SG_ 1391 VFCVectorCDDVFCid55 "LifeDetection";
CM_ SG_ 1391 VFCVectorCDDVFCid56 "BackboneFlexray";
CM_ SG_ 1391 VFCVectorCDDVFCid57 "Functionmarket";
CM_ SG_ 1391 VFCVectorCDDVFCid58 "VFC58";
CM_ SG_ 1391 VFCVectorCDDVFCid59 "VFC59";
CM_ SG_ 1391 VFCVectorCDDVFCid6 "SettingsVehicle";
CM_ SG_ 1391 VFCVectorCDDVFCid60 "VFC60";
CM_ SG_ 1391 VFCVectorCDDVFCid61 "VFC61";
CM_ SG_ 1391 VFCVectorCDDVFCid7 "VFC7";
CM_ SG_ 1391 VFCVectorCDDVFCid8 "VFC8";
CM_ SG_ 1391 VFCVectorCDDVFCid9 "IPWakeup";
CM_ SG_ 275 BalPointFromCloud "Cloud recommended balance point";
CM_ SG_ 275 BattThermMngtTarTFromCloud "Recommended battery thermal management target temperature in the cloud";
CM_ SG_ 275 ElecConsForRemainDst "Pure electric SOC consumption for the remaining distance";
CM_ SG_ 275 ElecConsForRemainHvyDst "Pure electric SOC consumption of the remaining congested road section";
CM_ SG_ 275 SmtThermMngtStsFromCloud "The current state of intelligent thermal management determined by the cloud";
CM_ SG_ 885 LimtedVehSpdPdict "Estimated maximum driving speed in the cloud (usual route)";
CM_ SG_ 885 MaxDischrgPwPdict "Estimated driving demand power in the cloud (usual route)";
CM_ SG_ 885 PdictVehCongesSts "Estimated congestion in the cloud (usual route)";
CM_ SG_ 885 TotalDrivTimPdict "Estimated remaining time in the cloud (usual route)";
CM_ SG_ 885 TotalMileagePdict "Estimated remaining mileage in the cloud (usual route)";
CM_ SG_ 896 DriveStyleFactor "Estimated driving style in the cloud";
CM_ SG_ 896 PredictinformSts "Predict the status of information in the cloud";
CM_ SG_ 1281 WakeUpReasonsforDHU "WakeUpReasons";
CM_ SG_ 341 TrsmParkLockdChks "Checksum for TrsmParkLockd";
CM_ SG_ 341 TrsmParkLockdCntr "Counter for TrsmParkLockd";
CM_ SG_ 341 TrsmParkLockdTrsmParkLockd "Transmission park lock status";
CM_ SG_ 259 BookChrgTarValLnr "Convert Book charge target SOC to BECM";
CM_ SG_ 74 AccrPedlRatAccrPedlRat "Accelerator Pedal Position with adapted 0 point. Value as percentage of fully pressed pedal";
CM_ SG_ 74 AccrPedlRatChks "Accelerator Pedal Position with adapted 0 point. Value as percentage of fully pressed pedal. Checksum";
CM_ SG_ 74 AccrPedlRatCntr "Accelerator Pedal Position with adapted 0 point. Value as percentage of fully pressed pedal. Counter";
CM_ SG_ 305 DcDcActvdReq "Signal requesting the DCDC to be activated after conditions are fullfilled. ";
CM_ SG_ 305 DispHvBattLvlOfChrg "HV battery State-Of-Charge (SOC) value for display to driver. Note: this value may differ from the actual battery SOC. ";
CM_ SG_ 132 DchrgnIntState "Discharge state";
CM_ SG_ 132 OnBdChrgrPwrEnaAllwd "Signaling that the OBC is allowed to deliver power to the car and battery. Flag to sync battery contactor state with OBC power. Battery Contactor shall be closed when OBC supplies HV power; 0 = Do not supply HV power; 1 = Do supply HV power";
CM_ SG_ 369 HvBattCoolgCmd "Information for HvBatt if batterycooling is allowed";
CM_ SG_ 369 HvOnMaiReq "Command to high voltage battery controller to open, close, or retain the high voltage contactor position";
CM_ SG_ 369 PrpsnFbLimnIndcn "Feedback signal that the present limitation has lead to a recofiguraton that has affected the driver.";
CM_ SG_ 406 HvBattChrgnCmd "Information for HvBatt if charging is allowed.";
CM_ SG_ 647 BookChargeSetResponse "Indicate bookcharging set response.";
CM_ SG_ 647 ChrgnSts "Information of vehicle charging status, which is requested from GB/T 32960.";
CM_ SG_ 647 CmptmtCoolgSts "Status of compartment cooling";
CM_ SG_ 647 CooltFlowForDtElec "Predicted coolant low for Electric Drivetrain (ED) coolant circuit.";
CM_ SG_ 647 CooltTSigForDtElec "Coolant temperature measured by sensors installed in emotor cooling citcuit.";
CM_ SG_ 647 DchaStopReasonIndcn "Driver indication signal of discharging function stopped due to remaining energy reached.";
CM_ SG_ 647 HvConvPwrAllwd "Power limitation for DC/DC converter (i.e. sets a limit for power consumption for 12V system). ";
CM_ SG_ 647 MonrCycCmpl "OBD Warm Up Cycle Complete. 0= Not Complete; 1= Complete.";
CM_ SG_ 647 PrpsnSysActv "Indicate whether propulsion system activation has complete or not.";
CM_ SG_ 392 DchaPwrAllwd "Power available for Discharging in real time. From wall socket if plugged in, from propulsion or high voltage battery.";
CM_ SG_ 392 HvBattFlwEstmd "Battery estimated coolant flow.";
CM_ SG_ 392 HvBattThermReqFb "Battery thermal request feedback.";

BA_DEF_  "Baudrate" INT 1000 1000000;
BA_DEF_  "BusType" STRING;
BA_DEF_  "DBName" STRING;
BA_DEF_  "ProtocolType" STRING;
BA_DEF_ BU_ "NmAsrNode" ENUM "No","Yes";
BA_DEF_ BU_ "NmAsrNodeIdentifier" INT 0 255;
BA_DEF_ BO_ "GenMsgCycleTime" INT 0 65536;
BA_DEF_ BO_ "GenMsgDelayTime" INT 0 65536;
BA_DEF_ BO_ "GenMsgSendType" ENUM "cyclic", "spontaneous", "not-used", "not-used", "not-used", "cyclicAndSpontaneous", "not-used", "cyclicIfActive", "NoMsgSendType";
BA_DEF_ BO_ "GenMsgStartDelayTime" INT 0 65536;
BA_DEF_ SG_ "GenSigSendType" ENUM "Cyclic","OnWrite","OnWriteWithRepetition","OnChange","OnChangeWithRepetition","IfActive","IfActiveWithRepetition","NoSigSendType";
BA_DEF_ SG_ "GenSigStartValue" HEX 0 80000000;
BA_DEF_ BO_ "GenMsgILSupport" ENUM "No","Yes";
BA_DEF_ BO_ "NmAsrMessage" ENUM "No","Yes";
BA_DEF_  "NmAsrBaseAddress" HEX 0 536870911;
BA_DEF_  "NmAsrMessageCount" INT 0 255;
BA_DEF_ BU_ "NodeLayerModules" STRING;
BA_DEF_ BU_ "ILused" ENUM "No","Yes";
BA_DEF_ SG_ "GenSigFuncType" ENUM "NoFunction","n/a","n/a","n/a","n/a","n/a","n/a","n/a","n/a","n/a","n/a","n/a","n/a","n/a","n/a","CHK","CNTR","n/a","n/a","n/a","CNTR_AR_01","CRC_AR_01_BOTH","CRC_AR_01_ALT","CRC_AR_01_LOW","CRC_AR_01_NIBBLE","CNTR_AR_04","CRC_AR_04A","CNTR_AR_05","CRC_AR_05";
BA_DEF_ SG_ "GenSigDataID" STRING;

BA_DEF_DEF_ "BusType" "";
BA_DEF_DEF_ "DBName" "";
BA_DEF_DEF_ "ProtocolType" "";
BA_DEF_DEF_ "NmAsrNode" "No";
BA_DEF_DEF_ "NmAsrNodeIdentifier" 0;
BA_DEF_DEF_ "GenSigStartValue" 0;
BA_DEF_DEF_ "GenSigSendType" "NoSigSendType";
BA_DEF_DEF_ "GenMsgCycleTime" 0;
BA_DEF_DEF_ "GenMsgDelayTime" 0;
BA_DEF_DEF_ "GenMsgStartDelayTime" 0;
BA_DEF_DEF_ "GenMsgSendType" "NoMsgSendType";
BA_DEF_DEF_ "GenMsgILSupport" "Yes";
BA_DEF_DEF_ "NmAsrMessage" "No";
BA_DEF_DEF_ "NmAsrBaseAddress" 1280;
BA_DEF_DEF_ "NmAsrMessageCount" 64;
BA_DEF_DEF_ "NodeLayerModules" "CANoeILNLSPA.dll";
BA_DEF_DEF_ "ILused" "Yes";
BA_DEF_DEF_ "GenSigFuncType" "NoFunction";
BA_DEF_DEF_ "GenSigDataID" "";

BA_ "Baudrate" 500000;
BA_ "BusType" "CAN";
BA_ "DBName" "PropulsionCAN";
BA_ "ProtocolType" "CAN";

BA_ "NmAsrNode" BU_ BECM 1;
BA_ "NmAsrNodeIdentifier" BU_ BECM 25;
BA_ "NodeLayerModules" BU_ BECM "CANoeILNLSPA.dll,AsrNM33.dll";

BA_ "NmAsrNode" BU_ CDD 1;
BA_ "NmAsrNodeIdentifier" BU_ CDD 47;
BA_ "NodeLayerModules" BU_ CDD "CANoeILNLSPA.dll,AsrNM33.dll";

BA_ "NmAsrNode" BU_ EGSM 1;
BA_ "NmAsrNodeIdentifier" BU_ EGSM 22;
BA_ "NodeLayerModules" BU_ EGSM "CANoeILNLSPA.dll,AsrNM33.dll";

BA_ "ILused" BU_ ETC 0;

BA_ "NmAsrNode" BU_ IHU 1;
BA_ "NmAsrNodeIdentifier" BU_ IHU 1;
BA_ "NodeLayerModules" BU_ IHU "CANoeILNLSPA.dll,AsrNM33.dll";

BA_ "NmAsrNode" BU_ TMCU 1;
BA_ "NmAsrNodeIdentifier" BU_ TMCU 56;
BA_ "NodeLayerModules" BU_ TMCU "CANoeILNLSPA.dll,AsrNM33.dll";

BA_ "NmAsrNode" BU_ XCU 1;
BA_ "NmAsrNodeIdentifier" BU_ XCU 32;
BA_ "NodeLayerModules" BU_ XCU "CANoeILNLSPA.dll,AsrNM33.dll";

BA_ "NmAsrNode" BU_ ZCUD 1;
BA_ "NmAsrNodeIdentifier" BU_ ZCUD 5;
BA_ "NodeLayerModules" BU_ ZCUD "CANoeILNLSPA.dll,AsrNM33.dll";

BA_ "GenMsgCycleTime" BO_ 321 20.000;
BA_ "GenMsgSendType" BO_ 321 0;

BA_ "GenMsgCycleTime" BO_ 373 100.000;
BA_ "GenMsgSendType" BO_ 373 0;

BA_ "GenMsgCycleTime" BO_ 376 70.000;
BA_ "GenMsgSendType" BO_ 376 0;

BA_ "GenMsgCycleTime" BO_ 659 400.000;
BA_ "GenMsgSendType" BO_ 659 0;

BA_ "GenMsgCycleTime" BO_ 661 600.000;
BA_ "GenMsgSendType" BO_ 661 0;

BA_ "GenMsgCycleTime" BO_ 662 600.000;
BA_ "GenMsgSendType" BO_ 662 0;

BA_ "GenMsgCycleTime" BO_ 834 1000.000;
BA_ "GenMsgSendType" BO_ 834 0;

BA_ "GenMsgCycleTime" BO_ 789 800.000;
BA_ "GenMsgSendType" BO_ 789 0;

BA_ "GenMsgCycleTime" BO_ 817 1000.000;
BA_ "GenMsgSendType" BO_ 817 0;

BA_ "GenMsgCycleTime" BO_ 769 600.000;
BA_ "GenMsgSendType" BO_ 769 0;

BA_ "GenMsgCycleTime" BO_ 664 600.000;
BA_ "GenMsgSendType" BO_ 664 0;

BA_ "GenMsgCycleTime" BO_ 646 140.000;
BA_ "GenMsgSendType" BO_ 646 0;

BA_ "GenMsgCycleTime" BO_ 323 20.000;
BA_ "GenMsgSendType" BO_ 323 0;

BA_ "GenMsgCycleTime" BO_ 833 1000.000;
BA_ "GenMsgSendType" BO_ 833 0;

BA_ "GenMsgCycleTime" BO_ 837 1000.000;
BA_ "GenMsgSendType" BO_ 837 0;

BA_ "GenMsgCycleTime" BO_ 838 1000.000;
BA_ "GenMsgSendType" BO_ 838 0;

BA_ "GenMsgCycleTime" BO_ 839 1000.000;
BA_ "GenMsgSendType" BO_ 839 0;

BA_ "GenMsgCycleTime" BO_ 325 100.000;
BA_ "GenMsgSendType" BO_ 325 0;

BA_ "GenMsgCycleTime" BO_ 648 100.000;
BA_ "GenMsgSendType" BO_ 648 0;

BA_ "GenMsgCycleTime" BO_ 83 100.000;
BA_ "GenMsgSendType" BO_ 83 0;

BA_ "GenMsgCycleTime" BO_ 322 30.000;
BA_ "GenMsgSendType" BO_ 322 0;

BA_ "GenMsgCycleTime" BO_ 656 100.000;
BA_ "GenMsgSendType" BO_ 656 0;

BA_ "GenMsgCycleTime" BO_ 1177 1000.000;
BA_ "GenMsgSendType" BO_ 1177 0;

BA_ "GenMsgCycleTime" BO_ 1180 1000.000;
BA_ "GenMsgSendType" BO_ 1180 0;

BA_ "GenMsgCycleTime" BO_ 1144 1000.000;
BA_ "GenMsgSendType" BO_ 1144 0;

BA_ "GenMsgCycleTime" BO_ 1155 1000.000;
BA_ "GenMsgSendType" BO_ 1155 0;

BA_ "GenMsgCycleTime" BO_ 407 200.000;
BA_ "GenMsgSendType" BO_ 407 0;

BA_ "GenMsgCycleTime" BO_ 390 200.000;
BA_ "GenMsgSendType" BO_ 390 0;

BA_ "GenMsgCycleTime" BO_ 404 200.000;
BA_ "GenMsgSendType" BO_ 404 0;

BA_ "GenMsgCycleTime" BO_ 338 100.000;
BA_ "GenMsgSendType" BO_ 338 0;

BA_ "GenMsgCycleTime" BO_ 343 100.000;
BA_ "GenMsgSendType" BO_ 343 0;

BA_ "GenMsgCycleTime" BO_ 348 100.000;
BA_ "GenMsgSendType" BO_ 348 0;

BA_ "GenMsgCycleTime" BO_ 350 100.000;
BA_ "GenMsgSendType" BO_ 350 0;

BA_ "GenMsgCycleTime" BO_ 1182 1000.000;
BA_ "GenMsgSendType" BO_ 1182 0;

BA_ "GenMsgCycleTime" BO_ 1187 1000.000;
BA_ "GenMsgSendType" BO_ 1187 0;

BA_ "GenMsgCycleTime" BO_ 1190 1000.000;
BA_ "GenMsgSendType" BO_ 1190 0;

BA_ "GenMsgCycleTime" BO_ 1193 1000.000;
BA_ "GenMsgSendType" BO_ 1193 0;

BA_ "GenMsgCycleTime" BO_ 1195 1000.000;
BA_ "GenMsgSendType" BO_ 1195 0;

BA_ "GenMsgCycleTime" BO_ 1198 1000.000;
BA_ "GenMsgSendType" BO_ 1198 0;

BA_ "GenMsgCycleTime" BO_ 1201 1000.000;
BA_ "GenMsgSendType" BO_ 1201 0;

BA_ "GenMsgCycleTime" BO_ 1203 1000.000;
BA_ "GenMsgSendType" BO_ 1203 0;

BA_ "GenMsgDelayTime" BO_ 1305 20.000;
BA_ "GenMsgSendType" BO_ 1305 1;

BA_ "GenMsgCycleTime" BO_ 1369 500.000;
BA_ "GenMsgSendType" BO_ 1369 0;

BA_ "GenMsgDelayTime" BO_ 2026 5.000;
BA_ "GenMsgSendType" BO_ 2026 1;

BA_ "GenMsgDelayTime" BO_ 1589 5.000;
BA_ "GenMsgSendType" BO_ 1589 1;

BA_ "GenMsgCycleTime" BO_ 331 50.000;
BA_ "GenMsgSendType" BO_ 331 0;

BA_ "GenMsgCycleTime" BO_ 329 50.000;
BA_ "GenMsgSendType" BO_ 329 0;

BA_ "GenMsgCycleTime" BO_ 1109 800.000;
BA_ "GenMsgSendType" BO_ 1109 0;

BA_ "GenMsgCycleTime" BO_ 536 100.000;
BA_ "GenMsgSendType" BO_ 536 0;

BA_ "GenMsgCycleTime" BO_ 534 100.000;
BA_ "GenMsgSendType" BO_ 534 0;

BA_ "GenMsgCycleTime" BO_ 298 100.000;
BA_ "GenMsgSendType" BO_ 298 0;

BA_ "GenMsgCycleTime" BO_ 1041 400.000;
BA_ "GenMsgSendType" BO_ 1041 0;

BA_ "GenMsgCycleTime" BO_ 785 100.000;
BA_ "GenMsgSendType" BO_ 785 0;

BA_ "GenMsgCycleTime" BO_ 410 100.000;
BA_ "GenMsgSendType" BO_ 410 0;

BA_ "GenMsgCycleTime" BO_ 1184 1000.000;
BA_ "GenMsgSendType" BO_ 1184 0;

BA_ "GenMsgCycleTime" BO_ 339 100.000;
BA_ "GenMsgSendType" BO_ 339 0;

BA_ "GenMsgCycleTime" BO_ 346 100.000;
BA_ "GenMsgSendType" BO_ 346 0;

BA_ "GenMsgCycleTime" BO_ 360 100.000;
BA_ "GenMsgSendType" BO_ 360 0;

BA_ "GenMsgCycleTime" BO_ 1171 1000.000;
BA_ "GenMsgSendType" BO_ 1171 0;

BA_ "GenMsgCycleTime" BO_ 1176 1000.000;
BA_ "GenMsgSendType" BO_ 1176 0;

BA_ "GenMsgDelayTime" BO_ 1327 20.000;
BA_ "GenMsgSendType" BO_ 1327 1;

BA_ "GenMsgCycleTime" BO_ 1391 500.000;
BA_ "GenMsgSendType" BO_ 1391 0;

BA_ "GenMsgDelayTime" BO_ 2029 5.000;
BA_ "GenMsgSendType" BO_ 2029 1;

BA_ "GenMsgDelayTime" BO_ 1616 5.000;
BA_ "GenMsgSendType" BO_ 1616 1;

BA_ "GenMsgDelayTime" BO_ 1475 10.000;
BA_ "GenMsgSendType" BO_ 1475 1;

BA_ "GenMsgDelayTime" BO_ 1476 10.000;
BA_ "GenMsgSendType" BO_ 1476 1;

BA_ "GenMsgDelayTime" BO_ 1477 10.000;
BA_ "GenMsgSendType" BO_ 1477 1;

BA_ "GenMsgDelayTime" BO_ 275 40.000;
BA_ "GenMsgSendType" BO_ 275 1;

BA_ "GenMsgCycleTime" BO_ 885 460.000;
BA_ "GenMsgSendType" BO_ 885 0;

BA_ "GenMsgCycleTime" BO_ 896 460.000;
BA_ "GenMsgSendType" BO_ 896 0;

BA_ "GenMsgDelayTime" BO_ 1281 20.000;
BA_ "GenMsgSendType" BO_ 1281 1;

BA_ "GenMsgDelayTime" BO_ 2047 5.000;
BA_ "GenMsgSendType" BO_ 2047 1;

BA_ "GenMsgDelayTime" BO_ 2015 5.000;
BA_ "GenMsgSendType" BO_ 2015 1;

BA_ "GenMsgDelayTime" BO_ 2018 5.000;
BA_ "GenMsgSendType" BO_ 2018 1;

BA_ "GenMsgDelayTime" BO_ 1845 5.000;
BA_ "GenMsgSendType" BO_ 1845 1;

BA_ "GenMsgDelayTime" BO_ 2021 5.000;
BA_ "GenMsgSendType" BO_ 2021 1;

BA_ "GenMsgDelayTime" BO_ 1872 5.000;
BA_ "GenMsgSendType" BO_ 1872 1;

BA_ "GenMsgDelayTime" BO_ 2016 5.000;
BA_ "GenMsgSendType" BO_ 2016 1;

BA_ "GenMsgDelayTime" BO_ 1843 5.000;
BA_ "GenMsgSendType" BO_ 1843 1;

BA_ "GenMsgDelayTime" BO_ 1878 5.000;
BA_ "GenMsgSendType" BO_ 1878 1;

BA_ "GenMsgDelayTime" BO_ 2019 5.000;
BA_ "GenMsgSendType" BO_ 2019 1;

BA_ "GenMsgDelayTime" BO_ 1847 5.000;
BA_ "GenMsgSendType" BO_ 1847 1;

BA_ "GenMsgDelayTime" BO_ 1846 5.000;
BA_ "GenMsgSendType" BO_ 1846 1;

BA_ "GenMsgDelayTime" BO_ 2017 5.000;
BA_ "GenMsgSendType" BO_ 2017 1;

BA_ "GenMsgDelayTime" BO_ 1842 5.000;
BA_ "GenMsgSendType" BO_ 1842 1;

BA_ "GenMsgDelayTime" BO_ 1851 5.000;
BA_ "GenMsgSendType" BO_ 1851 1;

BA_ "GenMsgDelayTime" BO_ 2022 5.000;
BA_ "GenMsgSendType" BO_ 2022 1;

BA_ "GenMsgCycleTime" BO_ 341 25.000;
BA_ "GenMsgSendType" BO_ 341 0;

BA_ "GenMsgCycleTime" BO_ 259 20.000;
BA_ "GenMsgSendType" BO_ 259 0;

BA_ "GenMsgCycleTime" BO_ 74 10.000;
BA_ "GenMsgSendType" BO_ 74 0;

BA_ "GenMsgCycleTime" BO_ 305 20.000;
BA_ "GenMsgSendType" BO_ 305 0;

BA_ "GenMsgCycleTime" BO_ 132 25.000;
BA_ "GenMsgSendType" BO_ 132 0;

BA_ "GenMsgCycleTime" BO_ 369 50.000;
BA_ "GenMsgSendType" BO_ 369 0;

BA_ "GenMsgCycleTime" BO_ 406 70.000;
BA_ "GenMsgSendType" BO_ 406 0;

BA_ "GenMsgCycleTime" BO_ 647 300.000;
BA_ "GenMsgSendType" BO_ 647 0;

BA_ "GenMsgCycleTime" BO_ 392 70.000;
BA_ "GenMsgSendType" BO_ 392 0;
BA_ "GenMsgILSupport" BO_ 1305 0;
BA_ "GenMsgILSupport" BO_ 1327 0;
BA_ "GenMsgILSupport" BO_ 1281 0;
BA_ "NmAsrMessage" BO_ 1305 1;
BA_ "NmAsrMessage" BO_ 1327 1;
BA_ "NmAsrMessage" BO_ 1281 1;
BA_ "GenSigSendType" SG_ 1041 ACChaPwrAct 0;
BA_ "GenSigSendType" SG_ 74 AccrPedlRatAccrPedlRat 0;
BA_ "GenSigDataID" SG_ 74 AccrPedlRatChks "0x364";
BA_ "GenSigFuncType" SG_ 74 AccrPedlRatChks 15;
BA_ "GenSigSendType" SG_ 74 AccrPedlRatChks 0;
BA_ "GenSigFuncType" SG_ 74 AccrPedlRatCntr 16;
BA_ "GenSigSendType" SG_ 74 AccrPedlRatCntr 0;
BA_ "GenSigSendType" SG_ 407 BECMAFEComError 0;
BA_ "GenSigSendType" SG_ 343 BECMBattIsoDetectStatus 0;
BA_ "GenSigSendType" SG_ 407 BECMBookTrvlHeatgReq 0;
BA_ "GenSigSendType" SG_ 343 BECMCSUTemp 0;
BA_ "GenSigSendType" SG_ 407 BECMCVSComFlt 0;
BA_ "GenSigSendType" SG_ 338 BECMCloudInfoBattGndMosSwSts 0;
BA_ "GenSigSendType" SG_ 338 BECMCloudInfoBattNegMosSwSts 0;
BA_ "GenSigSendType" SG_ 338 BECMCloudInfoBattPosMosSwSts 0;
BA_ "GenSigSendType" SG_ 338 BECMCloudInfoBpsPressure 0;
BA_ "GenSigSendType" SG_ 338 BECMCloudInfoDcMainNegRlyU 0;
BA_ "GenSigSendType" SG_ 338 BECMCloudInfoDcMainPosRlyU 0;
BA_ "GenSigSendType" SG_ 338 BECMCloudInfoIsoNegHalfBrdgU 0;
BA_ "GenSigSendType" SG_ 338 BECMCloudInfoIsoPosHalfBrdgU 0;
BA_ "GenSigSendType" SG_ 338 BECMCloudInfoRelayDriveSts 0;
BA_ "GenSigSendType" SG_ 338 BECMCloudInfoStM 0;
BA_ "GenSigSendType" SG_ 407 BECMCurSampSts 0;
BA_ "GenSigSendType" SG_ 407 BECMDCPreHeatgReq 0;
BA_ "GenSigSendType" SG_ 343 BECMHeatRlyU 0;
BA_ "GenSigSendType" SG_ 407 BECMHiVolSampSts 0;
BA_ "GenSigSendType" SG_ 343 BECMHvFuseBVol 0;
BA_ "GenSigSendType" SG_ 343 BECMHvFuseCVol 0;
BA_ "GenSigSendType" SG_ 343 BECMHvNegRlyCirtCurr 0;
BA_ "GenSigSendType" SG_ 343 BECMHvPosRlyCirtCurr 0;
BA_ "GenSigSendType" SG_ 348 BECMHvRelaySupplyU 0;
BA_ "GenSigSendType" SG_ 350 BECMHvUHvBusU 0;
BA_ "GenSigSendType" SG_ 350 BECMHvUHvFuseU 0;
BA_ "GenSigSendType" SG_ 350 BECMHvUHvNegRefU 0;
BA_ "GenSigSendType" SG_ 350 BECMHvUHvPreReU 0;
BA_ "GenSigSendType" SG_ 350 BECMHvUMainNegRlyRefU 0;
BA_ "GenSigSendType" SG_ 350 BECMHvUMainNegRlyU 0;
BA_ "GenSigSendType" SG_ 350 BECMHvUMainPosRlyU 0;
BA_ "GenSigSendType" SG_ 407 BECMIsoCheckCmd 0;
BA_ "GenSigStartValue" SG_ 407 BECMIsoCheckCmd 1;
BA_ "GenSigSendType" SG_ 348 BECMLvHVIL1InputU 0;
BA_ "GenSigSendType" SG_ 348 BECMLvHVIL1OutputU 0;
BA_ "GenSigSendType" SG_ 348 BECMLvHVIL2InputU 0;
BA_ "GenSigSendType" SG_ 348 BECMLvHVIL2OutputU 0;
BA_ "GenSigSendType" SG_ 348 BECMLvHVIL3InputU 0;
BA_ "GenSigSendType" SG_ 348 BECMLvHVIL3OutputU 0;
BA_ "GenSigSendType" SG_ 407 BECMMainNegCntSts 0;
BA_ "GenSigSendType" SG_ 407 BECMMainPosCntSts 0;
BA_ "GenSigSendType" SG_ 348 BECMMoflgErrHVConn 0;
BA_ "GenSigSendType" SG_ 348 BECMMoflgFShOffOT 0;
BA_ "GenSigSendType" SG_ 348 BECMMoflgFrzHVConn 0;
BA_ "GenSigSendType" SG_ 348 BECMMoflgSShOffOT 0;
BA_ "GenSigSendType" SG_ 407 BECMPreChrgCntSts 0;
BA_ "GenSigSendType" SG_ 1182 BECMPrpsnDataEvtACnt 0;
BA_ "GenSigSendType" SG_ 1182 BECMPrpsnDataEvtAData1 0;
BA_ "GenSigSendType" SG_ 1182 BECMPrpsnDataEvtAData2 0;
BA_ "GenSigSendType" SG_ 1182 BECMPrpsnDataEvtAData3 0;
BA_ "GenSigSendType" SG_ 1182 BECMPrpsnDataEvtAData4 0;
BA_ "GenSigSendType" SG_ 1182 BECMPrpsnDataEvtAData5 0;
BA_ "GenSigSendType" SG_ 1182 BECMPrpsnDataEvtAData6 0;
BA_ "GenSigSendType" SG_ 1182 BECMPrpsnDataEvtAID 0;
BA_ "GenSigSendType" SG_ 1187 BECMPrpsnDataPrdACnt 0;
BA_ "GenSigSendType" SG_ 1187 BECMPrpsnDataPrdAData1 0;
BA_ "GenSigSendType" SG_ 1187 BECMPrpsnDataPrdAData2 0;
BA_ "GenSigSendType" SG_ 1187 BECMPrpsnDataPrdAData3 0;
BA_ "GenSigSendType" SG_ 1187 BECMPrpsnDataPrdAData4 0;
BA_ "GenSigSendType" SG_ 1187 BECMPrpsnDataPrdAData5 0;
BA_ "GenSigSendType" SG_ 1187 BECMPrpsnDataPrdAData6 0;
BA_ "GenSigSendType" SG_ 1187 BECMPrpsnDataPrdAData7 0;
BA_ "GenSigSendType" SG_ 1190 BECMPrpsnDataPrdBCnt 0;
BA_ "GenSigSendType" SG_ 1190 BECMPrpsnDataPrdBData1 0;
BA_ "GenSigSendType" SG_ 1190 BECMPrpsnDataPrdBData2 0;
BA_ "GenSigSendType" SG_ 1190 BECMPrpsnDataPrdBData3 0;
BA_ "GenSigSendType" SG_ 1190 BECMPrpsnDataPrdBData4 0;
BA_ "GenSigSendType" SG_ 1190 BECMPrpsnDataPrdBData5 0;
BA_ "GenSigSendType" SG_ 1190 BECMPrpsnDataPrdBData6 0;
BA_ "GenSigSendType" SG_ 1190 BECMPrpsnDataPrdBData7 0;
BA_ "GenSigSendType" SG_ 1193 BECMPrpsnDataPrdCCnt 0;
BA_ "GenSigSendType" SG_ 1193 BECMPrpsnDataPrdCData1 0;
BA_ "GenSigSendType" SG_ 1193 BECMPrpsnDataPrdCData2 0;
BA_ "GenSigSendType" SG_ 1193 BECMPrpsnDataPrdCData3 0;
BA_ "GenSigSendType" SG_ 1193 BECMPrpsnDataPrdCData4 0;
BA_ "GenSigSendType" SG_ 1193 BECMPrpsnDataPrdCData5 0;
BA_ "GenSigSendType" SG_ 1193 BECMPrpsnDataPrdCData6 0;
BA_ "GenSigSendType" SG_ 1193 BECMPrpsnDataPrdCData7 0;
BA_ "GenSigSendType" SG_ 1195 BECMPrpsnDataPrdDCnt 0;
BA_ "GenSigSendType" SG_ 1195 BECMPrpsnDataPrdDData1 0;
BA_ "GenSigSendType" SG_ 1195 BECMPrpsnDataPrdDData2 0;
BA_ "GenSigSendType" SG_ 1195 BECMPrpsnDataPrdDData3 0;
BA_ "GenSigSendType" SG_ 1195 BECMPrpsnDataPrdDData4 0;
BA_ "GenSigSendType" SG_ 1195 BECMPrpsnDataPrdDData5 0;
BA_ "GenSigSendType" SG_ 1195 BECMPrpsnDataPrdDData6 0;
BA_ "GenSigSendType" SG_ 1195 BECMPrpsnDataPrdDData7 0;
BA_ "GenSigSendType" SG_ 1198 BECMPrpsnDataPrdECnt 0;
BA_ "GenSigSendType" SG_ 1198 BECMPrpsnDataPrdEData1 0;
BA_ "GenSigSendType" SG_ 1198 BECMPrpsnDataPrdEData2 0;
BA_ "GenSigSendType" SG_ 1198 BECMPrpsnDataPrdEData3 0;
BA_ "GenSigSendType" SG_ 1198 BECMPrpsnDataPrdEData4 0;
BA_ "GenSigSendType" SG_ 1198 BECMPrpsnDataPrdEData5 0;
BA_ "GenSigSendType" SG_ 1198 BECMPrpsnDataPrdEData6 0;
BA_ "GenSigSendType" SG_ 1198 BECMPrpsnDataPrdEData7 0;
BA_ "GenSigSendType" SG_ 1201 BECMPrpsnDataPrdFCnt 0;
BA_ "GenSigSendType" SG_ 1201 BECMPrpsnDataPrdFData1 0;
BA_ "GenSigSendType" SG_ 1201 BECMPrpsnDataPrdFData2 0;
BA_ "GenSigSendType" SG_ 1201 BECMPrpsnDataPrdFData3 0;
BA_ "GenSigSendType" SG_ 1201 BECMPrpsnDataPrdFData4 0;
BA_ "GenSigSendType" SG_ 1201 BECMPrpsnDataPrdFData5 0;
BA_ "GenSigSendType" SG_ 1201 BECMPrpsnDataPrdFData6 0;
BA_ "GenSigSendType" SG_ 1201 BECMPrpsnDataPrdFData7 0;
BA_ "GenSigSendType" SG_ 1203 BECMPrpsnDataPrdGCnt 0;
BA_ "GenSigSendType" SG_ 1203 BECMPrpsnDataPrdGData1 0;
BA_ "GenSigSendType" SG_ 1203 BECMPrpsnDataPrdGData2 0;
BA_ "GenSigSendType" SG_ 1203 BECMPrpsnDataPrdGData3 0;
BA_ "GenSigSendType" SG_ 1203 BECMPrpsnDataPrdGData4 0;
BA_ "GenSigSendType" SG_ 1203 BECMPrpsnDataPrdGData5 0;
BA_ "GenSigSendType" SG_ 1203 BECMPrpsnDataPrdGData6 0;
BA_ "GenSigSendType" SG_ 1203 BECMPrpsnDataPrdGData7 0;
BA_ "GenSigSendType" SG_ 407 BECMPwrLimtLvl 0;
BA_ "GenSigSendType" SG_ 407 BECMSupplyVoltKL30 0;
BA_ "GenSigSendType" SG_ 404 BECMSwVersion 0;
BA_ "GenSigSendType" SG_ 407 BECMSysMod 0;
BA_ "GenSigSendType" SG_ 404 BECMUCPSRKL15 0;
BA_ "GenSigSendType" SG_ 275 BalPointFromCloud 1;
BA_ "GenSigSendType" SG_ 275 BattThermMngtTarTFromCloud 1;
BA_ "GenSigStartValue" SG_ 275 BattThermMngtTarTFromCloud 2050;
BA_ "GenSigSendType" SG_ 647 BookChargeSetResponse 0;
BA_ "GenSigSendType" SG_ 259 BookChrgTarValLnr 0;
BA_ "GenSigStartValue" SG_ 259 BookChrgTarValLnr 2000;
BA_ "GenSigSendType" SG_ 322 BookTrvlHeatgStsFb 0;
BA_ "GenSigSendType" SG_ 656 BookTrvlPreHeatgFb 0;
BA_ "GenSigSendType" SG_ 339 CDDActStsDcDcIntSts 0;
BA_ "GenSigStartValue" SG_ 339 CDDActStsDcDcIntSts 1;
BA_ "GenSigSendType" SG_ 339 CDDActStsDchaIntSts 0;
BA_ "GenSigStartValue" SG_ 339 CDDActStsDchaIntSts 1;
BA_ "GenSigSendType" SG_ 339 CDDActStsOnBdIntSts 0;
BA_ "GenSigStartValue" SG_ 339 CDDActStsOnBdIntSts 1;
BA_ "GenSigSendType" SG_ 339 CDDActStsOnBdS2Sts 0;
BA_ "GenSigSendType" SG_ 339 CDDCcCpInfoCcRes1 0;
BA_ "GenSigSendType" SG_ 339 CDDCcCpInfoCpFrq 0;
BA_ "GenSigSendType" SG_ 339 CDDCcCpInfoCpInpDuty 0;
BA_ "GenSigSendType" SG_ 339 CDDCcCpInfoCpOutpDuty 0;
BA_ "GenSigSendType" SG_ 339 CDDCcCpInfoUCpPeak 0;
BA_ "GenSigSendType" SG_ 346 CDDChipRstRsnC1ChipRstRsn 0;
BA_ "GenSigSendType" SG_ 346 CDDChipRstRsnC2ChipRstRsn 0;
BA_ "GenSigSendType" SG_ 346 CDDChipRstRsnC3ChipRstRsn 0;
BA_ "GenSigSendType" SG_ 346 CDDLEDCtrlLEDBluCtrl 0;
BA_ "GenSigSendType" SG_ 346 CDDLEDCtrlLEDGrenCtrl 0;
BA_ "GenSigSendType" SG_ 346 CDDLEDCtrlLEDRedCtrl 0;
BA_ "GenSigSendType" SG_ 360 CDDLockdUnlckdTypElockLockdTyp 0;
BA_ "GenSigSendType" SG_ 360 CDDLockdUnlckdTypElockUnlckdTyp 0;
BA_ "GenSigSendType" SG_ 346 CDDRollCodDcDcRollCod 0;
BA_ "GenSigSendType" SG_ 346 CDDRollCodDchaRollCod 0;
BA_ "GenSigSendType" SG_ 346 CDDRollCodOnBdRollCod 0;
BA_ "GenSigSendType" SG_ 360 CDDSnsrStsAcISnsrSts 0;
BA_ "GenSigSendType" SG_ 360 CDDSnsrStsAcUSnsrSts 0;
BA_ "GenSigSendType" SG_ 360 CDDSnsrStsHvISnsrSts 0;
BA_ "GenSigSendType" SG_ 360 CDDSnsrStsHvUSnsrSts 0;
BA_ "GenSigSendType" SG_ 360 CDDSnsrStsLvISnsrSts 0;
BA_ "GenSigSendType" SG_ 360 CDDSnsrStsPfcISnsrSts 0;
BA_ "GenSigSendType" SG_ 360 CDDSnsrStsPfcUSnsrSts 0;
BA_ "GenSigSendType" SG_ 346 CDDSplyUActDspSplyUAct 0;
BA_ "GenSigSendType" SG_ 346 CDDSplyUActMcuSplyUAct 0;
BA_ "GenSigSendType" SG_ 346 CDDSplyUActOnBdSplyUAct 0;
BA_ "GenSigSendType" SG_ 83 CPSRU 0;
BA_ "GenSigSendType" SG_ 325 CellUMax 0;
BA_ "GenSigSendType" SG_ 325 CellUMaxId 0;
BA_ "GenSigSendType" SG_ 325 CellUMaxLim 0;
BA_ "GenSigSendType" SG_ 325 CellUMin 0;
BA_ "GenSigSendType" SG_ 325 CellUMinId 0;
BA_ "GenSigSendType" SG_ 647 ChrgnSts 0;
BA_ "GenSigStartValue" SG_ 647 ChrgnSts 3;
BA_ "GenSigSendType" SG_ 647 CmptmtCoolgSts 0;
BA_ "GenSigSendType" SG_ 647 CooltFlowForDtElec 0;
BA_ "GenSigSendType" SG_ 647 CooltTSigForDtElec 0;
BA_ "GenSigStartValue" SG_ 647 CooltTSigForDtElec 400;
BA_ "GenSigSendType" SG_ 769 DCChaPwrAct 0;
BA_ "GenSigSendType" SG_ 648 DCChrgSt 0;
BA_ "GenSigSendType" SG_ 323 DCChrgnHndlSts 0;
BA_ "GenSigSendType" SG_ 339 DcChrgRlyStsDCChrgRlyNegSts 0;
BA_ "GenSigSendType" SG_ 339 DcChrgRlyStsDCChrgRlyPosSts 0;
BA_ "GenSigSendType" SG_ 331 DcDcActvd 0;
BA_ "GenSigSendType" SG_ 305 DcDcActvdReq 0;
BA_ "GenSigSendType" SG_ 329 DcDcCoolgReq 0;
BA_ "GenSigSendType" SG_ 1171 DcDcLvBuckT 0;
BA_ "GenSigStartValue" SG_ 1171 DcDcLvBuckT 40;
BA_ "GenSigSendType" SG_ 1171 DcDcLvSrMosT 0;
BA_ "GenSigStartValue" SG_ 1171 DcDcLvSrMosT 40;
BA_ "GenSigSendType" SG_ 1109 DcDcMinCooltFlow 0;
BA_ "GenSigStartValue" SG_ 1109 DcDcMinCooltFlow 20;
BA_ "GenSigSendType" SG_ 298 DchaEgyAct 0;
BA_ "GenSigSendType" SG_ 785 DchaEgyStrgDchaCarTiGlb 0;
BA_ "GenSigSendType" SG_ 785 DchaEgyStrgDchaEgy 0;
BA_ "GenSigSendType" SG_ 534 DchaIAct 0;
BA_ "GenSigSendType" SG_ 534 DchaPwrAct 0;
BA_ "GenSigSendType" SG_ 392 DchaPwrAllwd 0;
BA_ "GenSigSendType" SG_ 534 DchaPwrReq 0;
BA_ "GenSigSendType" SG_ 647 DchaStopReasonIndcn 0;
BA_ "GenSigSendType" SG_ 534 DchaUAct 0;
BA_ "GenSigSendType" SG_ 331 DchrgnIntSckState 0;
BA_ "GenSigSendType" SG_ 132 DchrgnIntState 0;
BA_ "GenSigSendType" SG_ 298 DischrgPwrExceedWarn 0;
BA_ "GenSigSendType" SG_ 305 DispHvBattLvlOfChrg 0;
BA_ "GenSigSendType" SG_ 896 DriveStyleFactor 0;
BA_ "GenSigSendType" SG_ 275 ElecConsForRemainDst 1;
BA_ "GenSigSendType" SG_ 275 ElecConsForRemainHvyDst 1;
BA_ "GenSigSendType" SG_ 360 ElecVehCAN 0;
BA_ "GenSigSendType" SG_ 360 ElockAdFb 0;
BA_ "GenSigSendType" SG_ 390 FIDCRASHEVENT 0;
BA_ "GenSigSendType" SG_ 390 FIDCVTNUNSTABLE 0;
BA_ "GenSigSendType" SG_ 390 FIDChargerFault 0;
BA_ "GenSigSendType" SG_ 390 FIDDONOTCONNECT 0;
BA_ "GenSigSendType" SG_ 390 FIDECMSINGALMISS 0;
BA_ "GenSigSendType" SG_ 390 FIDHVSOONUNAVAIL 0;
BA_ "GenSigSendType" SG_ 390 FIDHvBattFaultIndcr 0;
BA_ "GenSigSendType" SG_ 390 FIDHvPwrOff 0;
BA_ "GenSigSendType" SG_ 390 FIDINHIBITSELFTEST 0;
BA_ "GenSigSendType" SG_ 390 FIDINSTANTDISCONNECTION 0;
BA_ "GenSigSendType" SG_ 390 FIDInhibitNonbasicThrmReq 0;
BA_ "GenSigSendType" SG_ 390 FIDInhibitThermalRequest 0;
BA_ "GenSigSendType" SG_ 390 FIDLVFault 0;
BA_ "GenSigSendType" SG_ 390 FIDMPMCURDATA 0;
BA_ "GenSigSendType" SG_ 390 FIDMPMCVTNDATA 0;
BA_ "GenSigSendType" SG_ 390 FIDNOBalance 0;
BA_ "GenSigSendType" SG_ 390 FIDNOCHARGING 0;
BA_ "GenSigSendType" SG_ 390 FIDNOCONNECTION 0;
BA_ "GenSigSendType" SG_ 390 FIDNORESTARTMESSAGE 0;
BA_ "GenSigSendType" SG_ 390 FIDNoDCCharging 0;
BA_ "GenSigSendType" SG_ 390 FIDNoDischarging 0;
BA_ "GenSigSendType" SG_ 390 FIDSTOPSAFELY 0;
BA_ "GenSigSendType" SG_ 390 FIDSYSTEMISOLATIONTEST 0;
BA_ "GenSigSendType" SG_ 390 FIDSevereDCChargerFault 0;
BA_ "GenSigSendType" SG_ 390 FIDUDCMODE 0;
BA_ "GenSigSendType" SG_ 648 FastChrgnLEDIndctn 0;
BA_ "GenSigSendType" SG_ 662 FastChrgnLockCtrl 0;
BA_ "GenSigSendType" SG_ 331 FltElecDcDc 0;
BA_ "GenSigSendType" SG_ 331 FltTDcDc 0;
BA_ "GenSigSendType" SG_ 661 HVIL1Sts 0;
BA_ "GenSigStartValue" SG_ 661 HVIL1Sts 1;
BA_ "GenSigSendType" SG_ 661 HVIL2Sts 0;
BA_ "GenSigStartValue" SG_ 661 HVIL2Sts 1;
BA_ "GenSigSendType" SG_ 661 HVIL3Sts 0;
BA_ "GenSigStartValue" SG_ 661 HVIL3Sts 1;
BA_ "GenSigSendType" SG_ 298 HndlLockgSts 0;
BA_ "GenSigSendType" SG_ 817 HvBattBalFlg 0;
BA_ "GenSigSendType" SG_ 1177 HvBattCap 0;
BA_ "GenSigSendType" SG_ 656 HvBattCellTInfoHvBattSnsrT 0;
BA_ "GenSigStartValue" SG_ 656 HvBattCellTInfoHvBattSnsrT 40;
BA_ "GenSigSendType" SG_ 656 HvBattCellTInfoHvBattTMax 0;
BA_ "GenSigStartValue" SG_ 656 HvBattCellTInfoHvBattTMax 40;
BA_ "GenSigSendType" SG_ 656 HvBattCellTInfoHvBattTMin 0;
BA_ "GenSigStartValue" SG_ 656 HvBattCellTInfoHvBattTMin 40;
BA_ "GenSigSendType" SG_ 656 HvBattCellTInfoHvBattTSnsrNr 0;
BA_ "GenSigSendType" SG_ 656 HvBattCellTInfoHvTempSnsrTMaxsSerlNr 0;
BA_ "GenSigSendType" SG_ 656 HvBattCellTInfoHvTempSnsrTMinSerlNr 0;
BA_ "GenSigSendType" SG_ 837 HvBattCellTNr 0;
BA_ "GenSigSendType" SG_ 322 HvBattCellUInfoU1 0;
BA_ "GenSigSendType" SG_ 322 HvBattCellUInfoU2 0;
BA_ "GenSigSendType" SG_ 322 HvBattCellUInfoU3 0;
BA_ "GenSigSendType" SG_ 322 HvBattCellUInfoU4 0;
BA_ "GenSigSendType" SG_ 406 HvBattChrgnCmd 0;
BA_ "GenSigStartValue" SG_ 406 HvBattChrgnCmd 1;
BA_ "GenSigSendType" SG_ 376 HvBattChrgnCmpl 0;
BA_ "GenSigSendType" SG_ 664 HvBattChrgnPwrCns1 0;
BA_ "GenSigSendType" SG_ 664 HvBattChrgnPwrCritDes1 0;
BA_ "GenSigSendType" SG_ 664 HvBattChrgnPwrNormDes1 0;
BA_ "GenSigSendType" SG_ 789 HvBattChrgnSts 0;
BA_ "GenSigStartValue" SG_ 789 HvBattChrgnSts 1;
BA_ "GenSigSendType" SG_ 648 HvBattChrgnTiEstimd 0;
BA_ "GenSigStartValue" SG_ 648 HvBattChrgnTiEstimd 2047;
BA_ "GenSigSendType" SG_ 833 HvBattClimaPwr 0;
BA_ "GenSigSendType" SG_ 833 HvBattClrRdyReq 0;
BA_ "GenSigSendType" SG_ 834 HvBattCodLen 0;
BA_ "GenSigStartValue" SG_ 834 HvBattCodLen 1;
BA_ "GenSigSendType" SG_ 839 HvBattCodPackCodeX1 0;
BA_ "GenSigSendType" SG_ 839 HvBattCodPackCodeX2 0;
BA_ "GenSigSendType" SG_ 839 HvBattCodPackCodeX3 0;
BA_ "GenSigSendType" SG_ 839 HvBattCodPackCodeX4 0;
BA_ "GenSigSendType" SG_ 839 HvBattCodPackCodeX5 0;
BA_ "GenSigSendType" SG_ 839 HvBattCodPackCodeX6 0;
BA_ "GenSigSendType" SG_ 839 HvBattCodPackIndex 0;
BA_ "GenSigSendType" SG_ 369 HvBattCoolgCmd 0;
BA_ "GenSigStartValue" SG_ 369 HvBattCoolgCmd 1;
BA_ "GenSigSendType" SG_ 817 HvBattCoolgEgyReq1 0;
BA_ "GenSigSendType" SG_ 376 HvBattCoolgReq 0;
BA_ "GenSigSendType" SG_ 661 HvBattCoolgSts 0;
BA_ "GenSigStartValue" SG_ 661 HvBattCoolgSts 1;
BA_ "GenSigSendType" SG_ 817 HvBattCooltFlowReq 0;
BA_ "GenSigSendType" SG_ 838 HvBattCooltLvl 0;
BA_ "GenSigSendType" SG_ 837 HvBattCooltMaxTReq 0;
BA_ "GenSigStartValue" SG_ 837 HvBattCooltMaxTReq 50;
BA_ "GenSigSendType" SG_ 837 HvBattCooltMinTReq 0;
BA_ "GenSigStartValue" SG_ 837 HvBattCooltMinTReq 50;
BA_ "GenSigSendType" SG_ 838 HvBattCooltOutletT 0;
BA_ "GenSigStartValue" SG_ 838 HvBattCooltOutletT 600;
BA_ "GenSigSendType" SG_ 817 HvBattCooltT 0;
BA_ "GenSigStartValue" SG_ 817 HvBattCooltT 600;
BA_ "GenSigSendType" SG_ 662 HvBattCooltTReq 0;
BA_ "GenSigStartValue" SG_ 662 HvBattCooltTReq 50;
BA_ "GenSigSendType" SG_ 646 HvBattDchaTiEstimd 0;
BA_ "GenSigStartValue" SG_ 646 HvBattDchaTiEstimd 2047;
BA_ "GenSigSendType" SG_ 664 HvBattEgyAvlChrg1 0;
BA_ "GenSigSendType" SG_ 646 HvBattEgyAvlDcha1 0;
BA_ "GenSigSendType" SG_ 659 HvBattEgyCdn 0;
BA_ "GenSigSendType" SG_ 659 HvBattErrIndcnReq 0;
BA_ "GenSigSendType" SG_ 392 HvBattFlwEstmd 0;
BA_ "GenSigSendType" SG_ 646 HvBattFullChrgCaution 0;
BA_ "GenSigSendType" SG_ 646 HvBattHeatGenn 0;
BA_ "GenSigDataID" SG_ 662 HvBattHeatStopReqBrkLiOnReqChks "0x1B5D";
BA_ "GenSigFuncType" SG_ 662 HvBattHeatStopReqBrkLiOnReqChks 15;
BA_ "GenSigSendType" SG_ 662 HvBattHeatStopReqBrkLiOnReqChks 0;
BA_ "GenSigFuncType" SG_ 662 HvBattHeatStopReqBrkLiOnReqCntr 16;
BA_ "GenSigSendType" SG_ 662 HvBattHeatStopReqBrkLiOnReqCntr 0;
BA_ "GenSigSendType" SG_ 662 HvBattHeatStopReqBrkLiOnReqSts 0;
BA_ "GenSigSendType" SG_ 833 HvBattHeatgEgyReq 0;
BA_ "GenSigSendType" SG_ 838 HvBattHeatgPwr 0;
BA_ "GenSigSendType" SG_ 659 HvBattHeatgReq 0;
BA_ "GenSigSendType" SG_ 323 HvBattIDc1 0;
BA_ "GenSigStartValue" SG_ 323 HvBattIDc1 16380;
BA_ "GenSigSendType" SG_ 376 HvBattILim 0;
BA_ "GenSigSendType" SG_ 322 HvBattLimnIndcn 0;
BA_ "GenSigSendType" SG_ 834 HvBattMismatchFlt 0;
BA_ "GenSigSendType" SG_ 834 HvBattNr 0;
BA_ "GenSigStartValue" SG_ 834 HvBattNr 1;
BA_ "GenSigSendType" SG_ 325 HvBattOverDchaFlg 0;
BA_ "GenSigSendType" SG_ 661 HvBattPVal 0;
BA_ "GenSigStartValue" SG_ 661 HvBattPVal 1000;
BA_ "GenSigSendType" SG_ 323 HvBattPreChrgReq 0;
BA_ "GenSigSendType" SG_ 646 HvBattPreHeatFaild 0;
BA_ "GenSigSendType" SG_ 837 HvBattPreHeatgReq 0;
BA_ "GenSigSendType" SG_ 769 HvBattPwrCdn 0;
BA_ "GenSigSendType" SG_ 323 HvBattPwrLimChrg1 0;
BA_ "GenSigSendType" SG_ 323 HvBattPwrLimDcha1 0;
BA_ "GenSigSendType" SG_ 323 HvBattPwrLimDchaSoft 0;
BA_ "GenSigSendType" SG_ 348 HvBattSOCE 0;
BA_ "GenSigStartValue" SG_ 348 HvBattSOCE 200;
BA_ "GenSigSendType" SG_ 376 HvBattSoc 0;
BA_ "GenSigSendType" SG_ 659 HvBattSocLimHi 0;
BA_ "GenSigSendType" SG_ 659 HvBattSocLimLo 0;
BA_ "GenSigSendType" SG_ 659 HvBattSocLimMax 0;
BA_ "GenSigSendType" SG_ 659 HvBattSocLimMin 0;
BA_ "GenSigSendType" SG_ 789 HvBattTAvg 0;
BA_ "GenSigSendType" SG_ 789 HvBattTMax 0;
BA_ "GenSigSendType" SG_ 837 HvBattTMaxSerlNr 0;
BA_ "GenSigStartValue" SG_ 837 HvBattTMaxSerlNr 1;
BA_ "GenSigSendType" SG_ 789 HvBattTMin 0;
BA_ "GenSigSendType" SG_ 837 HvBattTMinSerlNr 0;
BA_ "GenSigStartValue" SG_ 837 HvBattTMinSerlNr 1;
BA_ "GenSigSendType" SG_ 837 HvBattThermMod 0;
BA_ "GenSigSendType" SG_ 392 HvBattThermReqFb 0;
BA_ "GenSigSendType" SG_ 321 HvBattUDc 0;
BA_ "GenSigSendType" SG_ 321 HvBattUDynMaxLim 0;
BA_ "GenSigSendType" SG_ 373 HvBattUDynMinLim 0;
BA_ "GenSigSendType" SG_ 376 HvBattULim 0;
BA_ "GenSigSendType" SG_ 838 HvBattVoltMaxSerlNr 0;
BA_ "GenSigStartValue" SG_ 838 HvBattVoltMaxSerlNr 1;
BA_ "GenSigSendType" SG_ 838 HvBattVoltMinSerlNr 0;
BA_ "GenSigStartValue" SG_ 838 HvBattVoltMinSerlNr 1;
BA_ "GenSigSendType" SG_ 648 HvBattWMDSts 0;
BA_ "GenSigSendType" SG_ 834 HvCellTDifFlt 0;
BA_ "GenSigSendType" SG_ 834 HvCellTOverFlt 0;
BA_ "GenSigSendType" SG_ 834 HvCellUDifFlt 0;
BA_ "GenSigSendType" SG_ 834 HvCellUOverFlt 0;
BA_ "GenSigSendType" SG_ 834 HvCellUUnderFlt 0;
BA_ "GenSigSendType" SG_ 647 HvConvPwrAllwd 0;
BA_ "GenSigStartValue" SG_ 647 HvConvPwrAllwd 1023;
BA_ "GenSigSendType" SG_ 834 HvIsoFlt 0;
BA_ "GenSigSendType" SG_ 648 HvIsoR 0;
BA_ "GenSigStartValue" SG_ 648 HvIsoR 5000;
BA_ "GenSigSendType" SG_ 661 HvIsoSts 0;
BA_ "GenSigSendType" SG_ 369 HvOnMaiReq 0;
BA_ "GenSigStartValue" SG_ 369 HvOnMaiReq 2;
BA_ "GenSigSendType" SG_ 834 HvPackOverChrgFlt 0;
BA_ "GenSigSendType" SG_ 834 HvPackUOverFlt 0;
BA_ "GenSigSendType" SG_ 834 HvPackUUnderFlt 0;
BA_ "GenSigSendType" SG_ 834 HvSocHiFlt 0;
BA_ "GenSigSendType" SG_ 834 HvSocHopFlt 0;
BA_ "GenSigSendType" SG_ 834 HvSocLoFlt 0;
BA_ "GenSigSendType" SG_ 321 HvSysActvnInhb 0;
BA_ "GenSigSendType" SG_ 661 HvSysCrashFb 0;
BA_ "GenSigSendType" SG_ 376 HvSysLimnIndcn 0;
BA_ "GenSigSendType" SG_ 321 HvSysPwrOff 0;
BA_ "GenSigDataID" SG_ 321 HvSysRlyStsChks "0x15";
BA_ "GenSigFuncType" SG_ 321 HvSysRlyStsChks 15;
BA_ "GenSigSendType" SG_ 321 HvSysRlyStsChks 0;
BA_ "GenSigFuncType" SG_ 321 HvSysRlyStsCntr 16;
BA_ "GenSigSendType" SG_ 321 HvSysRlyStsCntr 0;
BA_ "GenSigSendType" SG_ 321 HvSysRlyStsHvSysRlySts 0;
BA_ "GenSigStartValue" SG_ 321 HvSysRlyStsHvSysRlySts 2;
BA_ "GenSigSendType" SG_ 321 HvSysSts 0;
BA_ "GenSigSendType" SG_ 834 HvilFlt 0;
BA_ "GenSigSendType" SG_ 331 IDcDcActHiSide 0;
BA_ "GenSigStartValue" SG_ 331 IDcDcActHiSide 4100;
BA_ "GenSigDataID" SG_ 329 IDcDcActLoSideChks "0x14";
BA_ "GenSigFuncType" SG_ 329 IDcDcActLoSideChks 15;
BA_ "GenSigSendType" SG_ 329 IDcDcActLoSideChks 0;
BA_ "GenSigFuncType" SG_ 329 IDcDcActLoSideCntr 16;
BA_ "GenSigSendType" SG_ 329 IDcDcActLoSideCntr 0;
BA_ "GenSigSendType" SG_ 329 IDcDcActLoSideIDcDcActLoSide 0;
BA_ "GenSigSendType" SG_ 331 IDcDcAvlMaxLoSide 0;
BA_ "GenSigSendType" SG_ 1171 InletCoolT 0;
BA_ "GenSigStartValue" SG_ 1171 InletCoolT 40;
BA_ "GenSigSendType" SG_ 329 LimnIndcnDcDc 0;
BA_ "GenSigSendType" SG_ 1184 LimnIndcnOBC 0;
BA_ "GenSigSendType" SG_ 885 LimtedVehSpdPdict 0;
BA_ "GenSigSendType" SG_ 373 MaintainBattTFb 0;
BA_ "GenSigSendType" SG_ 785 MaxACInpISetFdb 0;
BA_ "GenSigStartValue" SG_ 785 MaxACInpISetFdb 64;
BA_ "GenSigSendType" SG_ 885 MaxDischrgPwPdict 0;
BA_ "GenSigSendType" SG_ 647 MonrCycCmpl 0;
BA_ "GenSigSendType" SG_ 1171 OnBdAirT 0;
BA_ "GenSigStartValue" SG_ 1171 OnBdAirT 40;
BA_ "GenSigSendType" SG_ 1171 OnBdChrgInletT1 0;
BA_ "GenSigStartValue" SG_ 1171 OnBdChrgInletT1 40;
BA_ "GenSigSendType" SG_ 1171 OnBdChrgInletT2 0;
BA_ "GenSigStartValue" SG_ 1171 OnBdChrgInletT2 40;
BA_ "GenSigSendType" SG_ 534 OnBdChrgrClrRdyReq 0;
BA_ "GenSigSendType" SG_ 536 OnBdChrgrCoolgReq 0;
BA_ "GenSigSendType" SG_ 1041 OnBdChrgrCooltT 0;
BA_ "GenSigStartValue" SG_ 1041 OnBdChrgrCooltT 40;
BA_ "GenSigDataID" SG_ 536 OnBdChrgrErrIndcnReqChks "0x1A";
BA_ "GenSigFuncType" SG_ 536 OnBdChrgrErrIndcnReqChks 15;
BA_ "GenSigSendType" SG_ 536 OnBdChrgrErrIndcnReqChks 0;
BA_ "GenSigFuncType" SG_ 536 OnBdChrgrErrIndcnReqCntr 16;
BA_ "GenSigSendType" SG_ 536 OnBdChrgrErrIndcnReqCntr 0;
BA_ "GenSigSendType" SG_ 536 OnBdChrgrErrIndcnReqOnBdChrgrErrIndcnReq 0;
BA_ "GenSigSendType" SG_ 410 OnBdChrgrFcnResvSigGrp 0;
BA_ "GenSigSendType" SG_ 410 OnBdChrgrFcnResvSigGrp1 0;
BA_ "GenSigSendType" SG_ 536 OnBdChrgrHndlSts1 0;
BA_ "GenSigStartValue" SG_ 536 OnBdChrgrHndlSts1 8;
BA_ "GenSigSendType" SG_ 534 OnBdChrgrIAct 0;
BA_ "GenSigStartValue" SG_ 534 OnBdChrgrIAct 2000;
BA_ "GenSigSendType" SG_ 298 OnBdChrgrIDc 0;
BA_ "GenSigStartValue" SG_ 298 OnBdChrgrIDc 2000;
BA_ "GenSigSendType" SG_ 1041 OnBdChrgrMinCooltFlow 0;
BA_ "GenSigStartValue" SG_ 1041 OnBdChrgrMinCooltFlow 20;
BA_ "GenSigSendType" SG_ 132 OnBdChrgrPwrEnaAllwd 0;
BA_ "GenSigSendType" SG_ 536 OnBdChrgrRdyTi 0;
BA_ "GenSigSendType" SG_ 534 OnBdChrgrSt 0;
BA_ "GenSigSendType" SG_ 536 OnBdChrgrT 0;
BA_ "GenSigStartValue" SG_ 536 OnBdChrgrT 40;
BA_ "GenSigSendType" SG_ 298 OnBdChrgrUAct 0;
BA_ "GenSigSendType" SG_ 298 OnBdChrgrUDc 0;
BA_ "GenSigSendType" SG_ 1176 OnBdLlc1T 0;
BA_ "GenSigStartValue" SG_ 1176 OnBdLlc1T 40;
BA_ "GenSigSendType" SG_ 1176 OnBdLlc2T 0;
BA_ "GenSigStartValue" SG_ 1176 OnBdLlc2T 40;
BA_ "GenSigSendType" SG_ 1176 OnBdMos1T 0;
BA_ "GenSigStartValue" SG_ 1176 OnBdMos1T 40;
BA_ "GenSigSendType" SG_ 1176 OnBdMos3T 0;
BA_ "GenSigStartValue" SG_ 1176 OnBdMos3T 40;
BA_ "GenSigSendType" SG_ 1176 OnBdPfcT 0;
BA_ "GenSigStartValue" SG_ 1176 OnBdPfcT 40;
BA_ "GenSigSendType" SG_ 646 PackNr 0;
BA_ "GenSigStartValue" SG_ 646 PackNr 1;
BA_ "GenSigSendType" SG_ 885 PdictVehCongesSts 0;
BA_ "GenSigSendType" SG_ 896 PredictinformSts 0;
BA_ "GenSigSendType" SG_ 369 PrpsnFbLimnIndcn 0;
BA_ "GenSigSendType" SG_ 647 PrpsnSysActv 0;
BA_ "GenSigSendType" SG_ 536 PwrEgyMgrAvl 0;
BA_ "GenSigSendType" SG_ 275 SmtThermMngtStsFromCloud 1;
BA_ "GenSigSendType" SG_ 329 TDcDc 0;
BA_ "GenSigStartValue" SG_ 329 TDcDc 40;
BA_ "GenSigSendType" SG_ 1109 TDcDcCoolt 0;
BA_ "GenSigStartValue" SG_ 1109 TDcDcCoolt 40;
BA_ "GenSigSendType" SG_ 1155 Therunawy4GHS 0;
BA_ "GenSigSendType" SG_ 1177 TotChrgCap 0;
BA_ "GenSigSendType" SG_ 662 TotChrgDischTime 0;
BA_ "GenSigSendType" SG_ 833 TotChrgEgy 0;
BA_ "GenSigSendType" SG_ 1180 TotDchaCap 0;
BA_ "GenSigSendType" SG_ 1144 TotDchaEgy 0;
BA_ "GenSigSendType" SG_ 662 TotSingleChrgEgy 0;
BA_ "GenSigSendType" SG_ 885 TotalDrivTimPdict 0;
BA_ "GenSigSendType" SG_ 885 TotalMileagePdict 0;
BA_ "GenSigDataID" SG_ 341 TrsmParkLockdChks "0x32";
BA_ "GenSigFuncType" SG_ 341 TrsmParkLockdChks 15;
BA_ "GenSigSendType" SG_ 341 TrsmParkLockdChks 0;
BA_ "GenSigFuncType" SG_ 341 TrsmParkLockdCntr 16;
BA_ "GenSigSendType" SG_ 341 TrsmParkLockdCntr 0;
BA_ "GenSigSendType" SG_ 341 TrsmParkLockdTrsmParkLockd 0;
BA_ "GenSigStartValue" SG_ 341 TrsmParkLockdTrsmParkLockd 3;
BA_ "GenSigSendType" SG_ 331 UDcDcActHiSide 0;
BA_ "GenSigSendType" SG_ 360 UDcDcActLoSide 0;
BA_ "GenSigSendType" SG_ 785 V2XDchaSwtFdb 0;
BA_ "GenSigSendType" SG_ 1369 VFCVectorBECMBlockID 0;
BA_ "GenSigSendType" SG_ 1369 VFCVectorBECMVFCid0 0;
BA_ "GenSigSendType" SG_ 1369 VFCVectorBECMVFCid1 0;
BA_ "GenSigSendType" SG_ 1369 VFCVectorBECMVFCid10 0;
BA_ "GenSigSendType" SG_ 1369 VFCVectorBECMVFCid11 0;
BA_ "GenSigSendType" SG_ 1369 VFCVectorBECMVFCid12 0;
BA_ "GenSigSendType" SG_ 1369 VFCVectorBECMVFCid13 0;
BA_ "GenSigSendType" SG_ 1369 VFCVectorBECMVFCid14 0;
BA_ "GenSigSendType" SG_ 1369 VFCVectorBECMVFCid15 0;
BA_ "GenSigSendType" SG_ 1369 VFCVectorBECMVFCid16 0;
BA_ "GenSigSendType" SG_ 1369 VFCVectorBECMVFCid17 0;
BA_ "GenSigSendType" SG_ 1369 VFCVectorBECMVFCid18 0;
BA_ "GenSigSendType" SG_ 1369 VFCVectorBECMVFCid19 0;
BA_ "GenSigSendType" SG_ 1369 VFCVectorBECMVFCid2 0;
BA_ "GenSigSendType" SG_ 1369 VFCVectorBECMVFCid20 0;
BA_ "GenSigSendType" SG_ 1369 VFCVectorBECMVFCid21 0;
BA_ "GenSigSendType" SG_ 1369 VFCVectorBECMVFCid22 0;
BA_ "GenSigSendType" SG_ 1369 VFCVectorBECMVFCid23 0;
BA_ "GenSigSendType" SG_ 1369 VFCVectorBECMVFCid24 0;
BA_ "GenSigSendType" SG_ 1369 VFCVectorBECMVFCid25 0;
BA_ "GenSigSendType" SG_ 1369 VFCVectorBECMVFCid26 0;
BA_ "GenSigSendType" SG_ 1369 VFCVectorBECMVFCid27 0;
BA_ "GenSigSendType" SG_ 1369 VFCVectorBECMVFCid28 0;
BA_ "GenSigSendType" SG_ 1369 VFCVectorBECMVFCid29 0;
BA_ "GenSigSendType" SG_ 1369 VFCVectorBECMVFCid3 0;
BA_ "GenSigSendType" SG_ 1369 VFCVectorBECMVFCid30 0;
BA_ "GenSigSendType" SG_ 1369 VFCVectorBECMVFCid31 0;
BA_ "GenSigSendType" SG_ 1369 VFCVectorBECMVFCid32 0;
BA_ "GenSigSendType" SG_ 1369 VFCVectorBECMVFCid33 0;
BA_ "GenSigSendType" SG_ 1369 VFCVectorBECMVFCid34 0;
BA_ "GenSigSendType" SG_ 1369 VFCVectorBECMVFCid35 0;
BA_ "GenSigSendType" SG_ 1369 VFCVectorBECMVFCid36 0;
BA_ "GenSigSendType" SG_ 1369 VFCVectorBECMVFCid37 0;
BA_ "GenSigSendType" SG_ 1369 VFCVectorBECMVFCid38 0;
BA_ "GenSigSendType" SG_ 1369 VFCVectorBECMVFCid39 0;
BA_ "GenSigSendType" SG_ 1369 VFCVectorBECMVFCid4 0;
BA_ "GenSigSendType" SG_ 1369 VFCVectorBECMVFCid40 0;
BA_ "GenSigSendType" SG_ 1369 VFCVectorBECMVFCid41 0;
BA_ "GenSigSendType" SG_ 1369 VFCVectorBECMVFCid42 0;
BA_ "GenSigSendType" SG_ 1369 VFCVectorBECMVFCid43 0;
BA_ "GenSigSendType" SG_ 1369 VFCVectorBECMVFCid44 0;
BA_ "GenSigSendType" SG_ 1369 VFCVectorBECMVFCid45 0;
BA_ "GenSigSendType" SG_ 1369 VFCVectorBECMVFCid46 0;
BA_ "GenSigSendType" SG_ 1369 VFCVectorBECMVFCid47 0;
BA_ "GenSigSendType" SG_ 1369 VFCVectorBECMVFCid48 0;
BA_ "GenSigSendType" SG_ 1369 VFCVectorBECMVFCid49 0;
BA_ "GenSigSendType" SG_ 1369 VFCVectorBECMVFCid5 0;
BA_ "GenSigSendType" SG_ 1369 VFCVectorBECMVFCid50 0;
BA_ "GenSigSendType" SG_ 1369 VFCVectorBECMVFCid51 0;
BA_ "GenSigSendType" SG_ 1369 VFCVectorBECMVFCid52 0;
BA_ "GenSigSendType" SG_ 1369 VFCVectorBECMVFCid53 0;
BA_ "GenSigSendType" SG_ 1369 VFCVectorBECMVFCid54 0;
BA_ "GenSigSendType" SG_ 1369 VFCVectorBECMVFCid55 0;
BA_ "GenSigSendType" SG_ 1369 VFCVectorBECMVFCid56 0;
BA_ "GenSigSendType" SG_ 1369 VFCVectorBECMVFCid57 0;
BA_ "GenSigSendType" SG_ 1369 VFCVectorBECMVFCid58 0;
BA_ "GenSigSendType" SG_ 1369 VFCVectorBECMVFCid59 0;
BA_ "GenSigSendType" SG_ 1369 VFCVectorBECMVFCid6 0;
BA_ "GenSigSendType" SG_ 1369 VFCVectorBECMVFCid60 0;
BA_ "GenSigSendType" SG_ 1369 VFCVectorBECMVFCid61 0;
BA_ "GenSigSendType" SG_ 1369 VFCVectorBECMVFCid7 0;
BA_ "GenSigSendType" SG_ 1369 VFCVectorBECMVFCid8 0;
BA_ "GenSigSendType" SG_ 1369 VFCVectorBECMVFCid9 0;
BA_ "GenSigSendType" SG_ 1391 VFCVectorCDDBlockID 0;
BA_ "GenSigSendType" SG_ 1391 VFCVectorCDDVFCid0 0;
BA_ "GenSigSendType" SG_ 1391 VFCVectorCDDVFCid1 0;
BA_ "GenSigSendType" SG_ 1391 VFCVectorCDDVFCid10 0;
BA_ "GenSigSendType" SG_ 1391 VFCVectorCDDVFCid11 0;
BA_ "GenSigSendType" SG_ 1391 VFCVectorCDDVFCid12 0;
BA_ "GenSigSendType" SG_ 1391 VFCVectorCDDVFCid13 0;
BA_ "GenSigSendType" SG_ 1391 VFCVectorCDDVFCid14 0;
BA_ "GenSigSendType" SG_ 1391 VFCVectorCDDVFCid15 0;
BA_ "GenSigSendType" SG_ 1391 VFCVectorCDDVFCid16 0;
BA_ "GenSigSendType" SG_ 1391 VFCVectorCDDVFCid17 0;
BA_ "GenSigSendType" SG_ 1391 VFCVectorCDDVFCid18 0;
BA_ "GenSigSendType" SG_ 1391 VFCVectorCDDVFCid19 0;
BA_ "GenSigSendType" SG_ 1391 VFCVectorCDDVFCid2 0;
BA_ "GenSigSendType" SG_ 1391 VFCVectorCDDVFCid20 0;
BA_ "GenSigSendType" SG_ 1391 VFCVectorCDDVFCid21 0;
BA_ "GenSigSendType" SG_ 1391 VFCVectorCDDVFCid22 0;
BA_ "GenSigSendType" SG_ 1391 VFCVectorCDDVFCid23 0;
BA_ "GenSigSendType" SG_ 1391 VFCVectorCDDVFCid24 0;
BA_ "GenSigSendType" SG_ 1391 VFCVectorCDDVFCid25 0;
BA_ "GenSigSendType" SG_ 1391 VFCVectorCDDVFCid26 0;
BA_ "GenSigSendType" SG_ 1391 VFCVectorCDDVFCid27 0;
BA_ "GenSigSendType" SG_ 1391 VFCVectorCDDVFCid28 0;
BA_ "GenSigSendType" SG_ 1391 VFCVectorCDDVFCid29 0;
BA_ "GenSigSendType" SG_ 1391 VFCVectorCDDVFCid3 0;
BA_ "GenSigSendType" SG_ 1391 VFCVectorCDDVFCid30 0;
BA_ "GenSigSendType" SG_ 1391 VFCVectorCDDVFCid31 0;
BA_ "GenSigSendType" SG_ 1391 VFCVectorCDDVFCid32 0;
BA_ "GenSigSendType" SG_ 1391 VFCVectorCDDVFCid33 0;
BA_ "GenSigSendType" SG_ 1391 VFCVectorCDDVFCid34 0;
BA_ "GenSigSendType" SG_ 1391 VFCVectorCDDVFCid35 0;
BA_ "GenSigSendType" SG_ 1391 VFCVectorCDDVFCid36 0;
BA_ "GenSigSendType" SG_ 1391 VFCVectorCDDVFCid37 0;
BA_ "GenSigSendType" SG_ 1391 VFCVectorCDDVFCid38 0;
BA_ "GenSigSendType" SG_ 1391 VFCVectorCDDVFCid39 0;
BA_ "GenSigSendType" SG_ 1391 VFCVectorCDDVFCid4 0;
BA_ "GenSigSendType" SG_ 1391 VFCVectorCDDVFCid40 0;
BA_ "GenSigSendType" SG_ 1391 VFCVectorCDDVFCid41 0;
BA_ "GenSigSendType" SG_ 1391 VFCVectorCDDVFCid42 0;
BA_ "GenSigSendType" SG_ 1391 VFCVectorCDDVFCid43 0;
BA_ "GenSigSendType" SG_ 1391 VFCVectorCDDVFCid44 0;
BA_ "GenSigSendType" SG_ 1391 VFCVectorCDDVFCid45 0;
BA_ "GenSigSendType" SG_ 1391 VFCVectorCDDVFCid46 0;
BA_ "GenSigSendType" SG_ 1391 VFCVectorCDDVFCid47 0;
BA_ "GenSigSendType" SG_ 1391 VFCVectorCDDVFCid48 0;
BA_ "GenSigSendType" SG_ 1391 VFCVectorCDDVFCid49 0;
BA_ "GenSigSendType" SG_ 1391 VFCVectorCDDVFCid5 0;
BA_ "GenSigSendType" SG_ 1391 VFCVectorCDDVFCid50 0;
BA_ "GenSigSendType" SG_ 1391 VFCVectorCDDVFCid51 0;
BA_ "GenSigSendType" SG_ 1391 VFCVectorCDDVFCid52 0;
BA_ "GenSigSendType" SG_ 1391 VFCVectorCDDVFCid53 0;
BA_ "GenSigSendType" SG_ 1391 VFCVectorCDDVFCid54 0;
BA_ "GenSigSendType" SG_ 1391 VFCVectorCDDVFCid55 0;
BA_ "GenSigSendType" SG_ 1391 VFCVectorCDDVFCid56 0;
BA_ "GenSigSendType" SG_ 1391 VFCVectorCDDVFCid57 0;
BA_ "GenSigSendType" SG_ 1391 VFCVectorCDDVFCid58 0;
BA_ "GenSigSendType" SG_ 1391 VFCVectorCDDVFCid59 0;
BA_ "GenSigSendType" SG_ 1391 VFCVectorCDDVFCid6 0;
BA_ "GenSigSendType" SG_ 1391 VFCVectorCDDVFCid60 0;
BA_ "GenSigSendType" SG_ 1391 VFCVectorCDDVFCid61 0;
BA_ "GenSigSendType" SG_ 1391 VFCVectorCDDVFCid7 0;
BA_ "GenSigSendType" SG_ 1391 VFCVectorCDDVFCid8 0;
BA_ "GenSigSendType" SG_ 1391 VFCVectorCDDVFCid9 0;
BA_ "GenSigSendType" SG_ 1327 WakeUpReasonsforCDD 0;
BA_ "GenSigSendType" SG_ 1281 WakeUpReasonsforDHU 0;
BA_ "GenSigSendType" SG_ 1305 WakeupReasonsforBECM 0;

VAL_ 321 HvSysActvnInhb 0 "OkNotOk1_Ok" 1 "OkNotOk1_NotOk";
VAL_ 321 HvSysPwrOff 0 "OkNotOk1_Ok" 1 "OkNotOk1_NotOk";
VAL_ 321 HvSysRlyStsHvSysRlySts 0 "HvActvnSts_Open" 1 "HvActvnSts_Clsd" 2 "HvActvnSts_KeepSt" 3 "HvActvnSts_OpenAndReqActvDcha";
VAL_ 321 HvSysSts 0 "HvSysSts_Inin" 1 "HvSysSts_Test" 2 "HvSysSts_Rdy";
VAL_ 373 MaintainBattTFb 0 "BookChrgnStsFb_Default" 1 "BookChrgnStsFb_Success" 2 "BookChrgnStsFb_Fail" 3 "BookChrgnStsFb_Finished";
VAL_ 376 HvBattChrgnCmpl 0 "NoYes1_No" 1 "NoYes1_Yes";
VAL_ 376 HvBattCoolgReq 0 "HvBattCoolgReq_NotReqd" 1 "HvBattCoolgReq_LoReq" 2 "HvBattCoolgReq_MedReq" 3 "HvBattCoolgReq_HiReq";
VAL_ 659 HvBattErrIndcnReq 0 "OnOff1_Off" 1 "OnOff1_On";
VAL_ 659 HvBattHeatgReq 0 "HvBattCoolgReq_NotReqd" 1 "HvBattCoolgReq_LoReq" 2 "HvBattCoolgReq_MedReq" 3 "HvBattCoolgReq_HiReq";
VAL_ 661 HvBattCoolgSts 0 "ClimaSts_Start" 1 "ClimaSts_Finish";
VAL_ 661 HVIL1Sts 0 "OpenClose_Open" 1 "OpenClose_Close";
VAL_ 661 HVIL2Sts 0 "OpenClose_Open" 1 "OpenClose_Close";
VAL_ 661 HVIL3Sts 0 "OpenClose_Open" 1 "OpenClose_Close";
VAL_ 661 HvIsoSts 0 "Insulation_Default" 1 "Insulation_Error_Battery_before_HV_Ready" 2 "Insulation_Error_HV_bus_after_HV_Ready" 3 "Insulation_OK";
VAL_ 661 HvSysCrashFb 0 "CrashFb_Idle" 1 "CrashFb_Evln" 2 "CrashFb_Nok" 3 "CrashFb_Ok";
VAL_ 662 FastChrgnLockCtrl 0 "OnOff1_Off" 1 "OnOff1_On";
VAL_ 662 HvBattHeatStopReqBrkLiOnReqSts 0 "ReqSts1_NotReqd" 1 "ReqSts1_Reqd";
VAL_ 834 HvBattMismatchFlt 0 "DevErrSts2_NoFlt" 1 "DevErrSts2_Flt";
VAL_ 834 HvCellTDifFlt 0 "FauLevel_Normal" 1 "FauLevel_LevelI" 2 "FauLevel_LevelII" 3 "FauLevel_LevelIII";
VAL_ 834 HvCellTOverFlt 0 "FauLevel_Normal" 1 "FauLevel_LevelI" 2 "FauLevel_LevelII" 3 "FauLevel_LevelIII";
VAL_ 834 HvCellUDifFlt 0 "FauLevel_Normal" 1 "FauLevel_LevelI" 2 "FauLevel_LevelII" 3 "FauLevel_LevelIII";
VAL_ 834 HvCellUOverFlt 0 "FauLevel_Normal" 1 "FauLevel_LevelI" 2 "FauLevel_LevelII" 3 "FauLevel_LevelIII";
VAL_ 834 HvCellUUnderFlt 0 "FauLevel_Normal" 1 "FauLevel_LevelI" 2 "FauLevel_LevelII" 3 "FauLevel_LevelIII";
VAL_ 834 HvilFlt 0 "DevErrSts2_NoFlt" 1 "DevErrSts2_Flt";
VAL_ 834 HvIsoFlt 0 "FauLevel_Normal" 1 "FauLevel_LevelI" 2 "FauLevel_LevelII" 3 "FauLevel_LevelIII";
VAL_ 834 HvPackOverChrgFlt 0 "FauLevel_Normal" 1 "FauLevel_LevelI" 2 "FauLevel_LevelII" 3 "FauLevel_LevelIII";
VAL_ 834 HvPackUOverFlt 0 "FauLevel_Normal" 1 "FauLevel_LevelI" 2 "FauLevel_LevelII" 3 "FauLevel_LevelIII";
VAL_ 834 HvPackUUnderFlt 0 "FauLevel_Normal" 1 "FauLevel_LevelI" 2 "FauLevel_LevelII" 3 "FauLevel_LevelIII";
VAL_ 834 HvSocHiFlt 0 "FauLevel_Normal" 1 "FauLevel_LevelI" 2 "FauLevel_LevelII" 3 "FauLevel_LevelIII";
VAL_ 834 HvSocHopFlt 0 "FauLevel_Normal" 1 "FauLevel_LevelI" 2 "FauLevel_LevelII" 3 "FauLevel_LevelIII";
VAL_ 834 HvSocLoFlt 0 "FauLevel_Normal" 1 "FauLevel_LevelI" 2 "FauLevel_LevelII" 3 "FauLevel_LevelIII";
VAL_ 789 HvBattChrgnSts 0 "ClimaSts_Start" 1 "ClimaSts_Finish";
VAL_ 817 HvBattBalFlg 0 "OnOff1_Off" 1 "OnOff1_On";
VAL_ 646 HvBattFullChrgCaution 0 "OnOff1_Off" 1 "OnOff1_On";
VAL_ 646 HvBattPreHeatFaild 0 "OnOff1_Off" 1 "OnOff1_On";
VAL_ 323 DCChrgnHndlSts 0 "OnBdChrgrHndlSts_Disconnected" 1 "OnBdChrgrHndlSts_ConnectedWithoutPower" 2 "OnBdChrgrHndlSts_PowerAvailableButNotActivated" 3 "OnBdChrgrHndlSts_ConnectedWithPower" 4 "OnBdChrgrHndlSts_Init" 5 "OnBdChrgrHndlSts_Fault";
VAL_ 323 HvBattPreChrgReq 0 "OnOff1_Off" 1 "OnOff1_On";
VAL_ 833 HvBattClrRdyReq 0 "OnOff1_Off" 1 "OnOff1_On";
VAL_ 837 HvBattPreHeatgReq 0 "PreHeatgReq_Default" 1 "PreHeatgReq_On" 2 "PreHeatgReq_Off" 3 "PreHeatgReq_Reserved";
VAL_ 837 HvBattThermMod 0 "HvBattThermMod_Idle" 1 "HvBattThermMod_ThermalBalancing" 2 "HvBattThermMod_PassiveHeating" 3 "HvBattThermMod_ActiveHeating" 4 "HvBattThermMod_PassiveCooling" 5 "HvBattThermMod_ActiveCooling" 6 "HvBattThermMod_CombinedCooling" 7 "HvBattThermMod_Reserved";
VAL_ 838 HvBattCooltLvl 0 "HvBattCooltLvl_Full" 1 "HvBattCooltLvl_Empty";
VAL_ 325 HvBattOverDchaFlg 0 "OnOff1_Off" 1 "OnOff1_On";
VAL_ 648 DCChrgSt 0 "DCChrgrSts_Idle" 1 "DCChrgrSts_Prestart" 2 "DCChrgrSts_Charging" 3 "DCChrgrSts_DCChrgnFltVehSide" 4 "DCChrgrSts_DCChrgnFltChrgrSideTempFlt" 5 "DCChrgrSts_DCChrgnFltChrgrSideConnectFlt" 6 "DCChrgrSts_DCChrgnFltChrgrSideOtherFlt" 7 "DCChrgrSts_DCChrgnFltChrgrSideEmgyFlt" 8 "DCChrgrSts_DCChrgnFltChrgrSideComFlt" 9 "DCChrgrSts_Bookcharging" 10 "DCChrgrSts_Shuntdown" 11 "DCChrgrSts_Heating" 12 "DCChrgrSts_Supercharging" 13 "DCChrgrSts_SuperchargingEnd";
VAL_ 648 FastChrgnLEDIndctn 0 "FastChrgnLEDIndctn_Default" 1 "FastChrgnLEDIndctn_Green1" 2 "FastChrgnLEDIndctn_Green2" 3 "FastChrgnLEDIndctn_Green3" 4 "FastChrgnLEDIndctn_Green4" 5 "FastChrgnLEDIndctn_Red" 6 "FastChrgnLEDIndctn_Green5" 7 "FastChrgnLEDIndctn_Reserved";
VAL_ 322 BookTrvlHeatgStsFb 0 "BookTrvlHeatgStsFb_Default" 1 "BookTrvlHeatgStsFb_Heating" 2 "BookTrvlHeatgStsFb_HeatFinished" 3 "BookTrvlHeatgStsFb_HeatTerminated" 4 "BookTrvlHeatgStsFb_Fault";
VAL_ 656 BookTrvlPreHeatgFb 0 "BookChargeSetResponse_Default" 1 "BookChargeSetResponse_Success" 2 "BookChargeSetResponse_Cancelled" 3 "BookChargeSetResponse_Fail";
VAL_ 407 BECMAFEComError 0 "YesNo2_No" 1 "YesNo2_Yes";
VAL_ 407 BECMBookTrvlHeatgReq 0 "PreHeatgReq1_Default" 1 "PreHeatgReq1_On" 2 "PreHeatgReq1_Off" 3 "PreHeatgReq1_PluginPreHeatingOn";
VAL_ 407 BECMCVSComFlt 0 "YesNo2_No" 1 "YesNo2_Yes";
VAL_ 407 BECMDCPreHeatgReq 0 "PreHeatgReq_Default" 1 "PreHeatgReq_On" 2 "PreHeatgReq_Off" 3 "PreHeatgReq_Reserved";
VAL_ 407 BECMIsoCheckCmd 0 "OnOff1_Off" 1 "OnOff1_On";
VAL_ 390 FIDChargerFault 0 "YesNo2_No" 1 "YesNo2_Yes";
VAL_ 390 FIDCRASHEVENT 0 "YesNo2_No" 1 "YesNo2_Yes";
VAL_ 390 FIDCVTNUNSTABLE 0 "YesNo2_No" 1 "YesNo2_Yes";
VAL_ 390 FIDDONOTCONNECT 0 "YesNo2_No" 1 "YesNo2_Yes";
VAL_ 390 FIDECMSINGALMISS 0 "YesNo2_No" 1 "YesNo2_Yes";
VAL_ 390 FIDHvBattFaultIndcr 0 "YesNo2_No" 1 "YesNo2_Yes";
VAL_ 390 FIDHvPwrOff 0 "YesNo2_No" 1 "YesNo2_Yes";
VAL_ 390 FIDHVSOONUNAVAIL 0 "YesNo2_No" 1 "YesNo2_Yes";
VAL_ 390 FIDInhibitNonbasicThrmReq 0 "YesNo2_No" 1 "YesNo2_Yes";
VAL_ 390 FIDINHIBITSELFTEST 0 "YesNo2_No" 1 "YesNo2_Yes";
VAL_ 390 FIDInhibitThermalRequest 0 "YesNo2_No" 1 "YesNo2_Yes";
VAL_ 390 FIDINSTANTDISCONNECTION 0 "YesNo2_No" 1 "YesNo2_Yes";
VAL_ 390 FIDLVFault 0 "YesNo2_No" 1 "YesNo2_Yes";
VAL_ 390 FIDMPMCURDATA 0 "YesNo2_No" 1 "YesNo2_Yes";
VAL_ 390 FIDMPMCVTNDATA 0 "YesNo2_No" 1 "YesNo2_Yes";
VAL_ 390 FIDNOBalance 0 "YesNo2_No" 1 "YesNo2_Yes";
VAL_ 390 FIDNOCHARGING 0 "YesNo2_No" 1 "YesNo2_Yes";
VAL_ 390 FIDNOCONNECTION 0 "YesNo2_No" 1 "YesNo2_Yes";
VAL_ 390 FIDNoDCCharging 0 "YesNo2_No" 1 "YesNo2_Yes";
VAL_ 390 FIDNoDischarging 0 "YesNo2_No" 1 "YesNo2_Yes";
VAL_ 390 FIDNORESTARTMESSAGE 0 "YesNo2_No" 1 "YesNo2_Yes";
VAL_ 390 FIDSevereDCChargerFault 0 "YesNo2_No" 1 "YesNo2_Yes";
VAL_ 390 FIDSTOPSAFELY 0 "YesNo2_No" 1 "YesNo2_Yes";
VAL_ 390 FIDSYSTEMISOLATIONTEST 0 "YesNo2_No" 1 "YesNo2_Yes";
VAL_ 390 FIDUDCMODE 0 "YesNo2_No" 1 "YesNo2_Yes";
VAL_ 338 BECMCloudInfoBattGndMosSwSts 0 "OpenClose_Open" 1 "OpenClose_Close";
VAL_ 338 BECMCloudInfoBattNegMosSwSts 0 "OpenClose_Open" 1 "OpenClose_Close";
VAL_ 338 BECMCloudInfoBattPosMosSwSts 0 "OpenClose_Open" 1 "OpenClose_Close";
VAL_ 348 BECMMoflgErrHVConn 0 "OnOff1_Off" 1 "OnOff1_On";
VAL_ 348 BECMMoflgFrzHVConn 0 "OnOff1_Off" 1 "OnOff1_On";
VAL_ 348 BECMMoflgFShOffOT 0 "OnOff1_Off" 1 "OnOff1_On";
VAL_ 348 BECMMoflgSShOffOT 0 "OnOff1_Off" 1 "OnOff1_On";
VAL_ 1305 WakeupReasonsforBECM 0 "WakeupReasons_667949" 1 "WakeupReasons_667950" 2 "WakeupReasons_169654" 3 "WakeupReasons_667951" 4 "WakeupReasons_168965" 5 "WakeupReasons_197643" 6 "WakeupReasons_264933" 7 "WakeupReasons_45654" 8 "WakeupReasons_22058" 9 "WakeupReasons_49446" 10 "WakeupReasons_22060" 11 "WakeupReasons_269740" 12 "WakeupReasons_269735" 13 "WakeupReasons_269739" 14 "WakeupReasons_658500" 15 "WakeupReasons_21901" 16 "WakeupReasons_45793" 17 "WakeupReasons_45794" 18 "WakeupReasons_22005" 19 "WakeupReasons_22013" 20 "WakeupReasons_22100" 21 "WakeupReasons_45659" 22 "WakeupReasons_45657" 23 "WakeupReasons_140084" 24 "WakeupReasons_21973" 25 "WakeupReasons_91253" 26 "WakeupReasons_88123" 27 "WakeupReasons_88125" 28 "WakeupReasons_321583" 29 "WakeupReasons_74188" 30 "WakeupReasons_667945" 31 "WakeupReasons_169655" 32 "WakeupReasons_667948" 33 "WakeupReasons_168966" 34 "WakeupReasons_170865" 35 "WakeupReasons_197642" 36 "WakeupReasons_264876" 37 "WakeupReasons_191050" 38 "WakeupReasons_182033" 39 "WakeupReasons_200937" 40 "WakeupReasons_170807" 41 "WakeupReasons_319139" 42 "WakeupReasons_100298" 43 "WakeupReasons_100275" 44 "WakeupReasons_100300" 45 "WakeupReasons_100278" 46 "WakeupReasons_100281" 47 "WakeupReasons_265333" 48 "WakeupReasons_108776" 49 "WakeupReasons_176921" 50 "WakeupReasons_197826" 51 "WakeupReasons_185670" 52 "WakeupReasons_161066" 53 "WakeupReasons_200156" 54 "WakeupReasons_225696" 55 "WakeupReasons_21997" 56 "WakeupReasons_45656" 57 "WakeupReasons_266860" 58 "WakeupReasons_169894" 59 "WakeupReasons_320282" 60 "WakeupReasons_319422" 61 "WakeupReasons_320277" 62 "WakeupReasons_355601" 63 "WakeupReasons_360904" 64 "WakeupReasons_361505" 65 "WakeupReasons_361509" 66 "WakeupReasons_645094" 67 "WakeupReasons_68676" 68 "WakeupReasons_360008" 69 "WakeupReasons_109382" 70 "WakeupReasons_119273" 71 "WakeupReasons_224065" 72 "WakeupReasons_68644" 73 "WakeupReasons_109364" 74 "WakeupReasons_68481" 75 "WakeupReasons_224061" 76 "WakeupReasons_360006" 77 "WakeupReasons_138997" 78 "WakeupReasons_634696" 79 "WakeupReasons_645810" 80 "WakeupReasons_297868" 81 "WakeupReasons_315364" 82 "WakeupReasons_109367" 83 "WakeupReasons_320126" 84 "WakeupReasons_109387" 85 "WakeupReasons_634710" 86 "WakeupReasons_338820" 87 "WakeupReasons_67182" 88 "WakeupReasons_152237" 89 "WakeupReasons_145707" 90 "WakeupReasons_199172" 91 "WakeupReasons_144897" 92 "WakeupReasons_186489" 93 "WakeupReasons_144970" 94 "WakeupReasons_152786" 95 "WakeupReasons_264932" 96 "WakeupReasons_264934" 97 "WakeupReasons_356190" 98 "WakeupReasons_145688" 99 "WakeupReasons_95444" 100 "WakeupReasons_169945" 101 "WakeupReasons_140678" 102 "WakeupReasons_222553" 103 "WakeupReasons_224831" 104 "WakeupReasons_201815" 105 "WakeupReasons_45864" 106 "WakeupReasons_659549" 107 "WakeupReasons_45866" 108 "WakeupReasons_45867" 109 "WakeupReasons_169884" 110 "WakeupReasons_264962" 111 "WakeupReasons_201348" 112 "WakeupReasons_320287" 113 "WakeupReasons_156412" 114 "WakeupReasons_133749" 115 "WakeupReasons_355409" 116 "WakeupReasons_636692" 117 "WakeupReasons_533044" 118 "WakeupReasons_106774" 119 "WakeupReasons_145311" 120 "WakeupReasons_145319" 121 "WakeupReasons_152774" 122 "WakeupReasons_145330" 123 "WakeupReasons_145388" 124 "WakeupReasons_145399" 125 "WakeupReasons_145362" 126 "WakeupReasons_145385" 127 "WakeupReasons_145373" 128 "WakeupReasons_145288" 129 "WakeupReasons_145419" 130 "WakeupReasons_145454" 131 "WakeupReasons_145462" 132 "WakeupReasons_269156" 133 "WakeupReasons_300427" 134 "WakeupReasons_220322" 135 "WakeupReasons_224617" 136 "WakeupReasons_224634" 137 "WakeupReasons_300682" 138 "WakeupReasons_264958" 139 "WakeupReasons_160597" 140 "WakeupReasons_160602" 141 "WakeupReasons_108841" 142 "WakeupReasons_265569" 143 "WakeupReasons_526429" 144 "WakeupReasons_514545" 145 "WakeupReasons_265232" 146 "WakeupReasons_644550" 147 "WakeupReasons_317616" 148 "WakeupReasons_354791" 149 "WakeupReasons_320631" 150 "WakeupReasons_337565" 151 "WakeupReasons_532007" 152 "WakeupReasons_514503" 153 "WakeupReasons_299117" 154 "WakeupReasons_340667" 155 "WakeupReasons_321845" 156 "WakeupReasons_179103" 157 "WakeupReasons_108810" 158 "WakeupReasons_322857" 159 "WakeupReasons_658603" 160 "WakeupReasons_197648" 161 "WakeupReasons_160596" 162 "WakeupReasons_361272" 163 "WakeupReasons_361279" 164 "WakeupReasons_265305" 165 "WakeupReasons_265328" 166 "WakeupReasons_265330" 167 "WakeupReasons_298808" 168 "WakeupReasons_515804" 169 "WakeupReasons_514502" 170 "WakeupReasons_645753" 171 "WakeupReasons_646109" 172 "WakeupReasons_299547" 173 "WakeupReasons_318342" 174 "WakeupReasons_360543" 175 "WakeupReasons_356549" 176 "WakeupReasons_198484" 177 "WakeupReasons_300681" 178 "WakeupReasons_359211" 179 "WakeupReasons_534077" 180 "WakeupReasons_525705" 181 "WakeupReasons_360299" 182 "WakeupReasons_526445" 183 "WakeupReasons_534145" 184 "WakeupReasons_192030" 185 "WakeupReasons_652361" 186 "WakeupReasons_355214" 187 "WakeupReasons_321317" 188 "WakeupReasons_359187" 189 "WakeupReasons_321057" 190 "WakeupReasons_321319" 191 "WakeupReasons_321323" 192 "WakeupReasons_321077" 193 "WakeupReasons_320895" 194 "WakeupReasons_655340" 195 "WakeupReasons_636556" 196 "WakeupReasons_108834" 197 "WakeupReasons_265937" 198 "WakeupReasons_533050" 199 "WakeupReasons_526426" 200 "WakeupReasons_264712" 201 "WakeupReasons_319401" 202 "WakeupReasons_643973" 203 "WakeupReasons_223715" 204 "WakeupReasons_199159" 205 "WakeupReasons_318382" 206 "WakeupReasons_226967" 207 "WakeupReasons_531743" 208 "WakeupReasons_360542" 209 "WakeupReasons_264726" 210 "WakeupReasons_535214" 211 "WakeupReasons_335068" 212 "WakeupReasons_316796" 213 "WakeupReasons_526438" 214 "WakeupReasons_198433" 215 "WakeupReasons_225961" 216 "WakeupReasons_197665" 217 "WakeupReasons_224550" 218 "WakeupReasons_667962" 219 "WakeupReasons_667953" 220 "WakeupReasons_110885" 221 "WakeupReasons_224552" 222 "WakeupReasons_224553" 223 "WakeupReasons_652546" 224 "WakeupReasons_331194" 225 "WakeupReasons_667820" 226 "WakeupReasons_659350" 227 "WakeupReasons_101706" 228 "WakeupReasons_101725" 229 "WakeupReasons_101728" 230 "WakeupReasons_101727" 231 "WakeupReasons_166267" 232 "WakeupReasons_156440" 233 "WakeupReasons_95949" 234 "WakeupReasons_112799" 235 "WakeupReasons_146470" 236 "WakeupReasons_176748" 237 "WakeupReasons_223920" 238 "WakeupReasons_668531" 239 "WakeupReasons_670087" 240 "WakeupReasons_668529" 241 "WakeupReasons_45858" 242 "WakeupReasons_315981" 243 "WakeupReasons_533370" 244 "WakeupReasons_533371" 245 "WakeupReasons_533372" 246 "WakeupReasons_241902" 247 "WakeupReasons_359559" 248 "WakeupReasons_516327" 249 "WakeupReasons_533872" 250 "WakeupReasons_45856" 251 "WakeupReasons_45853" 252 "WakeupReasons_45854" 253 "WakeupReasons_45852" 254 "WakeupReasons_45851" 255 "WakeupReasons_45850" 256 "WakeupReasons_45849" 257 "WakeupReasons_636801" 258 "WakeupReasons_109466" 259 "WakeupReasons_109467" 260 "WakeupReasons_670345" 261 "WakeupReasons_NMPDUReceived" 262 "WakeupReasons_358832" 263 "WakeupReasons_200683" 264 "WakeupReasons_198452" 265 "WakeupReasons_185457" 266 "WakeupReasons_185490" 267 "WakeupReasons_4471" 268 "WakeupReasons_269034" 269 "WakeupReasons_215560" 270 "WakeupReasons_312881" 271 "WakeupReasons_269140" 272 "WakeupReasons_197653" 273 "WakeupReasons_337991" 274 "WakeupReasons_658188" 275 "WakeupReasons_674953" 276 "WakeupReasons_675064" 277 "WakeupReasons_674958" 278 "WakeupReasons_675494" 279 "WakeupReasons_675837" 280 "WakeupReasons_667879" 281 "WakeupReasons_667947" 282 "WakeupReasons_676265" 283 "WakeupReasons_669465" 284 "WakeupReasons_670928" 285 "WakeupReasons_669447" 286 "WakeupReasons_667922" 287 "WakeupReasons_670753" 288 "WakeupReasons_668395" 289 "WakeupReasons_668393" 290 "WakeupReasons_667850" 291 "WakeupReasons_667848" 292 "WakeupReasons_311279" 293 "WakeupReasons_182918" 294 "WakeupReasons_667988" 295 "WakeupReasons_532555" 296 "WakeupReasons_532556" 297 "WakeupReasons_113348" 298 "WakeupReasons_193474" 299 "WakeupReasons_667871" 300 "WakeupReasons_670966" 301 "WakeupReasons_667985" 302 "WakeupReasons_670354" 303 "WakeupReasons_46017" 304 "WakeupReasons_675742" 305 "WakeupReasons_106669" 306 "WakeupReasons_80609" 307 "WakeupReasons_199714" 308 "WakeupReasons_200090" 309 "WakeupReasons_139075" 310 "WakeupReasons_268983" 311 "WakeupReasons_265131" 312 "WakeupReasons_263473" 313 "WakeupReasons_45887" 314 "WakeupReasons_69678" 315 "WakeupReasons_69679" 316 "WakeupReasons_45897" 317 "WakeupReasons_45898" 318 "WakeupReasons_80608" 319 "WakeupReasons_45869" 320 "WakeupReasons_45870" 321 "WakeupReasons_45872" 322 "WakeupReasons_45875" 323 "WakeupReasons_45871" 324 "WakeupReasons_45876" 325 "WakeupReasons_667980" 326 "WakeupReasons_45877" 327 "WakeupReasons_667973" 328 "WakeupReasons_670962" 329 "WakeupReasons_45888" 330 "WakeupReasons_45890" 331 "WakeupReasons_667869" 332 "WakeupReasons_45846" 333 "WakeupReasons_45847" 334 "WakeupReasons_45848" 335 "WakeupReasons_262872" 336 "WakeupReasons_127924" 337 "WakeupReasons_127926" 338 "WakeupReasons_674223" 339 "WakeupReasons_667982" 340 "WakeupReasons_657121" 341 "WakeupReasons_265745" 342 "WakeupReasons_657120" 343 "WakeupReasons_675564" 344 "WakeupReasons_197644" 345 "WakeupReasons_264943" 346 "WakeupReasons_264697" 347 "WakeupReasons_69216" 348 "WakeupReasons_128671" 349 "WakeupReasons_356598" 350 "WakeupReasons_675745" 351 "WakeupReasons_667983" 352 "WakeupReasons_667987" 353 "WakeupReasons_75103" 354 "WakeupReasons_305818" 355 "WakeupReasons_670942" 356 "WakeupReasons_532932" 357 "WakeupReasons_532933" 358 "WakeupReasons_83199" 359 "WakeupReasons_45900" 360 "WakeupReasons_88458" 361 "WakeupReasons_329457" 362 "WakeupReasons_45902" 363 "WakeupReasons_224211" 364 "WakeupReasons_667981" 365 "WakeupReasons_667874" 366 "WakeupReasons_46020" 367 "WakeupReasons_667842" 368 "WakeupReasons_145161" 369 "WakeupReasons_233755" 370 "WakeupReasons_297056" 371 "WakeupReasons_264691" 372 "WakeupReasons_262871" 373 "WakeupReasons_264964" 374 "WakeupReasons_667872" 375 "WakeupReasons_45655" 376 "WakeupReasons_177214" 377 "WakeupReasons_671005" 378 "WakeupReasons_680712" 379 "WakeupReasons_669822" 380 "WakeupReasons_668523" 381 "WakeupReasons_680974" 382 "WakeupReasons_680975" 383 "WakeupReasons_681028" 384 "WakeupReasons_670462" 385 "WakeupReasons_681134" 386 "WakeupReasons_681031" 387 "WakeupReasons_681711" 388 "WakeupReasons_682034" 389 "WakeupReasons_674839" 390 "WakeupReasons_681915" 391 "WakeupReasons_682032" 392 "WakeupReasons_682037" 393 "WakeupReasons_682688" 394 "WakeupReasons_681789" 395 "WakeupReasons_682023" 396 "WakeupReasons_681023" 397 "WakeupReasons_676285" 398 "WakeupReasons_682077" 399 "WakeupReasons_682076" 400 "WakeupReasons_682078" 401 "WakeupReasons_682153" 402 "WakeupReasons_682155" 403 "WakeupReasons_682152" 404 "WakeupReasons_682154" 405 "WakeupReasons_682074";
VAL_ 1369 VFCVectorBECMVFCid0 0 "VFCOnOff_Off" 1 "VFCOnOff_On";
VAL_ 1369 VFCVectorBECMVFCid1 0 "VFCOnOff_Off" 1 "VFCOnOff_On";
VAL_ 1369 VFCVectorBECMVFCid10 0 "VFCOnOff_Off" 1 "VFCOnOff_On";
VAL_ 1369 VFCVectorBECMVFCid11 0 "VFCOnOff_Off" 1 "VFCOnOff_On";
VAL_ 1369 VFCVectorBECMVFCid12 0 "VFCOnOff_Off" 1 "VFCOnOff_On";
VAL_ 1369 VFCVectorBECMVFCid13 0 "VFCOnOff_Off" 1 "VFCOnOff_On";
VAL_ 1369 VFCVectorBECMVFCid14 0 "VFCOnOff_Off" 1 "VFCOnOff_On";
VAL_ 1369 VFCVectorBECMVFCid15 0 "VFCOnOff_Off" 1 "VFCOnOff_On";
VAL_ 1369 VFCVectorBECMVFCid16 0 "VFCOnOff_Off" 1 "VFCOnOff_On";
VAL_ 1369 VFCVectorBECMVFCid17 0 "VFCOnOff_Off" 1 "VFCOnOff_On";
VAL_ 1369 VFCVectorBECMVFCid18 0 "VFCOnOff_Off" 1 "VFCOnOff_On";
VAL_ 1369 VFCVectorBECMVFCid19 0 "VFCOnOff_Off" 1 "VFCOnOff_On";
VAL_ 1369 VFCVectorBECMVFCid2 0 "VFCOnOff_Off" 1 "VFCOnOff_On";
VAL_ 1369 VFCVectorBECMVFCid20 0 "VFCOnOff_Off" 1 "VFCOnOff_On";
VAL_ 1369 VFCVectorBECMVFCid21 0 "VFCOnOff_Off" 1 "VFCOnOff_On";
VAL_ 1369 VFCVectorBECMVFCid22 0 "VFCOnOff_Off" 1 "VFCOnOff_On";
VAL_ 1369 VFCVectorBECMVFCid23 0 "VFCOnOff_Off" 1 "VFCOnOff_On";
VAL_ 1369 VFCVectorBECMVFCid24 0 "VFCOnOff_Off" 1 "VFCOnOff_On";
VAL_ 1369 VFCVectorBECMVFCid25 0 "VFCOnOff_Off" 1 "VFCOnOff_On";
VAL_ 1369 VFCVectorBECMVFCid26 0 "VFCOnOff_Off" 1 "VFCOnOff_On";
VAL_ 1369 VFCVectorBECMVFCid27 0 "VFCOnOff_Off" 1 "VFCOnOff_On";
VAL_ 1369 VFCVectorBECMVFCid28 0 "VFCOnOff_Off" 1 "VFCOnOff_On";
VAL_ 1369 VFCVectorBECMVFCid29 0 "VFCOnOff_Off" 1 "VFCOnOff_On";
VAL_ 1369 VFCVectorBECMVFCid3 0 "VFCOnOff_Off" 1 "VFCOnOff_On";
VAL_ 1369 VFCVectorBECMVFCid30 0 "VFCOnOff_Off" 1 "VFCOnOff_On";
VAL_ 1369 VFCVectorBECMVFCid31 0 "VFCOnOff_Off" 1 "VFCOnOff_On";
VAL_ 1369 VFCVectorBECMVFCid32 0 "VFCOnOff_Off" 1 "VFCOnOff_On";
VAL_ 1369 VFCVectorBECMVFCid33 0 "VFCOnOff_Off" 1 "VFCOnOff_On";
VAL_ 1369 VFCVectorBECMVFCid34 0 "VFCOnOff_Off" 1 "VFCOnOff_On";
VAL_ 1369 VFCVectorBECMVFCid35 0 "VFCOnOff_Off" 1 "VFCOnOff_On";
VAL_ 1369 VFCVectorBECMVFCid36 0 "VFCOnOff_Off" 1 "VFCOnOff_On";
VAL_ 1369 VFCVectorBECMVFCid37 0 "VFCOnOff_Off" 1 "VFCOnOff_On";
VAL_ 1369 VFCVectorBECMVFCid38 0 "VFCOnOff_Off" 1 "VFCOnOff_On";
VAL_ 1369 VFCVectorBECMVFCid39 0 "VFCOnOff_Off" 1 "VFCOnOff_On";
VAL_ 1369 VFCVectorBECMVFCid4 0 "VFCOnOff_Off" 1 "VFCOnOff_On";
VAL_ 1369 VFCVectorBECMVFCid40 0 "VFCOnOff_Off" 1 "VFCOnOff_On";
VAL_ 1369 VFCVectorBECMVFCid41 0 "VFCOnOff_Off" 1 "VFCOnOff_On";
VAL_ 1369 VFCVectorBECMVFCid42 0 "VFCOnOff_Off" 1 "VFCOnOff_On";
VAL_ 1369 VFCVectorBECMVFCid43 0 "VFCOnOff_Off" 1 "VFCOnOff_On";
VAL_ 1369 VFCVectorBECMVFCid44 0 "VFCOnOff_Off" 1 "VFCOnOff_On";
VAL_ 1369 VFCVectorBECMVFCid45 0 "VFCOnOff_Off" 1 "VFCOnOff_On";
VAL_ 1369 VFCVectorBECMVFCid46 0 "VFCOnOff_Off" 1 "VFCOnOff_On";
VAL_ 1369 VFCVectorBECMVFCid47 0 "VFCOnOff_Off" 1 "VFCOnOff_On";
VAL_ 1369 VFCVectorBECMVFCid48 0 "VFCOnOff_Off" 1 "VFCOnOff_On";
VAL_ 1369 VFCVectorBECMVFCid49 0 "VFCOnOff_Off" 1 "VFCOnOff_On";
VAL_ 1369 VFCVectorBECMVFCid5 0 "VFCOnOff_Off" 1 "VFCOnOff_On";
VAL_ 1369 VFCVectorBECMVFCid50 0 "VFCOnOff_Off" 1 "VFCOnOff_On";
VAL_ 1369 VFCVectorBECMVFCid51 0 "VFCOnOff_Off" 1 "VFCOnOff_On";
VAL_ 1369 VFCVectorBECMVFCid52 0 "VFCOnOff_Off" 1 "VFCOnOff_On";
VAL_ 1369 VFCVectorBECMVFCid53 0 "VFCOnOff_Off" 1 "VFCOnOff_On";
VAL_ 1369 VFCVectorBECMVFCid54 0 "VFCOnOff_Off" 1 "VFCOnOff_On";
VAL_ 1369 VFCVectorBECMVFCid55 0 "VFCOnOff_Off" 1 "VFCOnOff_On";
VAL_ 1369 VFCVectorBECMVFCid56 0 "VFCOnOff_Off" 1 "VFCOnOff_On";
VAL_ 1369 VFCVectorBECMVFCid57 0 "VFCOnOff_Off" 1 "VFCOnOff_On";
VAL_ 1369 VFCVectorBECMVFCid58 0 "VFCOnOff_Off" 1 "VFCOnOff_On";
VAL_ 1369 VFCVectorBECMVFCid59 0 "VFCOnOff_Off" 1 "VFCOnOff_On";
VAL_ 1369 VFCVectorBECMVFCid6 0 "VFCOnOff_Off" 1 "VFCOnOff_On";
VAL_ 1369 VFCVectorBECMVFCid60 0 "VFCOnOff_Off" 1 "VFCOnOff_On";
VAL_ 1369 VFCVectorBECMVFCid61 0 "VFCOnOff_Off" 1 "VFCOnOff_On";
VAL_ 1369 VFCVectorBECMVFCid7 0 "VFCOnOff_Off" 1 "VFCOnOff_On";
VAL_ 1369 VFCVectorBECMVFCid8 0 "VFCOnOff_Off" 1 "VFCOnOff_On";
VAL_ 1369 VFCVectorBECMVFCid9 0 "VFCOnOff_Off" 1 "VFCOnOff_On";
VAL_ 331 DcDcActvd 0 "DcDcActvd_NoConversionToLVSide" 1 "DcDcActvd_ConversionToLVSide";
VAL_ 331 DchrgnIntSckState 0 "ConnectionSts_Disconnect" 1 "ConnectionSts_Connect";
VAL_ 331 FltElecDcDc 0 "DevErrSts2_NoFlt" 1 "DevErrSts2_Flt";
VAL_ 331 FltTDcDc 0 "DevErrSts2_NoFlt" 1 "DevErrSts2_Flt";
VAL_ 329 DcDcCoolgReq 0 "HvCoolg1_NoRequestForMoreCoolantPower" 1 "HvCoolg1_IncreaseLevel1ForMoreCoolantPower" 2 "HvCoolg1_IncreaseLevel2ForMoreCoolantPower" 3 "HvCoolg1_MaxCoolingPower" 4 "HvCoolg1_NotDefined";
VAL_ 536 OnBdChrgrCoolgReq 0 "HvCoolg1_NoRequestForMoreCoolantPower" 1 "HvCoolg1_IncreaseLevel1ForMoreCoolantPower" 2 "HvCoolg1_IncreaseLevel2ForMoreCoolantPower" 3 "HvCoolg1_MaxCoolingPower" 4 "HvCoolg1_NotDefined";
VAL_ 536 OnBdChrgrErrIndcnReqOnBdChrgrErrIndcnReq 0 "OnOff1_Off" 1 "OnOff1_On";
VAL_ 536 OnBdChrgrHndlSts1 0 "OnBdChrgrHndlSts1_Disconnected" 1 "OnBdChrgrHndlSts1_ConnectedWithoutPower" 2 "OnBdChrgrHndlSts1_PowerAvailableButNotActivated" 3 "OnBdChrgrHndlSts1_ConnectedWithPower" 4 "OnBdChrgrHndlSts1_DischargeConnectwithoutpowerincar" 5 "OnBdChrgrHndlSts1_DischargeConnectwithoutpoweroutcar" 6 "OnBdChrgrHndlSts1_DischargeConnectwithpowerincar" 7 "OnBdChrgrHndlSts1_DischargeConnectwithpoweroutcar" 8 "OnBdChrgrHndlSts1_Init" 9 "OnBdChrgrHndlSts1_Fault" 10 "OnBdChrgrHndlSts1_NotCompleteConnnected" 11 "OnBdChrgrHndlSts1_Reserved0" 12 "OnBdChrgrHndlSts1_Reserved1" 13 "OnBdChrgrHndlSts1_Reserved2";
VAL_ 534 OnBdChrgrClrRdyReq 0 "OnOff1_Off" 1 "OnOff1_On";
VAL_ 534 OnBdChrgrSt 0 "ChrgrSts1_Idle" 1 "ChrgrSts1_PreStrt" 2 "ChrgrSts1_Chrgn" 3 "ChrgrSts1_Alrm" 4 "ChrgrSts1_Srv" 5 "ChrgrSts1_Diagc" 6 "ChrgrSts1_Boot" 7 "ChrgrSts1_Rstrt" 8 "ChrgrSts1_DisChrgn" 9 "ChrgrSts1_BookChrgn" 10 "ChrgrSts1_Shutdown" 11 "ChrgrSts1_Heating" 12 "ChrgrSts1_Cooling";
VAL_ 298 DischrgPwrExceedWarn 0 "Normalwarning_Normal" 1 "Normalwarning_Warning";
VAL_ 298 HndlLockgSts 0 "LockgSts_Unknown" 1 "LockgSts_Locked" 2 "LockgSts_Unlocked" 3 "LockgSts_Fault";
VAL_ 339 CDDActStsDcDcIntSts 0 "DcDcIntSts_Inn_DCDC_PowerOn" 1 "DcDcIntSts_Inn_DCDC_Init" 2 "DcDcIntSts_Inn_DCDC_Standby" 3 "DcDcIntSts_Inn_DCDC_Buck" 4 "DcDcIntSts_Inn_DCDC_Reserved" 5 "DcDcIntSts_Inn_DCDC_FltDCDC" 6 "DcDcIntSts_Inn_DCDC_Reserved1" 7 "DcDcIntSts_Inn_DCDC_Sleep";
VAL_ 339 CDDActStsDchaIntSts 0 "DchaIntSts_Inn_INV_PowerOn" 1 "DchaIntSts_Inn_INV_Init" 2 "DchaIntSts_Inn_INV_Standby" 3 "DchaIntSts_Inn_INV_V2V" 4 "DchaIntSts_Inn_INV_V2L" 5 "DchaIntSts_Inn_INV_FltV2V" 6 "DchaIntSts_Inn_INV_FltV2L" 7 "DchaIntSts_Inn_INV_Sleep" 8 "DchaIntSts_Inn_INV_IntDischrgr" 9 "DchaIntSts_Inn_INV_FltIntDischrgr" 10 "DchaIntSts_Inn_INV_IntDischrgrAndV2X";
VAL_ 339 CDDActStsOnBdIntSts 0 "OnBdIntSts_Inn_OBC_PowerOn" 1 "OnBdIntSts_Inn_OBC_Init" 2 "OnBdIntSts_Inn_OBC_Standby" 3 "OnBdIntSts_Inn_OBC_Charging" 4 "OnBdIntSts_Inn_OBC_Heating" 5 "OnBdIntSts_Inn_OBC_FltChrg" 6 "OnBdIntSts_Inn_OBC_FltHeat" 7 "OnBdIntSts_Inn_OBC_Sleep";
VAL_ 339 CDDActStsOnBdS2Sts 0 "OpenClose_Open" 1 "OpenClose_Close";
VAL_ 339 DcChrgRlyStsDCChrgRlyNegSts 0 "FastRlyPosSts_Unknown" 1 "FastRlyPosSts_Open" 2 "FastRlyPosSts_Close";
VAL_ 339 DcChrgRlyStsDCChrgRlyPosSts 0 "FastRlyPosSts_Unknown" 1 "FastRlyPosSts_Open" 2 "FastRlyPosSts_Close";
VAL_ 346 CDDChipRstRsnC1ChipRstRsn 0 "C1ChipRstRsn_Normal" 1 "C1ChipRstRsn_WatechDog_Reset" 2 "C1ChipRstRsn_EccReset" 3 "C1ChipRstRsn_SoftwareFaultReset" 4 "C1ChipRstRsn_Reserved1" 5 "C1ChipRstRsn_Reserved2" 6 "C1ChipRstRsn_Reserved3" 7 "C1ChipRstRsn_Reserved4";
VAL_ 346 CDDChipRstRsnC2ChipRstRsn 0 "C1ChipRstRsn_Normal" 1 "C1ChipRstRsn_WatechDog_Reset" 2 "C1ChipRstRsn_EccReset" 3 "C1ChipRstRsn_SoftwareFaultReset" 4 "C1ChipRstRsn_Reserved1" 5 "C1ChipRstRsn_Reserved2" 6 "C1ChipRstRsn_Reserved3" 7 "C1ChipRstRsn_Reserved4";
VAL_ 346 CDDChipRstRsnC3ChipRstRsn 0 "C1ChipRstRsn_Normal" 1 "C1ChipRstRsn_WatechDog_Reset" 2 "C1ChipRstRsn_EccReset" 3 "C1ChipRstRsn_SoftwareFaultReset" 4 "C1ChipRstRsn_Reserved1" 5 "C1ChipRstRsn_Reserved2" 6 "C1ChipRstRsn_Reserved3" 7 "C1ChipRstRsn_Reserved4";
VAL_ 346 CDDLEDCtrlLEDBluCtrl 0 "OnOff1_Off" 1 "OnOff1_On";
VAL_ 346 CDDLEDCtrlLEDGrenCtrl 0 "OnOff1_Off" 1 "OnOff1_On";
VAL_ 346 CDDLEDCtrlLEDRedCtrl 0 "OnOff1_Off" 1 "OnOff1_On";
VAL_ 360 CDDLockdUnlckdTypElockLockdTyp 0 "ElockLockdTyp_Default" 1 "ElockLockdTyp_Plug_3s_locked" 2 "ElockLockdTyp_Unlocked_90s_Connected_relock" 3 "ElockLockdTyp_CentralControlLock" 4 "ElockLockdTyp_DCChargingLocked" 5 "ElockLockdTyp_AwakenedForTheFirstTimeLocked" 6 "ElockLockdTyp_ChargeRequestLock" 7 "ElockLockdTyp_LockInWorkingState";
VAL_ 360 CDDLockdUnlckdTypElockUnlckdTyp 0 "ElockUnlckdTyp_Default" 1 "ElockUnlckdTyp_NormalUnlock" 2 "ElockUnlckdTyp_UnlockDuringDCCharging";
VAL_ 360 CDDSnsrStsAcISnsrSts 0 "Flt_NoFault" 1 "Flt_Fault";
VAL_ 360 CDDSnsrStsAcUSnsrSts 0 "Flt_NoFault" 1 "Flt_Fault";
VAL_ 360 CDDSnsrStsHvISnsrSts 0 "Flt_NoFault" 1 "Flt_Fault";
VAL_ 360 CDDSnsrStsHvUSnsrSts 0 "Flt_NoFault" 1 "Flt_Fault";
VAL_ 360 CDDSnsrStsLvISnsrSts 0 "Flt_NoFault" 1 "Flt_Fault";
VAL_ 360 CDDSnsrStsPfcISnsrSts 0 "Flt_NoFault" 1 "Flt_Fault";
VAL_ 360 CDDSnsrStsPfcUSnsrSts 0 "Flt_NoFault" 1 "Flt_Fault";
VAL_ 360 ElecVehCAN 0 "ElecVehCAN_NoElectricVehicleInlet" 1 "ElecVehCAN_CCSType1" 2 "ElecVehCAN_CCSType2" 3 "ElecVehCAN_GBT_ACandDC" 4 "ElecVehCAN_CHAdeMOAndType1AC" 5 "ElecVehCAN_Reserved1" 6 "ElecVehCAN_Reserved2" 7 "ElecVehCAN_Reserved3";
VAL_ 1327 WakeUpReasonsforCDD 0 "WakeupReasons_667949" 1 "WakeupReasons_667950" 2 "WakeupReasons_169654" 3 "WakeupReasons_667951" 4 "WakeupReasons_168965" 5 "WakeupReasons_197643" 6 "WakeupReasons_264933" 7 "WakeupReasons_45654" 8 "WakeupReasons_22058" 9 "WakeupReasons_49446" 10 "WakeupReasons_22060" 11 "WakeupReasons_269740" 12 "WakeupReasons_269735" 13 "WakeupReasons_269739" 14 "WakeupReasons_658500" 15 "WakeupReasons_21901" 16 "WakeupReasons_45793" 17 "WakeupReasons_45794" 18 "WakeupReasons_22005" 19 "WakeupReasons_22013" 20 "WakeupReasons_22100" 21 "WakeupReasons_45659" 22 "WakeupReasons_45657" 23 "WakeupReasons_140084" 24 "WakeupReasons_21973" 25 "WakeupReasons_91253" 26 "WakeupReasons_88123" 27 "WakeupReasons_88125" 28 "WakeupReasons_321583" 29 "WakeupReasons_74188" 30 "WakeupReasons_667945" 31 "WakeupReasons_169655" 32 "WakeupReasons_667948" 33 "WakeupReasons_168966" 34 "WakeupReasons_170865" 35 "WakeupReasons_197642" 36 "WakeupReasons_264876" 37 "WakeupReasons_191050" 38 "WakeupReasons_182033" 39 "WakeupReasons_200937" 40 "WakeupReasons_170807" 41 "WakeupReasons_319139" 42 "WakeupReasons_100298" 43 "WakeupReasons_100275" 44 "WakeupReasons_100300" 45 "WakeupReasons_100278" 46 "WakeupReasons_100281" 47 "WakeupReasons_265333" 48 "WakeupReasons_108776" 49 "WakeupReasons_176921" 50 "WakeupReasons_197826" 51 "WakeupReasons_185670" 52 "WakeupReasons_161066" 53 "WakeupReasons_200156" 54 "WakeupReasons_225696" 55 "WakeupReasons_21997" 56 "WakeupReasons_45656" 57 "WakeupReasons_266860" 58 "WakeupReasons_169894" 59 "WakeupReasons_320282" 60 "WakeupReasons_319422" 61 "WakeupReasons_320277" 62 "WakeupReasons_355601" 63 "WakeupReasons_360904" 64 "WakeupReasons_361505" 65 "WakeupReasons_361509" 66 "WakeupReasons_645094" 67 "WakeupReasons_68676" 68 "WakeupReasons_360008" 69 "WakeupReasons_109382" 70 "WakeupReasons_119273" 71 "WakeupReasons_224065" 72 "WakeupReasons_68644" 73 "WakeupReasons_109364" 74 "WakeupReasons_68481" 75 "WakeupReasons_224061" 76 "WakeupReasons_360006" 77 "WakeupReasons_138997" 78 "WakeupReasons_634696" 79 "WakeupReasons_645810" 80 "WakeupReasons_297868" 81 "WakeupReasons_315364" 82 "WakeupReasons_109367" 83 "WakeupReasons_320126" 84 "WakeupReasons_109387" 85 "WakeupReasons_634710" 86 "WakeupReasons_338820" 87 "WakeupReasons_67182" 88 "WakeupReasons_152237" 89 "WakeupReasons_145707" 90 "WakeupReasons_199172" 91 "WakeupReasons_144897" 92 "WakeupReasons_186489" 93 "WakeupReasons_144970" 94 "WakeupReasons_152786" 95 "WakeupReasons_264932" 96 "WakeupReasons_264934" 97 "WakeupReasons_356190" 98 "WakeupReasons_145688" 99 "WakeupReasons_95444" 100 "WakeupReasons_169945" 101 "WakeupReasons_140678" 102 "WakeupReasons_222553" 103 "WakeupReasons_224831" 104 "WakeupReasons_201815" 105 "WakeupReasons_45864" 106 "WakeupReasons_659549" 107 "WakeupReasons_45866" 108 "WakeupReasons_45867" 109 "WakeupReasons_169884" 110 "WakeupReasons_264962" 111 "WakeupReasons_201348" 112 "WakeupReasons_320287" 113 "WakeupReasons_156412" 114 "WakeupReasons_133749" 115 "WakeupReasons_355409" 116 "WakeupReasons_636692" 117 "WakeupReasons_533044" 118 "WakeupReasons_106774" 119 "WakeupReasons_145311" 120 "WakeupReasons_145319" 121 "WakeupReasons_152774" 122 "WakeupReasons_145330" 123 "WakeupReasons_145388" 124 "WakeupReasons_145399" 125 "WakeupReasons_145362" 126 "WakeupReasons_145385" 127 "WakeupReasons_145373" 128 "WakeupReasons_145288" 129 "WakeupReasons_145419" 130 "WakeupReasons_145454" 131 "WakeupReasons_145462" 132 "WakeupReasons_269156" 133 "WakeupReasons_300427" 134 "WakeupReasons_220322" 135 "WakeupReasons_224617" 136 "WakeupReasons_224634" 137 "WakeupReasons_300682" 138 "WakeupReasons_264958" 139 "WakeupReasons_160597" 140 "WakeupReasons_160602" 141 "WakeupReasons_108841" 142 "WakeupReasons_265569" 143 "WakeupReasons_526429" 144 "WakeupReasons_514545" 145 "WakeupReasons_265232" 146 "WakeupReasons_644550" 147 "WakeupReasons_317616" 148 "WakeupReasons_354791" 149 "WakeupReasons_320631" 150 "WakeupReasons_337565" 151 "WakeupReasons_532007" 152 "WakeupReasons_514503" 153 "WakeupReasons_299117" 154 "WakeupReasons_340667" 155 "WakeupReasons_321845" 156 "WakeupReasons_179103" 157 "WakeupReasons_108810" 158 "WakeupReasons_322857" 159 "WakeupReasons_658603" 160 "WakeupReasons_197648" 161 "WakeupReasons_160596" 162 "WakeupReasons_361272" 163 "WakeupReasons_361279" 164 "WakeupReasons_265305" 165 "WakeupReasons_265328" 166 "WakeupReasons_265330" 167 "WakeupReasons_298808" 168 "WakeupReasons_515804" 169 "WakeupReasons_514502" 170 "WakeupReasons_645753" 171 "WakeupReasons_646109" 172 "WakeupReasons_299547" 173 "WakeupReasons_318342" 174 "WakeupReasons_360543" 175 "WakeupReasons_356549" 176 "WakeupReasons_198484" 177 "WakeupReasons_300681" 178 "WakeupReasons_359211" 179 "WakeupReasons_534077" 180 "WakeupReasons_525705" 181 "WakeupReasons_360299" 182 "WakeupReasons_526445" 183 "WakeupReasons_534145" 184 "WakeupReasons_192030" 185 "WakeupReasons_652361" 186 "WakeupReasons_355214" 187 "WakeupReasons_321317" 188 "WakeupReasons_359187" 189 "WakeupReasons_321057" 190 "WakeupReasons_321319" 191 "WakeupReasons_321323" 192 "WakeupReasons_321077" 193 "WakeupReasons_320895" 194 "WakeupReasons_655340" 195 "WakeupReasons_636556" 196 "WakeupReasons_108834" 197 "WakeupReasons_265937" 198 "WakeupReasons_533050" 199 "WakeupReasons_526426" 200 "WakeupReasons_264712" 201 "WakeupReasons_319401" 202 "WakeupReasons_643973" 203 "WakeupReasons_223715" 204 "WakeupReasons_199159" 205 "WakeupReasons_318382" 206 "WakeupReasons_226967" 207 "WakeupReasons_531743" 208 "WakeupReasons_360542" 209 "WakeupReasons_264726" 210 "WakeupReasons_535214" 211 "WakeupReasons_335068" 212 "WakeupReasons_316796" 213 "WakeupReasons_526438" 214 "WakeupReasons_198433" 215 "WakeupReasons_225961" 216 "WakeupReasons_197665" 217 "WakeupReasons_224550" 218 "WakeupReasons_667962" 219 "WakeupReasons_667953" 220 "WakeupReasons_110885" 221 "WakeupReasons_224552" 222 "WakeupReasons_224553" 223 "WakeupReasons_652546" 224 "WakeupReasons_331194" 225 "WakeupReasons_667820" 226 "WakeupReasons_659350" 227 "WakeupReasons_101706" 228 "WakeupReasons_101725" 229 "WakeupReasons_101728" 230 "WakeupReasons_101727" 231 "WakeupReasons_166267" 232 "WakeupReasons_156440" 233 "WakeupReasons_95949" 234 "WakeupReasons_112799" 235 "WakeupReasons_146470" 236 "WakeupReasons_176748" 237 "WakeupReasons_223920" 238 "WakeupReasons_668531" 239 "WakeupReasons_670087" 240 "WakeupReasons_668529" 241 "WakeupReasons_45858" 242 "WakeupReasons_315981" 243 "WakeupReasons_533370" 244 "WakeupReasons_533371" 245 "WakeupReasons_533372" 246 "WakeupReasons_241902" 247 "WakeupReasons_359559" 248 "WakeupReasons_516327" 249 "WakeupReasons_533872" 250 "WakeupReasons_45856" 251 "WakeupReasons_45853" 252 "WakeupReasons_45854" 253 "WakeupReasons_45852" 254 "WakeupReasons_45851" 255 "WakeupReasons_45850" 256 "WakeupReasons_45849" 257 "WakeupReasons_636801" 258 "WakeupReasons_109466" 259 "WakeupReasons_109467" 260 "WakeupReasons_670345" 261 "WakeupReasons_NMPDUReceived" 262 "WakeupReasons_358832" 263 "WakeupReasons_200683" 264 "WakeupReasons_198452" 265 "WakeupReasons_185457" 266 "WakeupReasons_185490" 267 "WakeupReasons_4471" 268 "WakeupReasons_269034" 269 "WakeupReasons_215560" 270 "WakeupReasons_312881" 271 "WakeupReasons_269140" 272 "WakeupReasons_197653" 273 "WakeupReasons_337991" 274 "WakeupReasons_658188" 275 "WakeupReasons_674953" 276 "WakeupReasons_675064" 277 "WakeupReasons_674958" 278 "WakeupReasons_675494" 279 "WakeupReasons_675837" 280 "WakeupReasons_667879" 281 "WakeupReasons_667947" 282 "WakeupReasons_676265" 283 "WakeupReasons_669465" 284 "WakeupReasons_670928" 285 "WakeupReasons_669447" 286 "WakeupReasons_667922" 287 "WakeupReasons_670753" 288 "WakeupReasons_668395" 289 "WakeupReasons_668393" 290 "WakeupReasons_667850" 291 "WakeupReasons_667848" 292 "WakeupReasons_311279" 293 "WakeupReasons_182918" 294 "WakeupReasons_667988" 295 "WakeupReasons_532555" 296 "WakeupReasons_532556" 297 "WakeupReasons_113348" 298 "WakeupReasons_193474" 299 "WakeupReasons_667871" 300 "WakeupReasons_670966" 301 "WakeupReasons_667985" 302 "WakeupReasons_670354" 303 "WakeupReasons_46017" 304 "WakeupReasons_675742" 305 "WakeupReasons_106669" 306 "WakeupReasons_80609" 307 "WakeupReasons_199714" 308 "WakeupReasons_200090" 309 "WakeupReasons_139075" 310 "WakeupReasons_268983" 311 "WakeupReasons_265131" 312 "WakeupReasons_263473" 313 "WakeupReasons_45887" 314 "WakeupReasons_69678" 315 "WakeupReasons_69679" 316 "WakeupReasons_45897" 317 "WakeupReasons_45898" 318 "WakeupReasons_80608" 319 "WakeupReasons_45869" 320 "WakeupReasons_45870" 321 "WakeupReasons_45872" 322 "WakeupReasons_45875" 323 "WakeupReasons_45871" 324 "WakeupReasons_45876" 325 "WakeupReasons_667980" 326 "WakeupReasons_45877" 327 "WakeupReasons_667973" 328 "WakeupReasons_670962" 329 "WakeupReasons_45888" 330 "WakeupReasons_45890" 331 "WakeupReasons_667869" 332 "WakeupReasons_45846" 333 "WakeupReasons_45847" 334 "WakeupReasons_45848" 335 "WakeupReasons_262872" 336 "WakeupReasons_127924" 337 "WakeupReasons_127926" 338 "WakeupReasons_674223" 339 "WakeupReasons_667982" 340 "WakeupReasons_657121" 341 "WakeupReasons_265745" 342 "WakeupReasons_657120" 343 "WakeupReasons_675564" 344 "WakeupReasons_197644" 345 "WakeupReasons_264943" 346 "WakeupReasons_264697" 347 "WakeupReasons_69216" 348 "WakeupReasons_128671" 349 "WakeupReasons_356598" 350 "WakeupReasons_675745" 351 "WakeupReasons_667983" 352 "WakeupReasons_667987" 353 "WakeupReasons_75103" 354 "WakeupReasons_305818" 355 "WakeupReasons_670942" 356 "WakeupReasons_532932" 357 "WakeupReasons_532933" 358 "WakeupReasons_83199" 359 "WakeupReasons_45900" 360 "WakeupReasons_88458" 361 "WakeupReasons_329457" 362 "WakeupReasons_45902" 363 "WakeupReasons_224211" 364 "WakeupReasons_667981" 365 "WakeupReasons_667874" 366 "WakeupReasons_46020" 367 "WakeupReasons_667842" 368 "WakeupReasons_145161" 369 "WakeupReasons_233755" 370 "WakeupReasons_297056" 371 "WakeupReasons_264691" 372 "WakeupReasons_262871" 373 "WakeupReasons_264964" 374 "WakeupReasons_667872" 375 "WakeupReasons_45655" 376 "WakeupReasons_177214" 377 "WakeupReasons_671005" 378 "WakeupReasons_680712" 379 "WakeupReasons_669822" 380 "WakeupReasons_668523" 381 "WakeupReasons_680974" 382 "WakeupReasons_680975" 383 "WakeupReasons_681028" 384 "WakeupReasons_670462" 385 "WakeupReasons_681134" 386 "WakeupReasons_681031" 387 "WakeupReasons_681711" 388 "WakeupReasons_682034" 389 "WakeupReasons_674839" 390 "WakeupReasons_681915" 391 "WakeupReasons_682032" 392 "WakeupReasons_682037" 393 "WakeupReasons_682688" 394 "WakeupReasons_681789" 395 "WakeupReasons_682023" 396 "WakeupReasons_681023" 397 "WakeupReasons_676285" 398 "WakeupReasons_682077" 399 "WakeupReasons_682076" 400 "WakeupReasons_682078" 401 "WakeupReasons_682153" 402 "WakeupReasons_682155" 403 "WakeupReasons_682152" 404 "WakeupReasons_682154" 405 "WakeupReasons_682074";
VAL_ 1391 VFCVectorCDDVFCid0 0 "VFCOnOff_Off" 1 "VFCOnOff_On";
VAL_ 1391 VFCVectorCDDVFCid1 0 "VFCOnOff_Off" 1 "VFCOnOff_On";
VAL_ 1391 VFCVectorCDDVFCid10 0 "VFCOnOff_Off" 1 "VFCOnOff_On";
VAL_ 1391 VFCVectorCDDVFCid11 0 "VFCOnOff_Off" 1 "VFCOnOff_On";
VAL_ 1391 VFCVectorCDDVFCid12 0 "VFCOnOff_Off" 1 "VFCOnOff_On";
VAL_ 1391 VFCVectorCDDVFCid13 0 "VFCOnOff_Off" 1 "VFCOnOff_On";
VAL_ 1391 VFCVectorCDDVFCid14 0 "VFCOnOff_Off" 1 "VFCOnOff_On";
VAL_ 1391 VFCVectorCDDVFCid15 0 "VFCOnOff_Off" 1 "VFCOnOff_On";
VAL_ 1391 VFCVectorCDDVFCid16 0 "VFCOnOff_Off" 1 "VFCOnOff_On";
VAL_ 1391 VFCVectorCDDVFCid17 0 "VFCOnOff_Off" 1 "VFCOnOff_On";
VAL_ 1391 VFCVectorCDDVFCid18 0 "VFCOnOff_Off" 1 "VFCOnOff_On";
VAL_ 1391 VFCVectorCDDVFCid19 0 "VFCOnOff_Off" 1 "VFCOnOff_On";
VAL_ 1391 VFCVectorCDDVFCid2 0 "VFCOnOff_Off" 1 "VFCOnOff_On";
VAL_ 1391 VFCVectorCDDVFCid20 0 "VFCOnOff_Off" 1 "VFCOnOff_On";
VAL_ 1391 VFCVectorCDDVFCid21 0 "VFCOnOff_Off" 1 "VFCOnOff_On";
VAL_ 1391 VFCVectorCDDVFCid22 0 "VFCOnOff_Off" 1 "VFCOnOff_On";
VAL_ 1391 VFCVectorCDDVFCid23 0 "VFCOnOff_Off" 1 "VFCOnOff_On";
VAL_ 1391 VFCVectorCDDVFCid24 0 "VFCOnOff_Off" 1 "VFCOnOff_On";
VAL_ 1391 VFCVectorCDDVFCid25 0 "VFCOnOff_Off" 1 "VFCOnOff_On";
VAL_ 1391 VFCVectorCDDVFCid26 0 "VFCOnOff_Off" 1 "VFCOnOff_On";
VAL_ 1391 VFCVectorCDDVFCid27 0 "VFCOnOff_Off" 1 "VFCOnOff_On";
VAL_ 1391 VFCVectorCDDVFCid28 0 "VFCOnOff_Off" 1 "VFCOnOff_On";
VAL_ 1391 VFCVectorCDDVFCid29 0 "VFCOnOff_Off" 1 "VFCOnOff_On";
VAL_ 1391 VFCVectorCDDVFCid3 0 "VFCOnOff_Off" 1 "VFCOnOff_On";
VAL_ 1391 VFCVectorCDDVFCid30 0 "VFCOnOff_Off" 1 "VFCOnOff_On";
VAL_ 1391 VFCVectorCDDVFCid31 0 "VFCOnOff_Off" 1 "VFCOnOff_On";
VAL_ 1391 VFCVectorCDDVFCid32 0 "VFCOnOff_Off" 1 "VFCOnOff_On";
VAL_ 1391 VFCVectorCDDVFCid33 0 "VFCOnOff_Off" 1 "VFCOnOff_On";
VAL_ 1391 VFCVectorCDDVFCid34 0 "VFCOnOff_Off" 1 "VFCOnOff_On";
VAL_ 1391 VFCVectorCDDVFCid35 0 "VFCOnOff_Off" 1 "VFCOnOff_On";
VAL_ 1391 VFCVectorCDDVFCid36 0 "VFCOnOff_Off" 1 "VFCOnOff_On";
VAL_ 1391 VFCVectorCDDVFCid37 0 "VFCOnOff_Off" 1 "VFCOnOff_On";
VAL_ 1391 VFCVectorCDDVFCid38 0 "VFCOnOff_Off" 1 "VFCOnOff_On";
VAL_ 1391 VFCVectorCDDVFCid39 0 "VFCOnOff_Off" 1 "VFCOnOff_On";
VAL_ 1391 VFCVectorCDDVFCid4 0 "VFCOnOff_Off" 1 "VFCOnOff_On";
VAL_ 1391 VFCVectorCDDVFCid40 0 "VFCOnOff_Off" 1 "VFCOnOff_On";
VAL_ 1391 VFCVectorCDDVFCid41 0 "VFCOnOff_Off" 1 "VFCOnOff_On";
VAL_ 1391 VFCVectorCDDVFCid42 0 "VFCOnOff_Off" 1 "VFCOnOff_On";
VAL_ 1391 VFCVectorCDDVFCid43 0 "VFCOnOff_Off" 1 "VFCOnOff_On";
VAL_ 1391 VFCVectorCDDVFCid44 0 "VFCOnOff_Off" 1 "VFCOnOff_On";
VAL_ 1391 VFCVectorCDDVFCid45 0 "VFCOnOff_Off" 1 "VFCOnOff_On";
VAL_ 1391 VFCVectorCDDVFCid46 0 "VFCOnOff_Off" 1 "VFCOnOff_On";
VAL_ 1391 VFCVectorCDDVFCid47 0 "VFCOnOff_Off" 1 "VFCOnOff_On";
VAL_ 1391 VFCVectorCDDVFCid48 0 "VFCOnOff_Off" 1 "VFCOnOff_On";
VAL_ 1391 VFCVectorCDDVFCid49 0 "VFCOnOff_Off" 1 "VFCOnOff_On";
VAL_ 1391 VFCVectorCDDVFCid5 0 "VFCOnOff_Off" 1 "VFCOnOff_On";
VAL_ 1391 VFCVectorCDDVFCid50 0 "VFCOnOff_Off" 1 "VFCOnOff_On";
VAL_ 1391 VFCVectorCDDVFCid51 0 "VFCOnOff_Off" 1 "VFCOnOff_On";
VAL_ 1391 VFCVectorCDDVFCid52 0 "VFCOnOff_Off" 1 "VFCOnOff_On";
VAL_ 1391 VFCVectorCDDVFCid53 0 "VFCOnOff_Off" 1 "VFCOnOff_On";
VAL_ 1391 VFCVectorCDDVFCid54 0 "VFCOnOff_Off" 1 "VFCOnOff_On";
VAL_ 1391 VFCVectorCDDVFCid55 0 "VFCOnOff_Off" 1 "VFCOnOff_On";
VAL_ 1391 VFCVectorCDDVFCid56 0 "VFCOnOff_Off" 1 "VFCOnOff_On";
VAL_ 1391 VFCVectorCDDVFCid57 0 "VFCOnOff_Off" 1 "VFCOnOff_On";
VAL_ 1391 VFCVectorCDDVFCid58 0 "VFCOnOff_Off" 1 "VFCOnOff_On";
VAL_ 1391 VFCVectorCDDVFCid59 0 "VFCOnOff_Off" 1 "VFCOnOff_On";
VAL_ 1391 VFCVectorCDDVFCid6 0 "VFCOnOff_Off" 1 "VFCOnOff_On";
VAL_ 1391 VFCVectorCDDVFCid60 0 "VFCOnOff_Off" 1 "VFCOnOff_On";
VAL_ 1391 VFCVectorCDDVFCid61 0 "VFCOnOff_Off" 1 "VFCOnOff_On";
VAL_ 1391 VFCVectorCDDVFCid7 0 "VFCOnOff_Off" 1 "VFCOnOff_On";
VAL_ 1391 VFCVectorCDDVFCid8 0 "VFCOnOff_Off" 1 "VFCOnOff_On";
VAL_ 1391 VFCVectorCDDVFCid9 0 "VFCOnOff_Off" 1 "VFCOnOff_On";
VAL_ 275 SmtThermMngtStsFromCloud 0 "SmtThermMngtSts_Init" 1 "SmtThermMngtSts_StandBy" 2 "SmtThermMngtSts_ServiceRequest" 3 "SmtThermMngtSts_Working" 4 "SmtThermMngtSts_TemporaryExit" 5 "SmtThermMngtSts_Fault";
VAL_ 1281 WakeUpReasonsforDHU 0 "WakeupReasons_667949" 1 "WakeupReasons_667950" 2 "WakeupReasons_169654" 3 "WakeupReasons_667951" 4 "WakeupReasons_168965" 5 "WakeupReasons_197643" 6 "WakeupReasons_264933" 7 "WakeupReasons_45654" 8 "WakeupReasons_22058" 9 "WakeupReasons_49446" 10 "WakeupReasons_22060" 11 "WakeupReasons_269740" 12 "WakeupReasons_269735" 13 "WakeupReasons_269739" 14 "WakeupReasons_658500" 15 "WakeupReasons_21901" 16 "WakeupReasons_45793" 17 "WakeupReasons_45794" 18 "WakeupReasons_22005" 19 "WakeupReasons_22013" 20 "WakeupReasons_22100" 21 "WakeupReasons_45659" 22 "WakeupReasons_45657" 23 "WakeupReasons_140084" 24 "WakeupReasons_21973" 25 "WakeupReasons_91253" 26 "WakeupReasons_88123" 27 "WakeupReasons_88125" 28 "WakeupReasons_321583" 29 "WakeupReasons_74188" 30 "WakeupReasons_667945" 31 "WakeupReasons_169655" 32 "WakeupReasons_667948" 33 "WakeupReasons_168966" 34 "WakeupReasons_170865" 35 "WakeupReasons_197642" 36 "WakeupReasons_264876" 37 "WakeupReasons_191050" 38 "WakeupReasons_182033" 39 "WakeupReasons_200937" 40 "WakeupReasons_170807" 41 "WakeupReasons_319139" 42 "WakeupReasons_100298" 43 "WakeupReasons_100275" 44 "WakeupReasons_100300" 45 "WakeupReasons_100278" 46 "WakeupReasons_100281" 47 "WakeupReasons_265333" 48 "WakeupReasons_108776" 49 "WakeupReasons_176921" 50 "WakeupReasons_197826" 51 "WakeupReasons_185670" 52 "WakeupReasons_161066" 53 "WakeupReasons_200156" 54 "WakeupReasons_225696" 55 "WakeupReasons_21997" 56 "WakeupReasons_45656" 57 "WakeupReasons_266860" 58 "WakeupReasons_169894" 59 "WakeupReasons_320282" 60 "WakeupReasons_319422" 61 "WakeupReasons_320277" 62 "WakeupReasons_355601" 63 "WakeupReasons_360904" 64 "WakeupReasons_361505" 65 "WakeupReasons_361509" 66 "WakeupReasons_645094" 67 "WakeupReasons_68676" 68 "WakeupReasons_360008" 69 "WakeupReasons_109382" 70 "WakeupReasons_119273" 71 "WakeupReasons_224065" 72 "WakeupReasons_68644" 73 "WakeupReasons_109364" 74 "WakeupReasons_68481" 75 "WakeupReasons_224061" 76 "WakeupReasons_360006" 77 "WakeupReasons_138997" 78 "WakeupReasons_634696" 79 "WakeupReasons_645810" 80 "WakeupReasons_297868" 81 "WakeupReasons_315364" 82 "WakeupReasons_109367" 83 "WakeupReasons_320126" 84 "WakeupReasons_109387" 85 "WakeupReasons_634710" 86 "WakeupReasons_338820" 87 "WakeupReasons_67182" 88 "WakeupReasons_152237" 89 "WakeupReasons_145707" 90 "WakeupReasons_199172" 91 "WakeupReasons_144897" 92 "WakeupReasons_186489" 93 "WakeupReasons_144970" 94 "WakeupReasons_152786" 95 "WakeupReasons_264932" 96 "WakeupReasons_264934" 97 "WakeupReasons_356190" 98 "WakeupReasons_145688" 99 "WakeupReasons_95444" 100 "WakeupReasons_169945" 101 "WakeupReasons_140678" 102 "WakeupReasons_222553" 103 "WakeupReasons_224831" 104 "WakeupReasons_201815" 105 "WakeupReasons_45864" 106 "WakeupReasons_659549" 107 "WakeupReasons_45866" 108 "WakeupReasons_45867" 109 "WakeupReasons_169884" 110 "WakeupReasons_264962" 111 "WakeupReasons_201348" 112 "WakeupReasons_320287" 113 "WakeupReasons_156412" 114 "WakeupReasons_133749" 115 "WakeupReasons_355409" 116 "WakeupReasons_636692" 117 "WakeupReasons_533044" 118 "WakeupReasons_106774" 119 "WakeupReasons_145311" 120 "WakeupReasons_145319" 121 "WakeupReasons_152774" 122 "WakeupReasons_145330" 123 "WakeupReasons_145388" 124 "WakeupReasons_145399" 125 "WakeupReasons_145362" 126 "WakeupReasons_145385" 127 "WakeupReasons_145373" 128 "WakeupReasons_145288" 129 "WakeupReasons_145419" 130 "WakeupReasons_145454" 131 "WakeupReasons_145462" 132 "WakeupReasons_269156" 133 "WakeupReasons_300427" 134 "WakeupReasons_220322" 135 "WakeupReasons_224617" 136 "WakeupReasons_224634" 137 "WakeupReasons_300682" 138 "WakeupReasons_264958" 139 "WakeupReasons_160597" 140 "WakeupReasons_160602" 141 "WakeupReasons_108841" 142 "WakeupReasons_265569" 143 "WakeupReasons_526429" 144 "WakeupReasons_514545" 145 "WakeupReasons_265232" 146 "WakeupReasons_644550" 147 "WakeupReasons_317616" 148 "WakeupReasons_354791" 149 "WakeupReasons_320631" 150 "WakeupReasons_337565" 151 "WakeupReasons_532007" 152 "WakeupReasons_514503" 153 "WakeupReasons_299117" 154 "WakeupReasons_340667" 155 "WakeupReasons_321845" 156 "WakeupReasons_179103" 157 "WakeupReasons_108810" 158 "WakeupReasons_322857" 159 "WakeupReasons_658603" 160 "WakeupReasons_197648" 161 "WakeupReasons_160596" 162 "WakeupReasons_361272" 163 "WakeupReasons_361279" 164 "WakeupReasons_265305" 165 "WakeupReasons_265328" 166 "WakeupReasons_265330" 167 "WakeupReasons_298808" 168 "WakeupReasons_515804" 169 "WakeupReasons_514502" 170 "WakeupReasons_645753" 171 "WakeupReasons_646109" 172 "WakeupReasons_299547" 173 "WakeupReasons_318342" 174 "WakeupReasons_360543" 175 "WakeupReasons_356549" 176 "WakeupReasons_198484" 177 "WakeupReasons_300681" 178 "WakeupReasons_359211" 179 "WakeupReasons_534077" 180 "WakeupReasons_525705" 181 "WakeupReasons_360299" 182 "WakeupReasons_526445" 183 "WakeupReasons_534145" 184 "WakeupReasons_192030" 185 "WakeupReasons_652361" 186 "WakeupReasons_355214" 187 "WakeupReasons_321317" 188 "WakeupReasons_359187" 189 "WakeupReasons_321057" 190 "WakeupReasons_321319" 191 "WakeupReasons_321323" 192 "WakeupReasons_321077" 193 "WakeupReasons_320895" 194 "WakeupReasons_655340" 195 "WakeupReasons_636556" 196 "WakeupReasons_108834" 197 "WakeupReasons_265937" 198 "WakeupReasons_533050" 199 "WakeupReasons_526426" 200 "WakeupReasons_264712" 201 "WakeupReasons_319401" 202 "WakeupReasons_643973" 203 "WakeupReasons_223715" 204 "WakeupReasons_199159" 205 "WakeupReasons_318382" 206 "WakeupReasons_226967" 207 "WakeupReasons_531743" 208 "WakeupReasons_360542" 209 "WakeupReasons_264726" 210 "WakeupReasons_535214" 211 "WakeupReasons_335068" 212 "WakeupReasons_316796" 213 "WakeupReasons_526438" 214 "WakeupReasons_198433" 215 "WakeupReasons_225961" 216 "WakeupReasons_197665" 217 "WakeupReasons_224550" 218 "WakeupReasons_667962" 219 "WakeupReasons_667953" 220 "WakeupReasons_110885" 221 "WakeupReasons_224552" 222 "WakeupReasons_224553" 223 "WakeupReasons_652546" 224 "WakeupReasons_331194" 225 "WakeupReasons_667820" 226 "WakeupReasons_659350" 227 "WakeupReasons_101706" 228 "WakeupReasons_101725" 229 "WakeupReasons_101728" 230 "WakeupReasons_101727" 231 "WakeupReasons_166267" 232 "WakeupReasons_156440" 233 "WakeupReasons_95949" 234 "WakeupReasons_112799" 235 "WakeupReasons_146470" 236 "WakeupReasons_176748" 237 "WakeupReasons_223920" 238 "WakeupReasons_668531" 239 "WakeupReasons_670087" 240 "WakeupReasons_668529" 241 "WakeupReasons_45858" 242 "WakeupReasons_315981" 243 "WakeupReasons_533370" 244 "WakeupReasons_533371" 245 "WakeupReasons_533372" 246 "WakeupReasons_241902" 247 "WakeupReasons_359559" 248 "WakeupReasons_516327" 249 "WakeupReasons_533872" 250 "WakeupReasons_45856" 251 "WakeupReasons_45853" 252 "WakeupReasons_45854" 253 "WakeupReasons_45852" 254 "WakeupReasons_45851" 255 "WakeupReasons_45850" 256 "WakeupReasons_45849" 257 "WakeupReasons_636801" 258 "WakeupReasons_109466" 259 "WakeupReasons_109467" 260 "WakeupReasons_670345" 261 "WakeupReasons_NMPDUReceived" 262 "WakeupReasons_358832" 263 "WakeupReasons_200683" 264 "WakeupReasons_198452" 265 "WakeupReasons_185457" 266 "WakeupReasons_185490" 267 "WakeupReasons_4471" 268 "WakeupReasons_269034" 269 "WakeupReasons_215560" 270 "WakeupReasons_312881" 271 "WakeupReasons_269140" 272 "WakeupReasons_197653" 273 "WakeupReasons_337991" 274 "WakeupReasons_658188" 275 "WakeupReasons_674953" 276 "WakeupReasons_675064" 277 "WakeupReasons_674958" 278 "WakeupReasons_675494" 279 "WakeupReasons_675837" 280 "WakeupReasons_667879" 281 "WakeupReasons_667947" 282 "WakeupReasons_676265" 283 "WakeupReasons_669465" 284 "WakeupReasons_670928" 285 "WakeupReasons_669447" 286 "WakeupReasons_667922" 287 "WakeupReasons_670753" 288 "WakeupReasons_668395" 289 "WakeupReasons_668393" 290 "WakeupReasons_667850" 291 "WakeupReasons_667848" 292 "WakeupReasons_311279" 293 "WakeupReasons_182918" 294 "WakeupReasons_667988" 295 "WakeupReasons_532555" 296 "WakeupReasons_532556" 297 "WakeupReasons_113348" 298 "WakeupReasons_193474" 299 "WakeupReasons_667871" 300 "WakeupReasons_670966" 301 "WakeupReasons_667985" 302 "WakeupReasons_670354" 303 "WakeupReasons_46017" 304 "WakeupReasons_675742" 305 "WakeupReasons_106669" 306 "WakeupReasons_80609" 307 "WakeupReasons_199714" 308 "WakeupReasons_200090" 309 "WakeupReasons_139075" 310 "WakeupReasons_268983" 311 "WakeupReasons_265131" 312 "WakeupReasons_263473" 313 "WakeupReasons_45887" 314 "WakeupReasons_69678" 315 "WakeupReasons_69679" 316 "WakeupReasons_45897" 317 "WakeupReasons_45898" 318 "WakeupReasons_80608" 319 "WakeupReasons_45869" 320 "WakeupReasons_45870" 321 "WakeupReasons_45872" 322 "WakeupReasons_45875" 323 "WakeupReasons_45871" 324 "WakeupReasons_45876" 325 "WakeupReasons_667980" 326 "WakeupReasons_45877" 327 "WakeupReasons_667973" 328 "WakeupReasons_670962" 329 "WakeupReasons_45888" 330 "WakeupReasons_45890" 331 "WakeupReasons_667869" 332 "WakeupReasons_45846" 333 "WakeupReasons_45847" 334 "WakeupReasons_45848" 335 "WakeupReasons_262872" 336 "WakeupReasons_127924" 337 "WakeupReasons_127926" 338 "WakeupReasons_674223" 339 "WakeupReasons_667982" 340 "WakeupReasons_657121" 341 "WakeupReasons_265745" 342 "WakeupReasons_657120" 343 "WakeupReasons_675564" 344 "WakeupReasons_197644" 345 "WakeupReasons_264943" 346 "WakeupReasons_264697" 347 "WakeupReasons_69216" 348 "WakeupReasons_128671" 349 "WakeupReasons_356598" 350 "WakeupReasons_675745" 351 "WakeupReasons_667983" 352 "WakeupReasons_667987" 353 "WakeupReasons_75103" 354 "WakeupReasons_305818" 355 "WakeupReasons_670942" 356 "WakeupReasons_532932" 357 "WakeupReasons_532933" 358 "WakeupReasons_83199" 359 "WakeupReasons_45900" 360 "WakeupReasons_88458" 361 "WakeupReasons_329457" 362 "WakeupReasons_45902" 363 "WakeupReasons_224211" 364 "WakeupReasons_667981" 365 "WakeupReasons_667874" 366 "WakeupReasons_46020" 367 "WakeupReasons_667842" 368 "WakeupReasons_145161" 369 "WakeupReasons_233755" 370 "WakeupReasons_297056" 371 "WakeupReasons_264691" 372 "WakeupReasons_262871" 373 "WakeupReasons_264964" 374 "WakeupReasons_667872" 375 "WakeupReasons_45655" 376 "WakeupReasons_177214" 377 "WakeupReasons_671005" 378 "WakeupReasons_680712" 379 "WakeupReasons_669822" 380 "WakeupReasons_668523" 381 "WakeupReasons_680974" 382 "WakeupReasons_680975" 383 "WakeupReasons_681028" 384 "WakeupReasons_670462" 385 "WakeupReasons_681134" 386 "WakeupReasons_681031" 387 "WakeupReasons_681711" 388 "WakeupReasons_682034" 389 "WakeupReasons_674839" 390 "WakeupReasons_681915" 391 "WakeupReasons_682032" 392 "WakeupReasons_682037" 393 "WakeupReasons_682688" 394 "WakeupReasons_681789" 395 "WakeupReasons_682023" 396 "WakeupReasons_681023" 397 "WakeupReasons_676285" 398 "WakeupReasons_682077" 399 "WakeupReasons_682076" 400 "WakeupReasons_682078" 401 "WakeupReasons_682153" 402 "WakeupReasons_682155" 403 "WakeupReasons_682152" 404 "WakeupReasons_682154" 405 "WakeupReasons_682074";
VAL_ 341 TrsmParkLockdTrsmParkLockd 0 "TrsmParkLock1_ParkNotEngd" 1 "TrsmParkLock1_ParkEngd" 2 "TrsmParkLock1_NotInUse" 3 "TrsmParkLock1_Undefd";
VAL_ 305 DcDcActvdReq 0 "DcDcActvd_NoConversionToLVSide" 1 "DcDcActvd_ConversionToLVSide";
VAL_ 132 DchrgnIntState 0 "DchrgnIntState_NoInternalDischargerequest" 1 "DchrgnIntState_InternalDischarging" 2 "DchrgnIntState_InternalDischargingisnotallowed" 3 "DchrgnIntState_ExitInernalDischargwithoutfailure" 4 "DchrgnIntState_ExitInternalDischargingwithfailure" 5 "DchrgnIntState_IntDischrgnIsNotActv";
VAL_ 132 OnBdChrgrPwrEnaAllwd 0 "Boolean_FALSE" 1 "Boolean_TRUE";
VAL_ 369 HvBattCoolgCmd 0 "HVBattChargnCmd_OK" 1 "HVBattChargnCmd_NOK" 2 "HVBattChargnCmd_INIT" 3 "HVBattChargnCmd_HOLD";
VAL_ 369 HvOnMaiReq 0 "HvActvnSts_Open" 1 "HvActvnSts_Clsd" 2 "HvActvnSts_KeepSt" 3 "HvActvnSts_OpenAndReqActvDcha";
VAL_ 406 HvBattChrgnCmd 0 "HVBattChargnCmd_OK" 1 "HVBattChargnCmd_NOK" 2 "HVBattChargnCmd_INIT" 3 "HVBattChargnCmd_HOLD";
VAL_ 647 BookChargeSetResponse 0 "BookChargeSetResponse_Default" 1 "BookChargeSetResponse_Success" 2 "BookChargeSetResponse_Cancelled" 3 "BookChargeSetResponse_Fail";
VAL_ 647 ChrgnSts 0 "ChrgnSts_Fault" 1 "ChrgnSts_ChargingInParkingState" 2 "ChrgnSts_ChargingInDrivingState" 3 "ChrgnSts_NotCharging" 4 "ChrgnSts_ChargingCompleted" 5 "ChrgnSts_Invalid";
VAL_ 647 CmptmtCoolgSts 0 "CmptmtCoolgSts_OffNoReq" 1 "CmptmtCoolgSts_OffByEvaprTLo" 2 "CmptmtCoolgSts_OffByPLo" 3 "CmptmtCoolgSts_OffByAmbTOutOfRng" 4 "CmptmtCoolgSts_OffBySysFailr" 5 "CmptmtCoolgSts_OffByLoadCut" 6 "CmptmtCoolgSts_OnWithBattCoolg" 7 "CmptmtCoolgSts_On";
VAL_ 647 DchaStopReasonIndcn 0 "DchaStopReasonIndcn_Default" 1 "DchaStopReasonIndcn_StopWhenActvnDcha" 2 "DchaStopReasonIndcn_StopAfterWhile" 3 "DchaStopReasonIndcn_StopAlready";
VAL_ 647 MonrCycCmpl 0 "NotCmpl1_NotCmpl" 1 "NotCmpl1_Cmpl";
VAL_ 647 PrpsnSysActv 0 "NotCmpl1_NotCmpl" 1 "NotCmpl1_Cmpl";
VAL_ 392 HvBattThermReqFb 0 "HvBattThermReqFb_Default" 1 "HvBattThermReqFb_Heating" 2 "HvBattThermReqFb_HeatFinished" 3 "HvBattThermReqFb_RadiatorCooling" 4 "HvBattThermReqFb_CompressorCooling" 5 "HvBattThermReqFb_CoolingFinish" 6 "HvBattThermReqFb_Inhibited" 7 "HvBattThermReqFb_HeatingByEmotCoolt" 8 "HvBattThermReqFb_Fault";
SIG_GROUP_ 74 AccrPedlRat 1 : AccrPedlRatAccrPedlRat AccrPedlRatChks AccrPedlRatCntr;
SIG_GROUP_ 338 BECMCloudInfo 1 : BECMCloudInfoBattGndMosSwSts BECMCloudInfoBattNegMosSwSts BECMCloudInfoBattPosMosSwSts BECMCloudInfoBpsPressure BECMCloudInfoDcMainNegRlyU BECMCloudInfoDcMainPosRlyU BECMCloudInfoIsoNegHalfBrdgU BECMCloudInfoIsoPosHalfBrdgU BECMCloudInfoRelayDriveSts BECMCloudInfoStM;
SIG_GROUP_ 350 BECMHvU 1 : BECMHvUHvBusU BECMHvUHvFuseU BECMHvUHvNegRefU BECMHvUHvPreReU BECMHvUMainNegRlyRefU BECMHvUMainNegRlyU BECMHvUMainPosRlyU;
SIG_GROUP_ 1182 BECMPrpsnDataEvtA 1 : BECMPrpsnDataEvtACnt BECMPrpsnDataEvtAData1 BECMPrpsnDataEvtAData2 BECMPrpsnDataEvtAData3 BECMPrpsnDataEvtAData4 BECMPrpsnDataEvtAData5 BECMPrpsnDataEvtAData6 BECMPrpsnDataEvtAID;
SIG_GROUP_ 1187 BECMPrpsnDataPrdA 1 : BECMPrpsnDataPrdACnt BECMPrpsnDataPrdAData1 BECMPrpsnDataPrdAData2 BECMPrpsnDataPrdAData3 BECMPrpsnDataPrdAData4 BECMPrpsnDataPrdAData5 BECMPrpsnDataPrdAData6 BECMPrpsnDataPrdAData7;
SIG_GROUP_ 1190 BECMPrpsnDataPrdB 1 : BECMPrpsnDataPrdBCnt BECMPrpsnDataPrdBData1 BECMPrpsnDataPrdBData2 BECMPrpsnDataPrdBData3 BECMPrpsnDataPrdBData4 BECMPrpsnDataPrdBData5 BECMPrpsnDataPrdBData6 BECMPrpsnDataPrdBData7;
SIG_GROUP_ 1193 BECMPrpsnDataPrdC 1 : BECMPrpsnDataPrdCCnt BECMPrpsnDataPrdCData1 BECMPrpsnDataPrdCData2 BECMPrpsnDataPrdCData3 BECMPrpsnDataPrdCData4 BECMPrpsnDataPrdCData5 BECMPrpsnDataPrdCData6 BECMPrpsnDataPrdCData7;
SIG_GROUP_ 1195 BECMPrpsnDataPrdD 1 : BECMPrpsnDataPrdDCnt BECMPrpsnDataPrdDData1 BECMPrpsnDataPrdDData2 BECMPrpsnDataPrdDData3 BECMPrpsnDataPrdDData4 BECMPrpsnDataPrdDData5 BECMPrpsnDataPrdDData6 BECMPrpsnDataPrdDData7;
SIG_GROUP_ 1198 BECMPrpsnDataPrdE 1 : BECMPrpsnDataPrdECnt BECMPrpsnDataPrdEData1 BECMPrpsnDataPrdEData2 BECMPrpsnDataPrdEData3 BECMPrpsnDataPrdEData4 BECMPrpsnDataPrdEData5 BECMPrpsnDataPrdEData6 BECMPrpsnDataPrdEData7;
SIG_GROUP_ 1201 BECMPrpsnDataPrdF 1 : BECMPrpsnDataPrdFCnt BECMPrpsnDataPrdFData1 BECMPrpsnDataPrdFData2 BECMPrpsnDataPrdFData3 BECMPrpsnDataPrdFData4 BECMPrpsnDataPrdFData5 BECMPrpsnDataPrdFData6 BECMPrpsnDataPrdFData7;
SIG_GROUP_ 1203 BECMPrpsnDataPrdG 1 : BECMPrpsnDataPrdGCnt BECMPrpsnDataPrdGData1 BECMPrpsnDataPrdGData2 BECMPrpsnDataPrdGData3 BECMPrpsnDataPrdGData4 BECMPrpsnDataPrdGData5 BECMPrpsnDataPrdGData6 BECMPrpsnDataPrdGData7;
SIG_GROUP_ 339 CDDActSts 1 : CDDActStsDcDcIntSts CDDActStsDchaIntSts CDDActStsOnBdIntSts CDDActStsOnBdS2Sts;
SIG_GROUP_ 339 CDDCcCpInfo 1 : CDDCcCpInfoCcRes1 CDDCcCpInfoCpFrq CDDCcCpInfoCpInpDuty CDDCcCpInfoCpOutpDuty CDDCcCpInfoUCpPeak;
SIG_GROUP_ 346 CDDChipRstRsn 1 : CDDChipRstRsnC1ChipRstRsn CDDChipRstRsnC2ChipRstRsn CDDChipRstRsnC3ChipRstRsn;
SIG_GROUP_ 346 CDDLEDCtrl 1 : CDDLEDCtrlLEDBluCtrl CDDLEDCtrlLEDGrenCtrl CDDLEDCtrlLEDRedCtrl;
SIG_GROUP_ 360 CDDLockdUnlckdTyp 1 : CDDLockdUnlckdTypElockLockdTyp CDDLockdUnlckdTypElockUnlckdTyp;
SIG_GROUP_ 346 CDDRollCod 1 : CDDRollCodDcDcRollCod CDDRollCodDchaRollCod CDDRollCodOnBdRollCod;
SIG_GROUP_ 360 CDDSnsrSts 1 : CDDSnsrStsAcISnsrSts CDDSnsrStsAcUSnsrSts CDDSnsrStsHvISnsrSts CDDSnsrStsHvUSnsrSts CDDSnsrStsLvISnsrSts CDDSnsrStsPfcISnsrSts CDDSnsrStsPfcUSnsrSts;
SIG_GROUP_ 346 CDDSplyUAct 1 : CDDSplyUActDspSplyUAct CDDSplyUActMcuSplyUAct CDDSplyUActOnBdSplyUAct;
SIG_GROUP_ 339 DcChrgRlySts 1 : DcChrgRlyStsDCChrgRlyNegSts DcChrgRlyStsDCChrgRlyPosSts;
SIG_GROUP_ 785 DchaEgyStrg 1 : DchaEgyStrgDchaCarTiGlb DchaEgyStrgDchaEgy;
SIG_GROUP_ 656 HvBattCellTInfo 1 : HvBattCellTInfoHvBattSnsrT HvBattCellTInfoHvBattTMax HvBattCellTInfoHvBattTMin HvBattCellTInfoHvBattTSnsrNr HvBattCellTInfoHvTempSnsrTMaxsSerlNr HvBattCellTInfoHvTempSnsrTMinSerlNr;
SIG_GROUP_ 322 HvBattCellUInfo 1 : HvBattCellUInfoU1 HvBattCellUInfoU2 HvBattCellUInfoU3 HvBattCellUInfoU4;
SIG_GROUP_ 839 HvBattCod 1 : HvBattCodPackCodeX1 HvBattCodPackCodeX2 HvBattCodPackCodeX3 HvBattCodPackCodeX4 HvBattCodPackCodeX5 HvBattCodPackCodeX6 HvBattCodPackIndex;
SIG_GROUP_ 662 HvBattHeatStopReq 1 : HvBattHeatStopReqBrkLiOnReqChks HvBattHeatStopReqBrkLiOnReqCntr HvBattHeatStopReqBrkLiOnReqSts;
SIG_GROUP_ 789 HvBattT 1 : HvBattTAvg HvBattTMax HvBattTMin;
SIG_GROUP_ 321 HvSysRlySts 1 : HvSysRlyStsChks HvSysRlyStsCntr HvSysRlyStsHvSysRlySts;
SIG_GROUP_ 329 IDcDcActLoSide 1 : IDcDcActLoSideChks IDcDcActLoSideCntr IDcDcActLoSideIDcDcActLoSide;
SIG_GROUP_ 536 OnBdChrgrErrIndcnReq 1 : OnBdChrgrErrIndcnReqChks OnBdChrgrErrIndcnReqCntr OnBdChrgrErrIndcnReqOnBdChrgrErrIndcnReq;
SIG_GROUP_ 341 TrsmParkLockd 1 : TrsmParkLockdChks TrsmParkLockdCntr TrsmParkLockdTrsmParkLockd;
SIG_GROUP_ 1369 VFCVectorBECM 1 : VFCVectorBECMBlockID VFCVectorBECMVFCid0 VFCVectorBECMVFCid1 VFCVectorBECMVFCid10 VFCVectorBECMVFCid11 VFCVectorBECMVFCid12 VFCVectorBECMVFCid13 VFCVectorBECMVFCid14 VFCVectorBECMVFCid15 VFCVectorBECMVFCid16 VFCVectorBECMVFCid17 VFCVectorBECMVFCid18 VFCVectorBECMVFCid19 VFCVectorBECMVFCid2 VFCVectorBECMVFCid20 VFCVectorBECMVFCid21 VFCVectorBECMVFCid22 VFCVectorBECMVFCid23 VFCVectorBECMVFCid24 VFCVectorBECMVFCid25 VFCVectorBECMVFCid26 VFCVectorBECMVFCid27 VFCVectorBECMVFCid28 VFCVectorBECMVFCid29 VFCVectorBECMVFCid3 VFCVectorBECMVFCid30 VFCVectorBECMVFCid31 VFCVectorBECMVFCid32 VFCVectorBECMVFCid33 VFCVectorBECMVFCid34 VFCVectorBECMVFCid35 VFCVectorBECMVFCid36 VFCVectorBECMVFCid37 VFCVectorBECMVFCid38 VFCVectorBECMVFCid39 VFCVectorBECMVFCid4 VFCVectorBECMVFCid40 VFCVectorBECMVFCid41 VFCVectorBECMVFCid42 VFCVectorBECMVFCid43 VFCVectorBECMVFCid44 VFCVectorBECMVFCid45 VFCVectorBECMVFCid46 VFCVectorBECMVFCid47 VFCVectorBECMVFCid48 VFCVectorBECMVFCid49 VFCVectorBECMVFCid5 VFCVectorBECMVFCid50 VFCVectorBECMVFCid51 VFCVectorBECMVFCid52 VFCVectorBECMVFCid53 VFCVectorBECMVFCid54 VFCVectorBECMVFCid55 VFCVectorBECMVFCid56 VFCVectorBECMVFCid57 VFCVectorBECMVFCid58 VFCVectorBECMVFCid59 VFCVectorBECMVFCid6 VFCVectorBECMVFCid60 VFCVectorBECMVFCid61 VFCVectorBECMVFCid7 VFCVectorBECMVFCid8 VFCVectorBECMVFCid9;
SIG_GROUP_ 1391 VFCVectorCDD 1 : VFCVectorCDDBlockID VFCVectorCDDVFCid0 VFCVectorCDDVFCid1 VFCVectorCDDVFCid10 VFCVectorCDDVFCid11 VFCVectorCDDVFCid12 VFCVectorCDDVFCid13 VFCVectorCDDVFCid14 VFCVectorCDDVFCid15 VFCVectorCDDVFCid16 VFCVectorCDDVFCid17 VFCVectorCDDVFCid18 VFCVectorCDDVFCid19 VFCVectorCDDVFCid2 VFCVectorCDDVFCid20 VFCVectorCDDVFCid21 VFCVectorCDDVFCid22 VFCVectorCDDVFCid23 VFCVectorCDDVFCid24 VFCVectorCDDVFCid25 VFCVectorCDDVFCid26 VFCVectorCDDVFCid27 VFCVectorCDDVFCid28 VFCVectorCDDVFCid29 VFCVectorCDDVFCid3 VFCVectorCDDVFCid30 VFCVectorCDDVFCid31 VFCVectorCDDVFCid32 VFCVectorCDDVFCid33 VFCVectorCDDVFCid34 VFCVectorCDDVFCid35 VFCVectorCDDVFCid36 VFCVectorCDDVFCid37 VFCVectorCDDVFCid38 VFCVectorCDDVFCid39 VFCVectorCDDVFCid4 VFCVectorCDDVFCid40 VFCVectorCDDVFCid41 VFCVectorCDDVFCid42 VFCVectorCDDVFCid43 VFCVectorCDDVFCid44 VFCVectorCDDVFCid45 VFCVectorCDDVFCid46 VFCVectorCDDVFCid47 VFCVectorCDDVFCid48 VFCVectorCDDVFCid49 VFCVectorCDDVFCid5 VFCVectorCDDVFCid50 VFCVectorCDDVFCid51 VFCVectorCDDVFCid52 VFCVectorCDDVFCid53 VFCVectorCDDVFCid54 VFCVectorCDDVFCid55 VFCVectorCDDVFCid56 VFCVectorCDDVFCid57 VFCVectorCDDVFCid58 VFCVectorCDDVFCid59 VFCVectorCDDVFCid6 VFCVectorCDDVFCid60 VFCVectorCDDVFCid61 VFCVectorCDDVFCid7 VFCVectorCDDVFCid8 VFCVectorCDDVFCid9;
